VERSION ""

NS_ :

BS_:

BU_: Vector__XXX

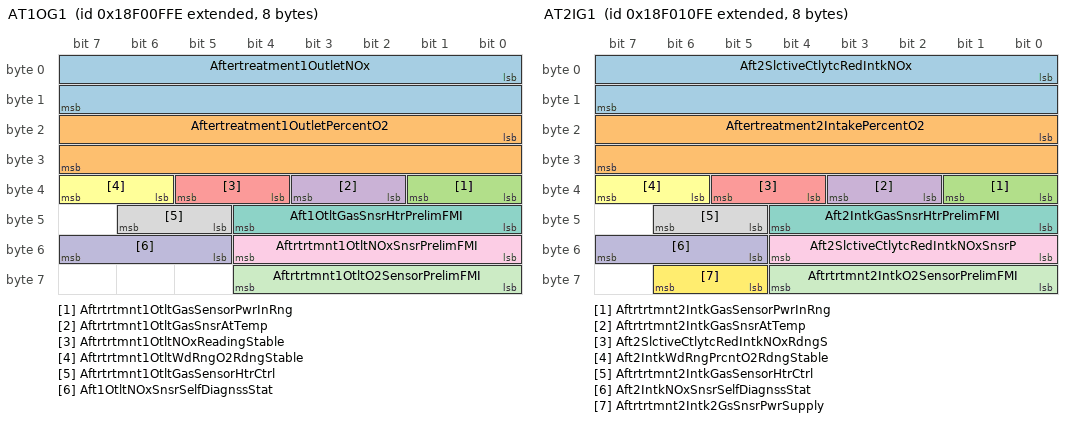
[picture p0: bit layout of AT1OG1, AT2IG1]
BO_ 2565869566 AT1OG1: 8 Vector__XXX
SG_ Aftertreatment1OutletNOx : 0|16@1+ (0.05,-200) [-200|3012.75] "ppm" Vector__XXX
SG_ Aftertreatment1OutletPercentO2 : 16|16@1+ (0.000514,-12) [-12|21.02707] "%" Vector__XXX
SG_ Aftrtrtmnt1OtltGasSensorPwrInRng : 32|2@1+ (1,0) [0|3] "" Vector__XXX
SG_ Aftrtrtmnt1OtltGasSnsrAtTemp : 34|2@1+ (1,0) [0|3] "" Vector__XXX
SG_ Aftrtrtmnt1OtltNOxReadingStable : 36|2@1+ (1,0) [0|3] "" Vector__XXX
SG_ Aftrtrtmnt1OtltWdRngO2RdngStable : 38|2@1+ (1,0) [0|3] "" Vector__XXX
SG_ Aft1OtltGasSnsrHtrPrelimFMI : 40|5@1+ (1,0) [0|31] "" Vector__XXX
SG_ Aftrtrtmnt1OtltGasSensorHtrCtrl : 45|2@1+ (1,0) [0|3] "" Vector__XXX
SG_ Aftrtrtmnt1OtltNOxSnsrPrelimFMI : 48|5@1+ (1,0) [0|31] "" Vector__XXX
SG_ Aft1OtltNOxSnsrSelfDiagnssStat : 53|3@1+ (1,0) [0|7] "" Vector__XXX
SG_ Aftrtrtmnt1OtltO2SensorPrelimFMI : 56|5@1+ (1,0) [0|31] "" Vector__XXX

BO_ 2565869822 AT2IG1: 8 Vector__XXX
SG_ Aft2SlctiveCtlytcRedIntkNOx : 0|16@1+ (0.05,-200) [-200|3012.75] "ppm" Vector__XXX
SG_ Aftertreatment2IntakePercentO2 : 16|16@1+ (0.000514,-12) [-12|21.02707] "%" Vector__XXX
SG_ Aftrtrtmnt2IntkGasSensorPwrInRng : 32|2@1+ (1,0) [0|3] "" Vector__XXX
SG_ Aftrtrtmnt2IntkGasSnsrAtTemp : 34|2@1+ (1,0) [0|3] "" Vector__XXX
SG_ Aft2SlctiveCtlytcRedIntkNOxRdngS : 36|2@1+ (1,0) [0|3] "" Vector__XXX
SG_ Aft2IntkWdRngPrcntO2RdngStable : 38|2@1+ (1,0) [0|3] "" Vector__XXX
SG_ Aft2IntkGasSnsrHtrPrelimFMI : 40|5@1+ (1,0) [0|31] "" Vector__XXX
SG_ Aftrtrtmnt2IntkGasSensorHtrCtrl : 45|2@1+ (1,0) [0|3] "" Vector__XXX
SG_ Aft2SlctiveCtlytcRedIntkNOxSnsrP : 48|5@1+ (1,0) [0|31] "" Vector__XXX
SG_ Aft2IntkNOxSnsrSelfDiagnssStat : 53|3@1+ (1,0) [0|7] "" Vector__XXX
SG_ Aftrtrtmnt2IntkO2SensorPrelimFMI : 56|5@1+ (1,0) [0|31] "" Vector__XXX
SG_ Aftrtrtmnt2Intk2GsSnsrPwrSupply : 61|2@1+ (1,0) [0|3] "" Vector__XXX

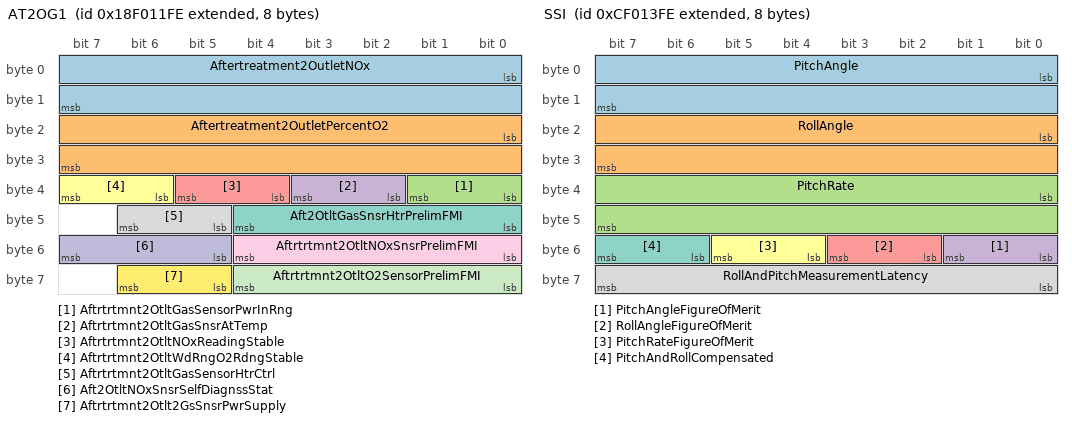
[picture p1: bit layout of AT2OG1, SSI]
BO_ 2565870078 AT2OG1: 8 Vector__XXX
SG_ Aftertreatment2OutletNOx : 0|16@1+ (0.05,-200) [-200|3012.75] "ppm" Vector__XXX
SG_ Aftertreatment2OutletPercentO2 : 16|16@1+ (0.000514,-12) [-12|21.02707] "%" Vector__XXX
SG_ Aftrtrtmnt2OtltGasSensorPwrInRng : 32|2@1+ (1,0) [0|3] "" Vector__XXX
SG_ Aftrtrtmnt2OtltGasSnsrAtTemp : 34|2@1+ (1,0) [0|3] "" Vector__XXX
SG_ Aftrtrtmnt2OtltNOxReadingStable : 36|2@1+ (1,0) [0|3] "" Vector__XXX
SG_ Aftrtrtmnt2OtltWdRngO2RdngStable : 38|2@1+ (1,0) [0|3] "" Vector__XXX
SG_ Aft2OtltGasSnsrHtrPrelimFMI : 40|5@1+ (1,0) [0|31] "" Vector__XXX
SG_ Aftrtrtmnt2OtltGasSensorHtrCtrl : 45|2@1+ (1,0) [0|3] "" Vector__XXX
SG_ Aftrtrtmnt2OtltNOxSnsrPrelimFMI : 48|5@1+ (1,0) [0|31] "" Vector__XXX
SG_ Aft2OtltNOxSnsrSelfDiagnssStat : 53|3@1+ (1,0) [0|7] "" Vector__XXX
SG_ Aftrtrtmnt2OtltO2SensorPrelimFMI : 56|5@1+ (1,0) [0|31] "" Vector__XXX
SG_ Aftrtrtmnt2Otlt2GsSnsrPwrSupply : 61|2@1+ (1,0) [0|3] "" Vector__XXX

BO_ 2565870334 FWSS1: 8 Vector__XXX
SG_ FifthWheelVerticalForce : 0|16@1+ (5,0) [0|321275] "N" Vector__XXX
SG_ FifthWheelDrawbarForce : 16|16@1+ (10,-320000) [-320000|322550] "N" Vector__XXX
SG_ FifthWheelRollMoment : 32|16@1+ (10,-320000) [-320000|322550] "N" Vector__XXX
SG_ FifthWheelRollWarningIndicator : 48|2@1+ (1,0) [0|3] "" Vector__XXX

BO_ 2364543998 SSI: 8 Vector__XXX
SG_ PitchAngle : 0|16@1+ (0.002,-64) [-64|64.51] "deg" Vector__XXX
SG_ RollAngle : 16|16@1+ (0.002,-64) [-64|64.51] "deg" Vector__XXX
SG_ PitchRate : 32|16@1+ (0.002,-64) [-64|64.51] "deg/s" Vector__XXX
SG_ PitchAngleFigureOfMerit : 48|2@1+ (1,0) [0|3] "" Vector__XXX
SG_ RollAngleFigureOfMerit : 50|2@1+ (1,0) [0|3] "" Vector__XXX
SG_ PitchRateFigureOfMerit : 52|2@1+ (1,0) [0|3] "" Vector__XXX
SG_ PitchAndRollCompensated : 54|2@1+ (1,0) [0|3] "" Vector__XXX
SG_ RollAndPitchMeasurementLatency : 56|8@1+ (0.5,0) [0|125] "ms" Vector__XXX

BO_ 2364544254 BI: 8 Vector__XXX
SG_ RelativeBladeHeight : 0|16@1+ (0.1,-3200) [-3200|3225.5] "mm" Vector__XXX
SG_ BladeRotationAngle : 16|16@1+ (0.0078125,-200) [-200|301.99] "deg" Vector__XXX
SG_ RelBldHghtAndBldRotAglMeasureLat : 32|8@1+ (0.5,0) [0|125] "ms" Vector__XXX
SG_ RelativeBladeHeightFigureOfMerit : 40|2@1+ (1,0) [0|3] "" Vector__XXX
SG_ BladeRotationAngleFigureOfMerit : 42|2@1+ (1,0) [0|3] "" Vector__XXX

BO_ 2364544510 RGTACRP: 8 Vector__XXX
SG_ RequestedGenTotalACReActvPower : 0|32@1+ (1,-2000000000) [-2000000000|2211081215] "VA" Vector__XXX
SG_ RequestedGenOverallPowerFactor : 32|16@1+ (6.103515625E-005,-1) [-1|2.921814] "" Vector__XXX
SG_ RqedGenOverallPwrFactorLagging : 48|2@1+ (1,0) [0|3] "" Vector__XXX

BO_ 2364544766 CCS: 8 Vector__XXX
SG_ EngineCylinder1CombustionStatus : 0|2@1+ (1,0) [0|3] "" Vector__XXX
SG_ EngineCylinder2CombustionStatus : 2|2@1+ (1,0) [0|3] "" Vector__XXX
SG_ EngineCylinder3CombustionStatus : 4|2@1+ (1,0) [0|3] "" Vector__XXX
SG_ EngineCylinder4CombustionStatus : 6|2@1+ (1,0) [0|3] "" Vector__XXX
SG_ EngineCylinder5CombustionStatus : 8|2@1+ (1,0) [0|3] "" Vector__XXX
SG_ EngineCylinder6CombustionStatus : 10|2@1+ (1,0) [0|3] "" Vector__XXX
SG_ EngineCylinder7CombustionStatus : 12|2@1+ (1,0) [0|3] "" Vector__XXX
SG_ EngineCylinder8CombustionStatus : 14|2@1+ (1,0) [0|3] "" Vector__XXX
SG_ EngineCylinder9CombustionStatus : 16|2@1+ (1,0) [0|3] "" Vector__XXX
SG_ EngineCylinder10CombustionStatus : 18|2@1+ (1,0) [0|3] "" Vector__XXX
SG_ EngineCylinder11CombustionStatus : 20|2@1+ (1,0) [0|3] "" Vector__XXX
SG_ EngineCylinder12CombustionStatus : 22|2@1+ (1,0) [0|3] "" Vector__XXX
SG_ EngineCylinder13CombustionStatus : 24|2@1+ (1,0) [0|3] "" Vector__XXX
SG_ EngineCylinder14CombustionStatus : 26|2@1+ (1,0) [0|3] "" Vector__XXX
SG_ EngineCylinder15CombustionStatus : 28|2@1+ (1,0) [0|3] "" Vector__XXX
SG_ EngineCylinder16CombustionStatus : 30|2@1+ (1,0) [0|3] "" Vector__XXX
SG_ EngineCylinder17CombustionStatus : 32|2@1+ (1,0) [0|3] "" Vector__XXX
SG_ EngineCylinder18CombustionStatus : 34|2@1+ (1,0) [0|3] "" Vector__XXX
SG_ EngineCylinder19CombustionStatus : 36|2@1+ (1,0) [0|3] "" Vector__XXX
SG_ EngineCylinder20CombustionStatus : 38|2@1+ (1,0) [0|3] "" Vector__XXX
SG_ EngineCylinder21CombustionStatus : 40|2@1+ (1,0) [0|3] "" Vector__XXX
SG_ EngineCylinder22CombustionStatus : 42|2@1+ (1,0) [0|3] "" Vector__XXX
SG_ EngineCylinder23CombustionStatus : 44|2@1+ (1,0) [0|3] "" Vector__XXX
SG_ EngineCylinder24CombustionStatus : 46|2@1+ (1,0) [0|3] "" Vector__XXX

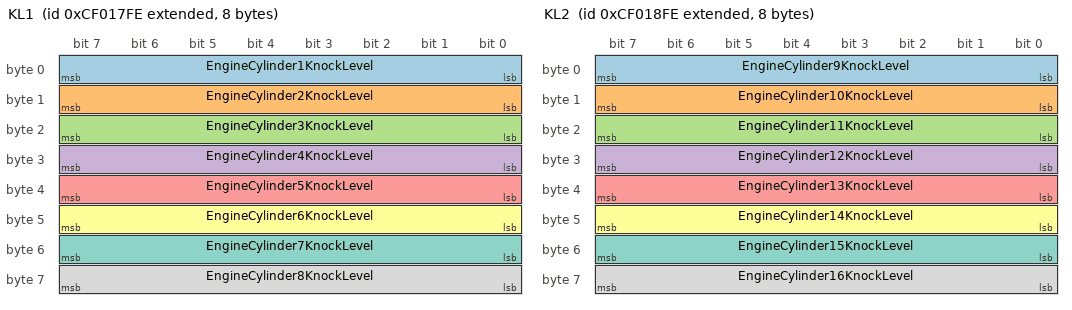
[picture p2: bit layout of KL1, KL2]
BO_ 2364545022 KL1: 8 Vector__XXX
SG_ EngineCylinder1KnockLevel : 0|8@1+ (1,0) [0|250] "%" Vector__XXX
SG_ EngineCylinder2KnockLevel : 8|8@1+ (1,0) [0|250] "%" Vector__XXX
SG_ EngineCylinder3KnockLevel : 16|8@1+ (1,0) [0|250] "%" Vector__XXX
SG_ EngineCylinder4KnockLevel : 24|8@1+ (1,0) [0|250] "%" Vector__XXX
SG_ EngineCylinder5KnockLevel : 32|8@1+ (1,0) [0|250] "%" Vector__XXX
SG_ EngineCylinder6KnockLevel : 40|8@1+ (1,0) [0|250] "%" Vector__XXX
SG_ EngineCylinder7KnockLevel : 48|8@1+ (1,0) [0|250] "%" Vector__XXX
SG_ EngineCylinder8KnockLevel : 56|8@1+ (1,0) [0|250] "%" Vector__XXX

BO_ 2364545278 KL2: 8 Vector__XXX
SG_ EngineCylinder9KnockLevel : 0|8@1+ (1,0) [0|250] "%" Vector__XXX
SG_ EngineCylinder10KnockLevel : 8|8@1+ (1,0) [0|250] "%" Vector__XXX
SG_ EngineCylinder11KnockLevel : 16|8@1+ (1,0) [0|250] "%" Vector__XXX
SG_ EngineCylinder12KnockLevel : 24|8@1+ (1,0) [0|250] "%" Vector__XXX
SG_ EngineCylinder13KnockLevel : 32|8@1+ (1,0) [0|250] "%" Vector__XXX
SG_ EngineCylinder14KnockLevel : 40|8@1+ (1,0) [0|250] "%" Vector__XXX
SG_ EngineCylinder15KnockLevel : 48|8@1+ (1,0) [0|250] "%" Vector__XXX
SG_ EngineCylinder16KnockLevel : 56|8@1+ (1,0) [0|250] "%" Vector__XXX

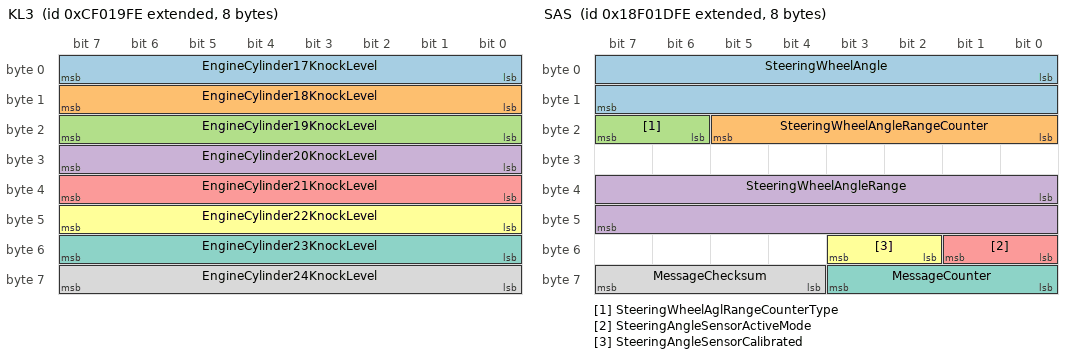
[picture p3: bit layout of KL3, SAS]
BO_ 2364545534 KL3: 8 Vector__XXX
SG_ EngineCylinder17KnockLevel : 0|8@1+ (1,0) [0|250] "%" Vector__XXX
SG_ EngineCylinder18KnockLevel : 8|8@1+ (1,0) [0|250] "%" Vector__XXX
SG_ EngineCylinder19KnockLevel : 16|8@1+ (1,0) [0|250] "%" Vector__XXX
SG_ EngineCylinder20KnockLevel : 24|8@1+ (1,0) [0|250] "%" Vector__XXX
SG_ EngineCylinder21KnockLevel : 32|8@1+ (1,0) [0|250] "%" Vector__XXX
SG_ EngineCylinder22KnockLevel : 40|8@1+ (1,0) [0|250] "%" Vector__XXX
SG_ EngineCylinder23KnockLevel : 48|8@1+ (1,0) [0|250] "%" Vector__XXX
SG_ EngineCylinder24KnockLevel : 56|8@1+ (1,0) [0|250] "%" Vector__XXX

BO_ 2431654654 TFAC: 8 Vector__XXX
SG_ EngineThrottleActr1ControlCmd : 0|16@1+ (0.0025,0) [0|160.6375] "%" Vector__XXX
SG_ EngineThrottleActr2ControlCmd : 16|16@1+ (0.0025,0) [0|160.6375] "%" Vector__XXX
SG_ EngineFuelActr1ControlCommand : 32|16@1+ (0.0025,0) [0|160.6375] "%" Vector__XXX
SG_ EngineFuelActr2ControlCommand : 48|16@1+ (0.0025,0) [0|160.6375] "%" Vector__XXX

BO_ 2364546302 RGAAC: 8 Vector__XXX
SG_ RqedGenAvrgLineLineACRMSVoltage : 0|32@1+ (0.0078125,0) [0|32899071] "V" Vector__XXX

BO_ 2565873150 SAS: 8 Vector__XXX
SG_ SteeringWheelAngle : 0|16@1+ (0.0009765625,-31.374) [-31.374|31.374] "rad" Vector__XXX
SG_ SteeringWheelAngleRangeCounter : 16|6@1+ (1,-32) [-32|29] "" Vector__XXX
SG_ SteeringWheelAglRangeCounterType : 22|2@1+ (1,0) [0|3] "" Vector__XXX
SG_ SteeringWheelAngleRange : 32|16@1+ (0.0009765625,-31.374) [-31.374|31.374] "rad" Vector__XXX
SG_ SteeringAngleSensorActiveMode : 48|2@1+ (1,0) [0|3] "" Vector__XXX
SG_ SteeringAngleSensorCalibrated : 50|2@1+ (1,0) [0|3] "" Vector__XXX
SG_ MessageCounter : 56|4@1+ (1,0) [0|15] "" Vector__XXX
SG_ MessageChecksum : 60|4@1+ (1,0) [0|15] "" Vector__XXX

BO_ 2364546814 GC2: 8 Vector__XXX
SG_ GeneratorGoverningBias : 0|16@1+ (0.004,-125) [-125|132.02] "%" Vector__XXX
SG_ EngineSelfInducedDerateInhibit : 16|2@1+ (1,0) [0|3] "" Vector__XXX
SG_ EngineLoadSetpointRequest : 24|16@1+ (0.5,0) [0|32127.5] "kW" Vector__XXX

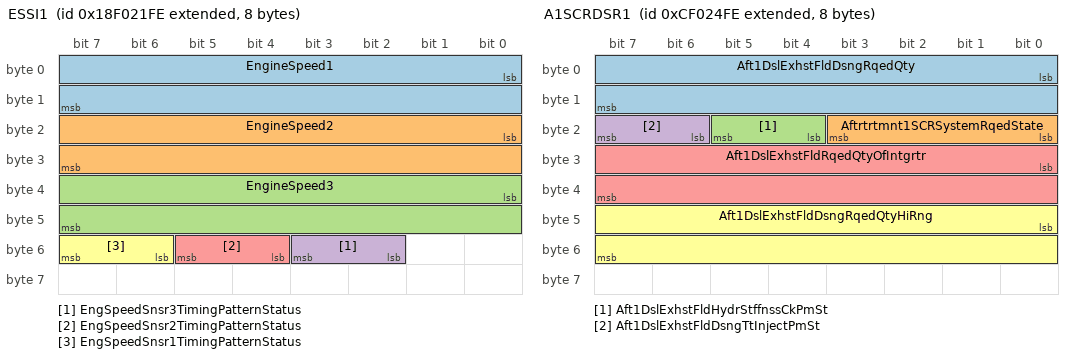
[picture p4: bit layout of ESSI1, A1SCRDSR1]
BO_ 2565874174 ESSI1: 8 Vector__XXX
SG_ EngineSpeed1 : 0|16@1+ (0.5,0) [0|32127.5] "rpm" Vector__XXX
SG_ EngineSpeed2 : 16|16@1+ (0.5,0) [0|32127.5] "rpm" Vector__XXX
SG_ EngineSpeed3 : 32|16@1+ (0.5,0) [0|32127.5] "rpm" Vector__XXX
SG_ EngSpeedSnsr3TimingPatternStatus : 50|2@1+ (1,0) [0|3] "" Vector__XXX
SG_ EngSpeedSnsr2TimingPatternStatus : 52|2@1+ (1,0) [0|3] "" Vector__XXX
SG_ EngSpeedSnsr1TimingPatternStatus : 54|2@1+ (1,0) [0|3] "" Vector__XXX

BO_ 2364548094 A1SCRDSI1: 8 Vector__XXX
SG_ Aft1DslExhstFldActlDsngQty : 0|16@1+ (0.3,0) [0|19276.5] "g/h" Vector__XXX
SG_ Aftertreatment1SCRSystemState : 16|4@1+ (1,0) [0|15] "" Vector__XXX
SG_ Aftertreatment1SCRSystem2State : 20|4@1+ (1,0) [0|15] "" Vector__XXX
SG_ Aft1DslExhstFldActlQtyOfIntgrtr : 24|16@1+ (0.1,0) [0|6425.5] "g" Vector__XXX
SG_ Aft1DslExhstFldDoserAbsPress : 40|8@1+ (8,0) [0|2000] "kPa" Vector__XXX
SG_ Aft1DslExhstFldActlDsngQtyHiRng : 48|16@1+ (0.05,0) [0|3212.75] "g/m" Vector__XXX

BO_ 2364548350 A1SCRDSR1: 8 Vector__XXX
SG_ Aft1DslExhstFldDsngRqedQty : 0|16@1+ (0.3,0) [0|19276.5] "g/h" Vector__XXX
SG_ Aftrtrtmnt1SCRSystemRqedState : 16|4@1+ (1,0) [0|15] "" Vector__XXX
SG_ Aft1DslExhstFldHydrStffnssCkPmSt : 20|2@1+ (1,0) [0|3] "" Vector__XXX
SG_ Aft1DslExhstFldDsngTtInjectPmSt : 22|2@1+ (1,0) [0|3] "" Vector__XXX
SG_ Aft1DslExhstFldRqedQtyOfIntgrtr : 24|16@1+ (0.1,0) [0|6425.5] "g" Vector__XXX
SG_ Aft1DslExhstFldDsngRqedQtyHiRng : 40|16@1+ (0.05,0) [0|3212.75] "g/m" Vector__XXX

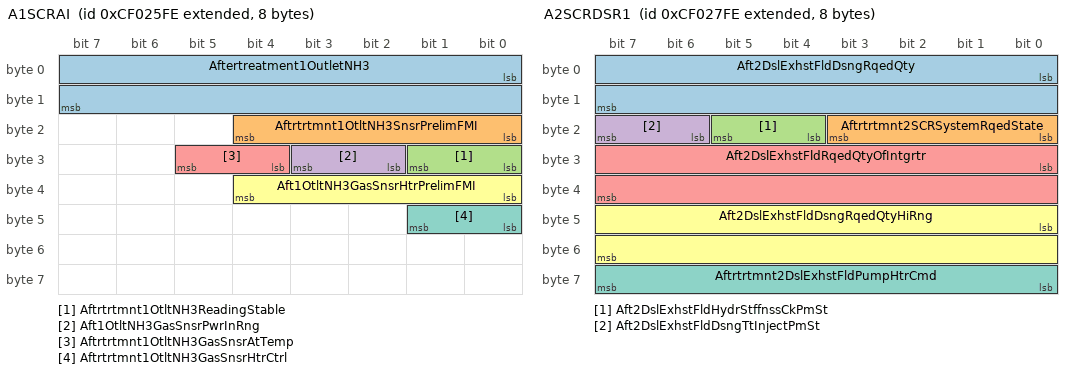
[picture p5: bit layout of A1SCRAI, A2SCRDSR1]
BO_ 2364548606 A1SCRAI: 8 Vector__XXX
SG_ Aftertreatment1OutletNH3 : 0|16@1+ (0.05,-200) [-200|3012.75] "ppm" Vector__XXX
SG_ Aftrtrtmnt1OtltNH3SnsrPrelimFMI : 16|5@1+ (1,0) [0|31] "" Vector__XXX
SG_ Aftrtrtmnt1OtltNH3ReadingStable : 24|2@1+ (1,0) [0|3] "" Vector__XXX
SG_ Aft1OtltNH3GasSnsrPwrInRng : 26|2@1+ (1,0) [0|3] "" Vector__XXX
SG_ Aftrtrtmnt1OtltNH3GasSnsrAtTemp : 28|2@1+ (1,0) [0|3] "" Vector__XXX
SG_ Aft1OtltNH3GasSnsrHtrPrelimFMI : 32|5@1+ (1,0) [0|31] "" Vector__XXX
SG_ Aftrtrtmnt1OtltNH3GasSnsrHtrCtrl : 40|2@1+ (1,0) [0|3] "" Vector__XXX

BO_ 2364548862 A2SCRDSI1: 8 Vector__XXX
SG_ Aft2DslExhstFldActlDsngQty : 0|16@1+ (0.3,0) [0|19276.5] "g/h" Vector__XXX
SG_ Aftertreatment2SCRSystemState : 16|4@1+ (1,0) [0|15] "" Vector__XXX
SG_ Aftertreatment2SCRSystem2State : 20|4@1+ (1,0) [0|15] "" Vector__XXX
SG_ Aft2DslExhstFldActlQtyOfIntgrtr : 24|16@1+ (0.1,0) [0|6425.5] "g" Vector__XXX
SG_ Aft2DslExhstFldDsngAbsPress : 40|8@1+ (8,0) [0|2000] "kPa" Vector__XXX
SG_ Aft2DslExhstFldActlDsngQtyHiRng : 48|16@1+ (0.05,0) [0|3212.75] "g/m" Vector__XXX

BO_ 2364549118 A2SCRDSR1: 8 Vector__XXX
SG_ Aft2DslExhstFldDsngRqedQty : 0|16@1+ (0.3,0) [0|19276.5] "g/h" Vector__XXX
SG_ Aftrtrtmnt2SCRSystemRqedState : 16|4@1+ (1,0) [0|15] "" Vector__XXX
SG_ Aft2DslExhstFldHydrStffnssCkPmSt : 20|2@1+ (1,0) [0|3] "" Vector__XXX
SG_ Aft2DslExhstFldDsngTtInjectPmSt : 22|2@1+ (1,0) [0|3] "" Vector__XXX
SG_ Aft2DslExhstFldRqedQtyOfIntgrtr : 24|16@1+ (0.1,0) [0|6425.5] "g" Vector__XXX
SG_ Aft2DslExhstFldDsngRqedQtyHiRng : 40|16@1+ (0.05,0) [0|3212.75] "g/m" Vector__XXX
SG_ Aftrtrtmnt2DslExhstFldPumpHtrCmd : 56|8@1+ (0.4,0) [0|100] "%" Vector__XXX

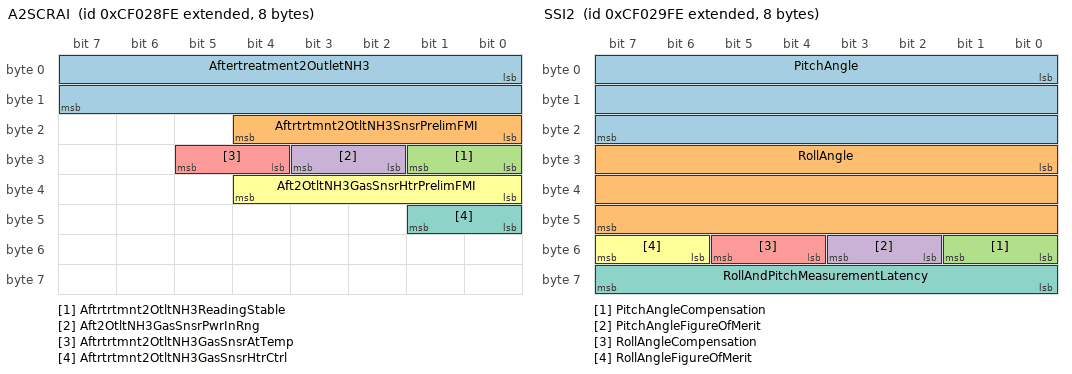
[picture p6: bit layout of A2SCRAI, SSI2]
BO_ 2364549374 A2SCRAI: 8 Vector__XXX
SG_ Aftertreatment2OutletNH3 : 0|16@1+ (0.05,-200) [-200|3012.75] "ppm" Vector__XXX
SG_ Aftrtrtmnt2OtltNH3SnsrPrelimFMI : 16|5@1+ (1,0) [0|31] "" Vector__XXX
SG_ Aftrtrtmnt2OtltNH3ReadingStable : 24|2@1+ (1,0) [0|3] "" Vector__XXX
SG_ Aft2OtltNH3GasSnsrPwrInRng : 26|2@1+ (1,0) [0|3] "" Vector__XXX
SG_ Aftrtrtmnt2OtltNH3GasSnsrAtTemp : 28|2@1+ (1,0) [0|3] "" Vector__XXX
SG_ Aft2OtltNH3GasSnsrHtrPrelimFMI : 32|5@1+ (1,0) [0|31] "" Vector__XXX
SG_ Aftrtrtmnt2OtltNH3GasSnsrHtrCtrl : 40|2@1+ (1,0) [0|3] "" Vector__XXX

BO_ 2364549630 SSI2: 8 Vector__XXX
SG_ PitchAngle : 0|24@1+ (3.0517578125E-005,-250) [-250|252] "deg" Vector__XXX
SG_ RollAngle : 24|24@1+ (3.0517578125E-005,-250) [-250|252] "deg" Vector__XXX
SG_ PitchAngleCompensation : 48|2@1+ (1,0) [0|3] "" Vector__XXX
SG_ PitchAngleFigureOfMerit : 50|2@1+ (1,0) [0|3] "" Vector__XXX
SG_ RollAngleCompensation : 52|2@1+ (1,0) [0|3] "" Vector__XXX
SG_ RollAngleFigureOfMerit : 54|2@1+ (1,0) [0|3] "" Vector__XXX
SG_ RollAndPitchMeasurementLatency : 56|8@1+ (0.5,0) [0|125] "ms" Vector__XXX

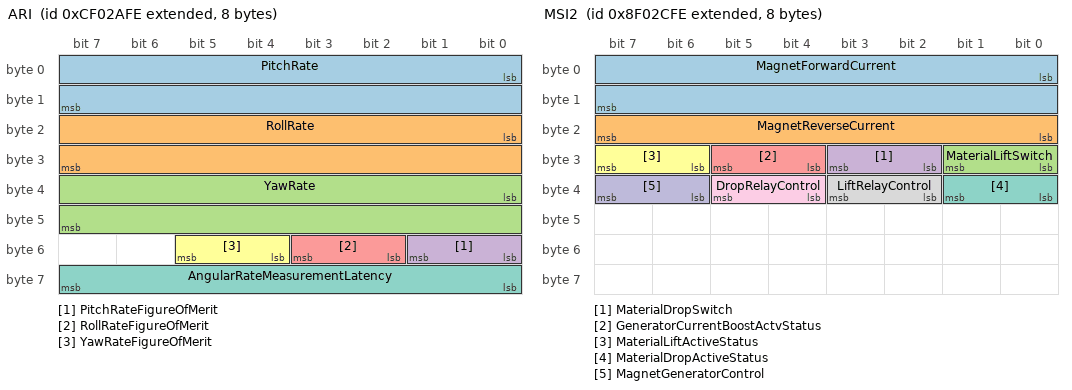
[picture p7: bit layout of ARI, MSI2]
BO_ 2364549886 ARI: 8 Vector__XXX
SG_ PitchRate : 0|16@1+ (0.0078125,-250) [-250|250.992] "deg/s" Vector__XXX
SG_ RollRate : 16|16@1+ (0.0078125,-250) [-250|250.992] "deg/s" Vector__XXX
SG_ YawRate : 32|16@1+ (0.0078125,-250) [-250|250.992] "deg/s" Vector__XXX
SG_ PitchRateFigureOfMerit : 48|2@1+ (1,0) [0|3] "" Vector__XXX
SG_ RollRateFigureOfMerit : 50|2@1+ (1,0) [0|3] "" Vector__XXX
SG_ YawRateFigureOfMerit : 52|2@1+ (1,0) [0|3] "" Vector__XXX
SG_ AngularRateMeasurementLatency : 56|8@1+ (0.5,0) [0|125] "ms" Vector__XXX

BO_ 2163223550 CN: 8 Vector__XXX
SG_ CrashType : 0|5@1+ (1,0) [0|31] "" Vector__XXX
SG_ CrashCounter : 56|4@1+ (1,0) [0|15] "" Vector__XXX
SG_ CrashChecksum : 60|4@1+ (1,0) [0|15] "" Vector__XXX

BO_ 2297441534 MSI2: 8 Vector__XXX
SG_ MagnetForwardCurrent : 0|16@1+ (1,0) [0|64255] "A" Vector__XXX
SG_ MagnetReverseCurrent : 16|8@1+ (1,0) [0|250] "A" Vector__XXX
SG_ MaterialLiftSwitch : 24|2@1+ (1,0) [0|3] "" Vector__XXX
SG_ MaterialDropSwitch : 26|2@1+ (1,0) [0|3] "" Vector__XXX
SG_ GeneratorCurrentBoostActvStatus : 28|2@1+ (1,0) [0|3] "" Vector__XXX
SG_ MaterialLiftActiveStatus : 30|2@1+ (1,0) [0|3] "" Vector__XXX
SG_ MaterialDropActiveStatus : 32|2@1+ (1,0) [0|3] "" Vector__XXX
SG_ LiftRelayControl : 34|2@1+ (1,0) [0|3] "" Vector__XXX
SG_ DropRelayControl : 36|2@1+ (1,0) [0|3] "" Vector__XXX
SG_ MagnetGeneratorControl : 38|2@1+ (1,0) [0|3] "" Vector__XXX

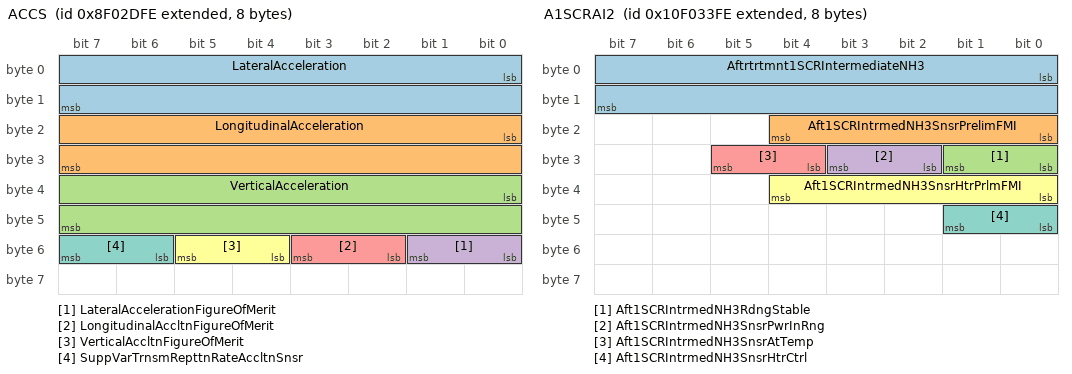
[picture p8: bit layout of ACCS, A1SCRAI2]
BO_ 2297441790 ACCS: 8 Vector__XXX
SG_ LateralAcceleration : 0|16@1+ (0.01,-320) [-320|322.55] "m/s^2" Vector__XXX
SG_ LongitudinalAcceleration : 16|16@1+ (0.01,-320) [-320|322.55] "m/s^2" Vector__XXX
SG_ VerticalAcceleration : 32|16@1+ (0.01,-320) [-320|322.55] "m/s^2" Vector__XXX
SG_ LateralAccelerationFigureOfMerit : 48|2@1+ (1,0) [0|3] "" Vector__XXX
SG_ LongitudinalAccltnFigureOfMerit : 50|2@1+ (1,0) [0|3] "" Vector__XXX
SG_ VerticalAccltnFigureOfMerit : 52|2@1+ (1,0) [0|3] "" Vector__XXX
SG_ SuppVarTrnsmRepttnRateAccltnSnsr : 54|2@1+ (1,0) [0|3] "" Vector__XXX

BO_ 2565877502 ETCC: 8 Vector__XXX
SG_ EngTurbochargerWastegateActr1Cmd : 0|16@1+ (0.0025,0) [0|160.6375] "%" Vector__XXX
SG_ EngTurbochargerWastegateActr2Cmd : 16|16@1+ (0.0025,0) [0|160.6375] "%" Vector__XXX
SG_ EngExhstPressureRegulatorCtrlCmd : 32|16@1+ (0.0025,0) [0|160.6375] "%" Vector__XXX
SG_ EngTurboCmprssorBlowoffActr1Cmd : 48|16@1+ (0.0025,0) [0|160.6375] "%" Vector__XXX

BO_ 2364551166 AEBS1: 8 Vector__XXX
SG_ AdvEmergencyBrakingSystemState : 0|4@1+ (1,0) [0|15] "" Vector__XXX
SG_ CollisionWarningLevel : 4|4@1+ (1,0) [0|15] "" Vector__XXX
SG_ RelvntObjDetctAdvEmrgncyBrkngSys : 8|3@1+ (1,0) [0|7] "" Vector__XXX
SG_ BendOffProbabilityOfRelevantObj : 11|3@1+ (1,0) [0|7] "" Vector__XXX
SG_ TimeToCollsnWithRelevantObject : 16|8@1+ (0.05,0) [0|12.5] "s" Vector__XXX

BO_ 2364551422 WS: 8 Vector__XXX
SG_ WirelessRollingMessageCounter : 0|16@1+ (1,0) [0|64255] "" Vector__XXX
SG_ TransmitterCommandState : 20|4@1+ (1,0) [0|15] "" Vector__XXX
SG_ TransmitterID1 : 24|24@1+ (1,0) [0|16449635] "" Vector__XXX
SG_ WirelessSignalStrength1 : 48|8@1+ (0.5,-125) [-125|0] "dBm" Vector__XXX

BO_ 2230333950 WAND: 8 Vector__XXX
SG_ WandAngle : 0|16@1+ (0.002,-64) [-64|64.51] "deg" Vector__XXX
SG_ WandSensorFigureOfMerit : 16|2@1+ (1,0) [0|3] "" Vector__XXX

BO_ 2230334206 LDISP: 8 Vector__XXX
SG_ MeasuredLinearDisplacement : 0|16@1+ (0.1,0) [0|6425.5] "mm" Vector__XXX
SG_ LnrDisplacmntSnsrSnsrFigOfMerit : 16|2@1+ (1,0) [0|3] "" Vector__XXX

BO_ 2431661054 A1SCRAI2: 8 Vector__XXX
SG_ Aftrtrtmnt1SCRIntermediateNH3 : 0|16@1+ (0.1,-200) [-200|6225.5] "ppm" Vector__XXX
SG_ Aft1SCRIntrmedNH3SnsrPrelimFMI : 16|5@1+ (1,0) [0|31] "" Vector__XXX
SG_ Aft1SCRIntrmedNH3RdngStable : 24|2@1+ (1,0) [0|3] "" Vector__XXX
SG_ Aft1SCRIntrmedNH3SnsrPwrInRng : 26|2@1+ (1,0) [0|3] "" Vector__XXX
SG_ Aft1SCRIntrmedNH3SnsrAtTemp : 28|2@1+ (1,0) [0|3] "" Vector__XXX
SG_ Aft1SCRIntrmedNH3SnsrHtrPrlmFMI : 32|5@1+ (1,0) [0|31] "" Vector__XXX
SG_ Aft1SCRIntrmedNH3SnsrHtrCtrl : 40|2@1+ (1,0) [0|3] "" Vector__XXX

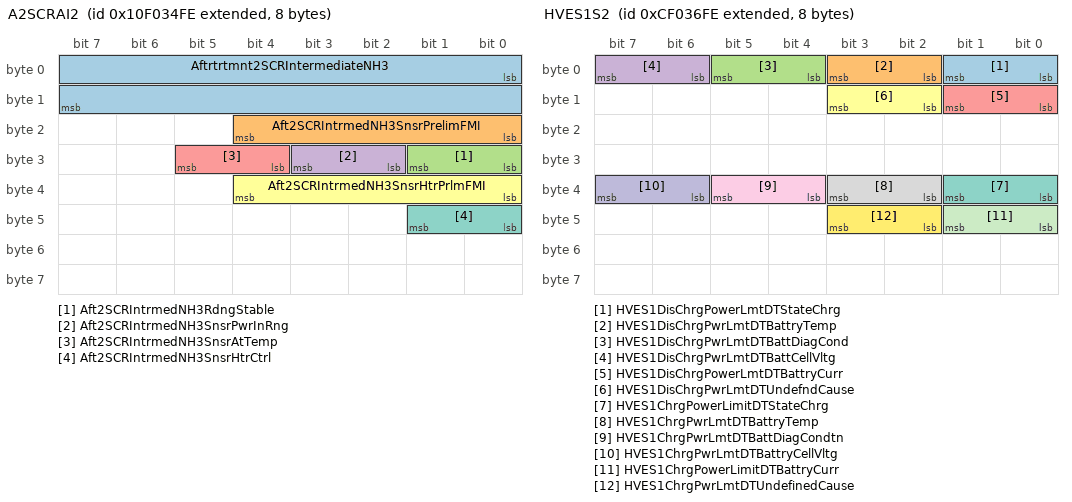
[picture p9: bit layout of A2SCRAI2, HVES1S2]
BO_ 2431661310 A2SCRAI2: 8 Vector__XXX
SG_ Aftrtrtmnt2SCRIntermediateNH3 : 0|16@1+ (0.1,-200) [-200|6225.5] "ppm" Vector__XXX
SG_ Aft2SCRIntrmedNH3SnsrPrelimFMI : 16|5@1+ (1,0) [0|31] "" Vector__XXX
SG_ Aft2SCRIntrmedNH3RdngStable : 24|2@1+ (1,0) [0|3] "" Vector__XXX
SG_ Aft2SCRIntrmedNH3SnsrPwrInRng : 26|2@1+ (1,0) [0|3] "" Vector__XXX
SG_ Aft2SCRIntrmedNH3SnsrAtTemp : 28|2@1+ (1,0) [0|3] "" Vector__XXX
SG_ Aft2SCRIntrmedNH3SnsrHtrPrlmFMI : 32|5@1+ (1,0) [0|31] "" Vector__XXX
SG_ Aft2SCRIntrmedNH3SnsrHtrCtrl : 40|2@1+ (1,0) [0|3] "" Vector__XXX

BO_ 2364552958 HVES1S2: 8 Vector__XXX
SG_ HVES1DisChrgPowerLmtDTStateChrg : 0|2@1+ (1,0) [0|3] "" Vector__XXX
SG_ HVES1DisChrgPwrLmtDTBattryTemp : 2|2@1+ (1,0) [0|3] "" Vector__XXX
SG_ HVES1DisChrgPwrLmtDTBattDiagCond : 4|2@1+ (1,0) [0|3] "" Vector__XXX
SG_ HVES1DisChrgPwrLmtDTBattCellVltg : 6|2@1+ (1,0) [0|3] "" Vector__XXX
SG_ HVES1DisChrgPowerLmtDTBattryCurr : 8|2@1+ (1,0) [0|3] "" Vector__XXX
SG_ HVES1DisChrgPwrLmtDTUndefndCause : 10|2@1+ (1,0) [0|3] "" Vector__XXX
SG_ HVES1ChrgPowerLimitDTStateChrg : 32|2@1+ (1,0) [0|3] "" Vector__XXX
SG_ HVES1ChrgPwrLmtDTBattryTemp : 34|2@1+ (1,0) [0|3] "" Vector__XXX
SG_ HVES1ChrgPwrLmtDTBattDiagCondtn : 36|2@1+ (1,0) [0|3] "" Vector__XXX
SG_ HVES1ChrgPwrLmtDTBattryCellVltg : 38|2@1+ (1,0) [0|3] "" Vector__XXX
SG_ HVES1ChrgPowerLimitDTBattryCurr : 40|2@1+ (1,0) [0|3] "" Vector__XXX
SG_ HVES1ChrgPwrLmtDTUndefinedCause : 42|2@1+ (1,0) [0|3] "" Vector__XXX

BO_ 2364553214 ETBA1: 8 Vector__XXX
SG_ EngTurboCmprBlowoffActr1PrlmFMI : 0|5@1+ (1,0) [0|31] "" Vector__XXX
SG_ EngTurboCmprBlowoffActr1TempStat : 5|3@1+ (1,0) [0|7] "" Vector__XXX
SG_ EngTurboCmprssorBlowoffActr1Temp : 8|8@1+ (1,-40) [-40|210] "deg C" Vector__XXX
SG_ EngTurboCmprBlowoffActr1DsrdPos : 16|8@1+ (0.4,0) [0|100] "%" Vector__XXX
SG_ EngTurboCmprssorBlowoffActr1Pos : 24|8@1+ (0.4,0) [0|100] "%" Vector__XXX
SG_ EngTurboCmprBlowoffActr1OpStat : 32|4@1+ (1,0) [0|15] "" Vector__XXX

BO_ 2364553470 ETFR: 8 Vector__XXX
SG_ EngGsSubstitutionFuelPrcntageCmd : 0|8@1+ (0.5,0) [0|125] "%" Vector__XXX
SG_ EngineCylinderGasMassFlowRateCmd : 8|16@1+ (6.103515625E-005,0) [0|3.921813965] "kg/s" Vector__XXX
SG_ EngineCylDieselMassFlowRateCmd : 24|16@1+ (6.103515625E-005,0) [0|3.921813965] "kg/s" Vector__XXX
SG_ EngineCylinderTorque : 40|16@1+ (1,0) [0|64255] "Nm" Vector__XXX
SG_ EngineDualFuelModeCommand : 56|2@1+ (1,0) [0|3] "" Vector__XXX

BO_ 2364553726 EASI: 8 Vector__XXX
SG_ EngineDesiredAirFuelRatio : 0|16@1+ (0.001,0) [0|64.255] "" Vector__XXX
SG_ EngineTotalIntakeMassAirFlowRate : 16|16@1+ (0.0009765625,0) [0|62.74902344] "kg/s" Vector__XXX
SG_ EngFuelSys2TtlIntkMassAirFlwRate : 32|16@1+ (0.0009765625,0) [0|62.74902344] "kg/s" Vector__XXX

BO_ 2364553982 ECCI1: 8 Vector__XXX
SG_ EngineCylinder1HeatRelease : 0|16@1+ (0.0001220703125,-1) [-1|6.84362793] "kJ/l" Vector__XXX
SG_ EngineCylinder1PeakPressure : 16|16@1+ (0.0009765625,0) [0|62.74902344] "MPa" Vector__XXX
SG_ EngineCyl1SynchronousKnockLevel : 32|8@1+ (1,0) [0|250] "%" Vector__XXX
SG_ EngCyl1PressureSensorPrelimFMI : 40|5@1+ (1,0) [0|31] "" Vector__XXX
SG_ EngineCyl1LowFrequencyKnockLevel : 48|8@1+ (1,0) [0|250] "%" Vector__XXX
SG_ EngCyl1MaxPressureIncreaseRate : 56|8@1+ (16,0) [0|4000] "kPa/deg crank an" Vector__XXX

BO_ 2364554238 ECCI2: 8 Vector__XXX
SG_ EngineCylinder2HeatRelease : 0|16@1+ (0.0001220703125,-1) [-1|6.84362793] "kJ/l" Vector__XXX
SG_ EngineCylinder2PeakPressure : 16|16@1+ (0.0009765625,0) [0|62.74902344] "MPa" Vector__XXX
SG_ EngineCyl2SynchronousKnockLevel : 32|8@1+ (1,0) [0|250] "%" Vector__XXX
SG_ EngCyl2PressureSensorPrelimFMI : 40|5@1+ (1,0) [0|31] "" Vector__XXX
SG_ EngineCyl2LowFrequencyKnockLevel : 48|8@1+ (1,0) [0|250] "%" Vector__XXX
SG_ EngCyl2MaxPressureIncreaseRate : 56|8@1+ (16,0) [0|4000] "kPa/deg crank an" Vector__XXX

BO_ 2364554494 ECCI3: 8 Vector__XXX
SG_ EngineCylinder3HeatRelease : 0|16@1+ (0.0001220703125,-1) [-1|6.84362793] "kJ/l" Vector__XXX
SG_ EngineCylinder3PeakPressure : 16|16@1+ (0.0009765625,0) [0|62.74902344] "MPa" Vector__XXX
SG_ EngineCyl3SynchronousKnockLevel : 32|8@1+ (1,0) [0|250] "%" Vector__XXX
SG_ EngCyl3PressureSensorPrelimFMI : 40|5@1+ (1,0) [0|31] "" Vector__XXX
SG_ EngineCyl3LowFrequencyKnockLevel : 48|8@1+ (1,0) [0|250] "%" Vector__XXX
SG_ EngCyl3MaxPressureIncreaseRate : 56|8@1+ (16,0) [0|4000] "kPa/deg crank an" Vector__XXX

BO_ 2364554750 ECCI4: 8 Vector__XXX
SG_ EngineCylinder4HeatRelease : 0|16@1+ (0.0001220703125,-1) [-1|6.84362793] "kJ/l" Vector__XXX
SG_ EngineCylinder4PeakPressure : 16|16@1+ (0.0009765625,0) [0|62.74902344] "MPa" Vector__XXX
SG_ EngineCyl4SynchronousKnockLevel : 32|8@1+ (1,0) [0|250] "%" Vector__XXX
SG_ EngCyl4PressureSensorPrelimFMI : 40|5@1+ (1,0) [0|31] "" Vector__XXX
SG_ EngineCyl4LowFrequencyKnockLevel : 48|8@1+ (1,0) [0|250] "%" Vector__XXX
SG_ EngCyl4MaxPressureIncreaseRate : 56|8@1+ (16,0) [0|4000] "kPa/deg crank an" Vector__XXX

BO_ 2364555006 ECCI5: 8 Vector__XXX
SG_ EngineCylinder5HeatRelease : 0|16@1+ (0.0001220703125,-1) [-1|6.84362793] "kJ/l" Vector__XXX
SG_ EngineCylinder5PeakPressure : 16|16@1+ (0.0009765625,0) [0|62.74902344] "MPa" Vector__XXX
SG_ EngineCyl5SynchronousKnockLevel : 32|8@1+ (1,0) [0|250] "%" Vector__XXX
SG_ EngCyl5PressureSensorPrelimFMI : 40|5@1+ (1,0) [0|31] "" Vector__XXX
SG_ EngineCyl5LowFrequencyKnockLevel : 48|8@1+ (1,0) [0|250] "%" Vector__XXX
SG_ EngCyl5MaxPressureIncreaseRate : 56|8@1+ (16,0) [0|4000] "kPa/deg crank an" Vector__XXX

BO_ 2364555262 ECCI6: 8 Vector__XXX
SG_ EngineCylinder6HeatRelease : 0|16@1+ (0.0001220703125,-1) [-1|6.84362793] "kJ/l" Vector__XXX
SG_ EngineCylinder6PeakPressure : 16|16@1+ (0.0009765625,0) [0|62.74902344] "MPa" Vector__XXX
SG_ EngineCyl6SynchronousKnockLevel : 32|8@1+ (1,0) [0|250] "%" Vector__XXX
SG_ EngCyl6PressureSensorPrelimFMI : 40|5@1+ (1,0) [0|31] "" Vector__XXX
SG_ EngineCyl6LowFrequencyKnockLevel : 48|8@1+ (1,0) [0|250] "%" Vector__XXX
SG_ EngCyl6MaxPressureIncreaseRate : 56|8@1+ (16,0) [0|4000] "kPa/deg crank an" Vector__XXX

BO_ 2364555518 ECCI7: 8 Vector__XXX
SG_ EngineCylinder7HeatRelease : 0|16@1+ (0.0001220703125,-1) [-1|6.84362793] "kJ/l" Vector__XXX
SG_ EngineCylinder7PeakPressure : 16|16@1+ (0.0009765625,0) [0|62.74902344] "MPa" Vector__XXX
SG_ EngineCyl7SynchronousKnockLevel : 32|8@1+ (1,0) [0|250] "%" Vector__XXX
SG_ EngCyl7PressureSensorPrelimFMI : 40|5@1+ (1,0) [0|31] "" Vector__XXX
SG_ EngineCyl7LowFrequencyKnockLevel : 48|8@1+ (1,0) [0|250] "%" Vector__XXX
SG_ EngCyl7MaxPressureIncreaseRate : 56|8@1+ (16,0) [0|4000] "kPa/deg crank an" Vector__XXX

BO_ 2364555774 ECCI8: 8 Vector__XXX
SG_ EngineCylinder8HeatRelease : 0|16@1+ (0.0001220703125,-1) [-1|6.84362793] "kJ/l" Vector__XXX
SG_ EngineCylinder8PeakPressure : 16|16@1+ (0.0009765625,0) [0|62.74902344] "MPa" Vector__XXX
SG_ EngineCyl8SynchronousKnockLevel : 32|8@1+ (1,0) [0|250] "%" Vector__XXX
SG_ EngCyl8PressureSensorPrelimFMI : 40|5@1+ (1,0) [0|31] "" Vector__XXX
SG_ EngineCyl8LowFrequencyKnockLevel : 48|8@1+ (1,0) [0|250] "%" Vector__XXX
SG_ EngCyl8MaxPressureIncreaseRate : 56|8@1+ (16,0) [0|4000] "kPa/deg crank an" Vector__XXX

BO_ 2364556030 ECCI9: 8 Vector__XXX
SG_ EngineCylinder9HeatRelease : 0|16@1+ (0.0001220703125,-1) [-1|6.84362793] "kJ/l" Vector__XXX
SG_ EngineCylinder9PeakPressure : 16|16@1+ (0.0009765625,0) [0|62.74902344] "MPa" Vector__XXX
SG_ EngineCyl9SynchronousKnockLevel : 32|8@1+ (1,0) [0|250] "%" Vector__XXX
SG_ EngCyl9PressureSensorPrelimFMI : 40|5@1+ (1,0) [0|31] "" Vector__XXX
SG_ EngineCyl9LowFrequencyKnockLevel : 48|8@1+ (1,0) [0|250] "%" Vector__XXX
SG_ EngCyl9MaxPressureIncreaseRate : 56|8@1+ (16,0) [0|4000] "kPa/deg crank an" Vector__XXX

BO_ 2364556286 ECCI10: 8 Vector__XXX
SG_ EngineCylinder10HeatRelease : 0|16@1+ (0.0001220703125,-1) [-1|6.84362793] "kJ/l" Vector__XXX
SG_ EngineCylinder10PeakPressure : 16|16@1+ (0.0009765625,0) [0|62.74902344] "MPa" Vector__XXX
SG_ EngineCyl10SynchronousKnockLevel : 32|8@1+ (1,0) [0|250] "%" Vector__XXX
SG_ EngCyl10PressureSensorPrelimFMI : 40|5@1+ (1,0) [0|31] "" Vector__XXX
SG_ EngCyl10LowFrequencyKnockLevel : 48|8@1+ (1,0) [0|250] "%" Vector__XXX
SG_ EngCyl10MaxPressureIncreaseRate : 56|8@1+ (16,0) [0|4000] "kPa/deg crank an" Vector__XXX

BO_ 2364556542 ECCI11: 8 Vector__XXX
SG_ EngineCylinder11HeatRelease : 0|16@1+ (0.0001220703125,-1) [-1|6.84362793] "kJ/l" Vector__XXX
SG_ EngineCylinder11PeakPressure : 16|16@1+ (0.0009765625,0) [0|62.74902344] "MPa" Vector__XXX
SG_ EngineCyl11SynchronousKnockLevel : 32|8@1+ (1,0) [0|250] "%" Vector__XXX
SG_ EngCyl11PressureSensorPrelimFMI : 40|5@1+ (1,0) [0|31] "" Vector__XXX
SG_ EngCyl11LowFrequencyKnockLevel : 48|8@1+ (1,0) [0|250] "%" Vector__XXX
SG_ EngCyl11MaxPressureIncreaseRate : 56|8@1+ (16,0) [0|4000] "kPa/deg crank an" Vector__XXX

BO_ 2364556798 ECCI12: 8 Vector__XXX
SG_ EngineCylinder12HeatRelease : 0|16@1+ (0.0001220703125,-1) [-1|6.84362793] "kJ/l" Vector__XXX
SG_ EngineCylinder12PeakPressure : 16|16@1+ (0.0009765625,0) [0|62.74902344] "MPa" Vector__XXX
SG_ EngineCyl12SynchronousKnockLevel : 32|8@1+ (1,0) [0|250] "%" Vector__XXX
SG_ EngCyl12PressureSensorPrelimFMI : 40|5@1+ (1,0) [0|31] "" Vector__XXX
SG_ EngCyl12LowFrequencyKnockLevel : 48|8@1+ (1,0) [0|250] "%" Vector__XXX
SG_ EngCyl12MaxPressureIncreaseRate : 56|8@1+ (16,0) [0|4000] "kPa/deg crank an" Vector__XXX

BO_ 2364557054 ECCI13: 8 Vector__XXX
SG_ EngineCylinder13HeatRelease : 0|16@1+ (0.0001220703125,-1) [-1|6.84362793] "kJ/l" Vector__XXX
SG_ EngineCylinder13PeakPressure : 16|16@1+ (0.0009765625,0) [0|62.74902344] "MPa" Vector__XXX
SG_ EngineCyl13SynchronousKnockLevel : 32|8@1+ (1,0) [0|250] "%" Vector__XXX
SG_ EngCyl13PressureSensorPrelimFMI : 40|5@1+ (1,0) [0|31] "" Vector__XXX
SG_ EngCyl13LowFrequencyKnockLevel : 48|8@1+ (1,0) [0|250] "%" Vector__XXX
SG_ EngCyl13MaxPressureIncreaseRate : 56|8@1+ (16,0) [0|4000] "kPa/deg crank an" Vector__XXX

BO_ 2364557310 ECCI14: 8 Vector__XXX
SG_ EngineCylinder14HeatRelease : 0|16@1+ (0.0001220703125,-1) [-1|6.84362793] "kJ/l" Vector__XXX
SG_ EngineCylinder14PeakPressure : 16|16@1+ (0.0009765625,0) [0|62.74902344] "MPa" Vector__XXX
SG_ EngineCyl14SynchronousKnockLevel : 32|8@1+ (1,0) [0|250] "%" Vector__XXX
SG_ EngCyl14PressureSensorPrelimFMI : 40|5@1+ (1,0) [0|31] "" Vector__XXX
SG_ EngCyl14LowFrequencyKnockLevel : 48|8@1+ (1,0) [0|250] "%" Vector__XXX
SG_ EngCyl14MaxPressureIncreaseRate : 56|8@1+ (16,0) [0|4000] "kPa/deg crank an" Vector__XXX

BO_ 2364557566 ECCI15: 8 Vector__XXX
SG_ EngineCylinder15HeatRelease : 0|16@1+ (0.0001220703125,-1) [-1|6.84362793] "kJ/l" Vector__XXX
SG_ EngineCylinder15PeakPressure : 16|16@1+ (0.0009765625,0) [0|62.74902344] "MPa" Vector__XXX
SG_ EngineCyl15SynchronousKnockLevel : 32|8@1+ (1,0) [0|250] "%" Vector__XXX
SG_ EngCyl15PressureSensorPrelimFMI : 40|5@1+ (1,0) [0|31] "" Vector__XXX
SG_ EngCyl15LowFrequencyKnockLevel : 48|8@1+ (1,0) [0|250] "%" Vector__XXX
SG_ EngCyl15MaxPressureIncreaseRate : 56|8@1+ (16,0) [0|4000] "kPa/deg crank an" Vector__XXX

BO_ 2364557822 ECCI16: 8 Vector__XXX
SG_ EngineCylinder16HeatRelease : 0|16@1+ (0.0001220703125,-1) [-1|6.84362793] "kJ/l" Vector__XXX
SG_ EngineCylinder16PeakPressure : 16|16@1+ (0.0009765625,0) [0|62.74902344] "MPa" Vector__XXX
SG_ EngineCyl16SynchronousKnockLevel : 32|8@1+ (1,0) [0|250] "%" Vector__XXX
SG_ EngCyl16PressureSensorPrelimFMI : 40|5@1+ (1,0) [0|31] "" Vector__XXX
SG_ EngCyl16LowFrequencyKnockLevel : 48|8@1+ (1,0) [0|250] "%" Vector__XXX
SG_ EngCyl16MaxPressureIncreaseRate : 56|8@1+ (16,0) [0|4000] "kPa/deg crank an" Vector__XXX

BO_ 2364558078 ECCI17: 8 Vector__XXX
SG_ EngineCylinder17HeatRelease : 0|16@1+ (0.0001220703125,-1) [-1|6.84362793] "kJ/l" Vector__XXX
SG_ EngineCylinder17PeakPressure : 16|16@1+ (0.0009765625,0) [0|62.74902344] "MPa" Vector__XXX
SG_ EngineCyl17SynchronousKnockLevel : 32|8@1+ (1,0) [0|250] "%" Vector__XXX
SG_ EngCyl17PressureSensorPrelimFMI : 40|5@1+ (1,0) [0|31] "" Vector__XXX
SG_ EngCyl17LowFrequencyKnockLevel : 48|8@1+ (1,0) [0|250] "%" Vector__XXX
SG_ EngCyl17MaxPressureIncreaseRate : 56|8@1+ (16,0) [0|4000] "kPa/deg crank an" Vector__XXX

BO_ 2364558334 ECCI18: 8 Vector__XXX
SG_ EngineCylinder18HeatRelease : 0|16@1+ (0.0001220703125,-1) [-1|6.84362793] "kJ/l" Vector__XXX
SG_ EngineCylinder18PeakPressure : 16|16@1+ (0.0009765625,0) [0|62.74902344] "MPa" Vector__XXX
SG_ EngineCyl18SynchronousKnockLevel : 32|8@1+ (1,0) [0|250] "%" Vector__XXX
SG_ EngCyl18PressureSensorPrelimFMI : 40|5@1+ (1,0) [0|31] "" Vector__XXX
SG_ EngCyl18LowFrequencyKnockLevel : 48|8@1+ (1,0) [0|250] "%" Vector__XXX
SG_ EngCyl18MaxPressureIncreaseRate : 56|8@1+ (16,0) [0|4000] "kPa/deg crank an" Vector__XXX

BO_ 2364558590 ECCI19: 8 Vector__XXX
SG_ EngineCylinder19HeatRelease : 0|16@1+ (0.0001220703125,-1) [-1|6.84362793] "kJ/l" Vector__XXX
SG_ EngineCylinder19PeakPressure : 16|16@1+ (0.0009765625,0) [0|62.74902344] "MPa" Vector__XXX
SG_ EngineCyl19SynchronousKnockLevel : 32|8@1+ (1,0) [0|250] "%" Vector__XXX
SG_ EngCyl19PressureSensorPrelimFMI : 40|5@1+ (1,0) [0|31] "" Vector__XXX
SG_ EngCyl19LowFrequencyKnockLevel : 48|8@1+ (1,0) [0|250] "%" Vector__XXX
SG_ EngCyl19MaxPressureIncreaseRate : 56|8@1+ (16,0) [0|4000] "kPa/deg crank an" Vector__XXX

BO_ 2364558846 ECCI20: 8 Vector__XXX
SG_ EngineCylinder20HeatRelease : 0|16@1+ (0.0001220703125,-1) [-1|6.84362793] "kJ/l" Vector__XXX
SG_ EngineCylinder20PeakPressure : 16|16@1+ (0.0009765625,0) [0|62.74902344] "MPa" Vector__XXX
SG_ EngineCyl20SynchronousKnockLevel : 32|8@1+ (1,0) [0|250] "%" Vector__XXX
SG_ EngCyl20PressureSensorPrelimFMI : 40|5@1+ (1,0) [0|31] "" Vector__XXX
SG_ EngCyl20LowFrequencyKnockLevel : 48|8@1+ (1,0) [0|250] "%" Vector__XXX
SG_ EngCyl20MaxPressureIncreaseRate : 56|8@1+ (16,0) [0|4000] "kPa/deg crank an" Vector__XXX

BO_ 2498776830 ECCAI1: 8 Vector__XXX
SG_ EngCyl1IndicatedMeanEffectivePrs : 0|16@1+ (0.0001220703125,-1) [-1|6.84362793] "MPa" Vector__XXX
SG_ EngCyl1AvrgStartCombustionTiming : 16|16@1+ (0.0078125,-250) [-250|250.992] "deg" Vector__XXX
SG_ EngCyl1AvrgCntrCombustionTiming : 32|16@1+ (0.0078125,-250) [-250|250.992] "deg" Vector__XXX
SG_ EngineCyl1AvrgCombustionDuration : 48|16@1+ (0.0078125,0) [0|501.99] "deg" Vector__XXX

BO_ 2498777086 ECCAI2: 8 Vector__XXX
SG_ EngCyl2IndicatedMeanEffectivePrs : 0|16@1+ (0.0001220703125,-1) [-1|6.84362793] "MPa" Vector__XXX
SG_ EngCyl2AvrgStartCombustionTiming : 16|16@1+ (0.0078125,-250) [-250|250.992] "deg" Vector__XXX
SG_ EngCyl2AvrgCntrCombustionTiming : 32|16@1+ (0.0078125,-250) [-250|250.992] "deg" Vector__XXX
SG_ EngineCyl2AvrgCombustionDuration : 48|16@1+ (0.0078125,0) [0|501.99] "deg" Vector__XXX

BO_ 2498777342 ECCAI3: 8 Vector__XXX
SG_ EngCyl3IndicatedMeanEffectivePrs : 0|16@1+ (0.0001220703125,-1) [-1|6.84362793] "MPa" Vector__XXX
SG_ EngCyl3AvrgStartCombustionTiming : 16|16@1+ (0.0078125,-250) [-250|250.992] "deg" Vector__XXX
SG_ EngCyl3AvrgCntrCombustionTiming : 32|16@1+ (0.0078125,-250) [-250|250.992] "deg" Vector__XXX
SG_ EngineCyl3AvrgCombustionDuration : 48|16@1+ (0.0078125,0) [0|501.99] "deg" Vector__XXX

BO_ 2498777598 ECCAI4: 8 Vector__XXX
SG_ EngCyl4IndicatedMeanEffectivePrs : 0|16@1+ (0.0001220703125,-1) [-1|6.84362793] "MPa" Vector__XXX
SG_ EngCyl4AvrgStartCombustionTiming : 16|16@1+ (0.0078125,-250) [-250|250.992] "deg" Vector__XXX
SG_ EngCyl4AvrgCntrCombustionTiming : 32|16@1+ (0.0078125,-250) [-250|250.992] "deg" Vector__XXX
SG_ EngineCyl4AvrgCombustionDuration : 48|16@1+ (0.0078125,0) [0|501.99] "deg" Vector__XXX

BO_ 2498777854 ECCAI5: 8 Vector__XXX
SG_ EngCyl5IndicatedMeanEffectivePrs : 0|16@1+ (0.0001220703125,-1) [-1|6.84362793] "MPa" Vector__XXX
SG_ EngCyl5AvrgStartCombustionTiming : 16|16@1+ (0.0078125,-250) [-250|250.992] "deg" Vector__XXX
SG_ EngCyl5AvrgCntrCombustionTiming : 32|16@1+ (0.0078125,-250) [-250|250.992] "deg" Vector__XXX
SG_ EngineCyl5AvrgCombustionDuration : 48|16@1+ (0.0078125,0) [0|501.99] "deg" Vector__XXX

BO_ 2498778110 ECCAI6: 8 Vector__XXX
SG_ EngCyl6IndicatedMeanEffectivePrs : 0|16@1+ (0.0001220703125,-1) [-1|6.84362793] "MPa" Vector__XXX
SG_ EngCyl6AvrgStartCombustionTiming : 16|16@1+ (0.0078125,-250) [-250|250.992] "deg" Vector__XXX
SG_ EngCyl6AvrgCntrCombustionTiming : 32|16@1+ (0.0078125,-250) [-250|250.992] "deg" Vector__XXX
SG_ EngineCyl6AvrgCombustionDuration : 48|16@1+ (0.0078125,0) [0|501.99] "deg" Vector__XXX

BO_ 2498778366 ECCAI7: 8 Vector__XXX
SG_ EngCyl7IndicatedMeanEffectivePrs : 0|16@1+ (0.0001220703125,-1) [-1|6.84362793] "MPa" Vector__XXX
SG_ EngCyl7AvrgStartCombustionTiming : 16|16@1+ (0.0078125,-250) [-250|250.992] "deg" Vector__XXX
SG_ EngCyl7AvrgCntrCombustionTiming : 32|16@1+ (0.0078125,-250) [-250|250.992] "deg" Vector__XXX
SG_ EngineCyl7AvrgCombustionDuration : 48|16@1+ (0.0078125,0) [0|501.99] "deg" Vector__XXX

BO_ 2498778622 ECCAI8: 8 Vector__XXX
SG_ EngCyl8IndicatedMeanEffectivePrs : 0|16@1+ (0.0001220703125,-1) [-1|6.84362793] "MPa" Vector__XXX
SG_ EngCyl8AvrgStartCombustionTiming : 16|16@1+ (0.0078125,-250) [-250|250.992] "deg" Vector__XXX
SG_ EngCyl8AvrgCntrCombustionTiming : 32|16@1+ (0.0078125,-250) [-250|250.992] "deg" Vector__XXX
SG_ EngineCyl8AvrgCombustionDuration : 48|16@1+ (0.0078125,0) [0|501.99] "deg" Vector__XXX

BO_ 2498778878 ECCAI9: 8 Vector__XXX
SG_ EngCyl9IndicatedMeanEffectivePrs : 0|16@1+ (0.0001220703125,-1) [-1|6.84362793] "MPa" Vector__XXX
SG_ EngCyl9AvrgStartCombustionTiming : 16|16@1+ (0.0078125,-250) [-250|250.992] "deg" Vector__XXX
SG_ EngCyl9AvrgCntrCombustionTiming : 32|16@1+ (0.0078125,-250) [-250|250.992] "deg" Vector__XXX
SG_ EngineCyl9AvrgCombustionDuration : 48|16@1+ (0.0078125,0) [0|501.99] "deg" Vector__XXX

BO_ 2498779134 ECCAI10: 8 Vector__XXX
SG_ EngCyl10IndicatedMeanEffectPrs : 0|16@1+ (0.0001220703125,-1) [-1|6.84362793] "MPa" Vector__XXX
SG_ EngCyl10AvrgStrtOfCombustionTmng : 16|16@1+ (0.0078125,-250) [-250|250.992] "deg" Vector__XXX
SG_ EngCyl10AvrgCntrOfCombustionTmng : 32|16@1+ (0.0078125,-250) [-250|250.992] "deg" Vector__XXX
SG_ EngCyl10AvrgCombustionDuration : 48|16@1+ (0.0078125,0) [0|501.99] "deg" Vector__XXX

BO_ 2498779390 ECCAI11: 8 Vector__XXX
SG_ EngCyl11IndicatedMeanEffectPrs : 0|16@1+ (0.0001220703125,-1) [-1|6.84362793] "MPa" Vector__XXX
SG_ EngCyl11AvrgStrtOfCombustionTmng : 16|16@1+ (0.0078125,-250) [-250|250.992] "deg" Vector__XXX
SG_ EngCyl11AvrgCntrOfCombustionTmng : 32|16@1+ (0.0078125,-250) [-250|250.992] "deg" Vector__XXX
SG_ EngCyl11AvrgCombustionDuration : 48|16@1+ (0.0078125,0) [0|501.99] "deg" Vector__XXX

BO_ 2498779646 ECCAI12: 8 Vector__XXX
SG_ EngCyl12IndicatedMeanEffectPrs : 0|16@1+ (0.0001220703125,-1) [-1|6.84362793] "MPa" Vector__XXX
SG_ EngCyl12AvrgStrtOfCombustionTmng : 16|16@1+ (0.0078125,-250) [-250|250.992] "deg" Vector__XXX
SG_ EngCyl12AvrgCntrOfCombustionTmng : 32|16@1+ (0.0078125,-250) [-250|250.992] "deg" Vector__XXX
SG_ EngCyl12AvrgCombustionDuration : 48|16@1+ (0.0078125,0) [0|501.99] "deg" Vector__XXX

BO_ 2498779902 ECCAI13: 8 Vector__XXX
SG_ EngCyl13IndicatedMeanEffectPrs : 0|16@1+ (0.0001220703125,-1) [-1|6.84362793] "MPa" Vector__XXX
SG_ EngCyl13AvrgStrtOfCombustionTmng : 16|16@1+ (0.0078125,-250) [-250|250.992] "deg" Vector__XXX
SG_ EngCyl13AvrgCntrOfCombustionTmng : 32|16@1+ (0.0078125,-250) [-250|250.992] "deg" Vector__XXX
SG_ EngCyl13AvrgCombustionDuration : 48|16@1+ (0.0078125,0) [0|501.99] "deg" Vector__XXX

BO_ 2498780158 ECCAI14: 8 Vector__XXX
SG_ EngCyl14IndicatedMeanEffectPrs : 0|16@1+ (0.0001220703125,-1) [-1|6.84362793] "MPa" Vector__XXX
SG_ EngCyl14AvrgStrtOfCombustionTmng : 16|16@1+ (0.0078125,-250) [-250|250.992] "deg" Vector__XXX
SG_ EngCyl14AvrgCntrOfCombustionTmng : 32|16@1+ (0.0078125,-250) [-250|250.992] "deg" Vector__XXX
SG_ EngCyl14AvrgCombustionDuration : 48|16@1+ (0.0078125,0) [0|501.99] "deg" Vector__XXX

BO_ 2498780414 ECCAI15: 8 Vector__XXX
SG_ EngCyl15IndicatedMeanEffectPrs : 0|16@1+ (0.0001220703125,-1) [-1|6.84362793] "MPa" Vector__XXX
SG_ EngCyl15AvrgStrtOfCombustionTmng : 16|16@1+ (0.0078125,-250) [-250|250.992] "deg" Vector__XXX
SG_ EngCyl15AvrgCntrOfCombustionTmng : 32|16@1+ (0.0078125,-250) [-250|250.992] "deg" Vector__XXX
SG_ EngCyl15AvrgCombustionDuration : 48|16@1+ (0.0078125,0) [0|501.99] "deg" Vector__XXX

BO_ 2498780670 ECCAI16: 8 Vector__XXX
SG_ EngCyl16IndicatedMeanEffectPrs : 0|16@1+ (0.0001220703125,-1) [-1|6.84362793] "MPa" Vector__XXX
SG_ EngCyl16AvrgStrtOfCombustionTmng : 16|16@1+ (0.0078125,-250) [-250|250.992] "deg" Vector__XXX
SG_ EngCyl16AvrgCntrOfCombustionTmng : 32|16@1+ (0.0078125,-250) [-250|250.992] "deg" Vector__XXX
SG_ EngCyl16AvrgCombustionDuration : 48|16@1+ (0.0078125,0) [0|501.99] "deg" Vector__XXX

BO_ 2498780926 ECCAI17: 8 Vector__XXX
SG_ EngCyl17IndicatedMeanEffectPrs : 0|16@1+ (0.0001220703125,-1) [-1|6.84362793] "MPa" Vector__XXX
SG_ EngCyl17AvrgStrtOfCombustionTmng : 16|16@1+ (0.0078125,-250) [-250|250.992] "deg" Vector__XXX
SG_ EngCyl17AvrgCntrOfCombustionTmng : 32|16@1+ (0.0078125,-250) [-250|250.992] "deg" Vector__XXX
SG_ EngCyl17AvrgCombustionDuration : 48|16@1+ (0.0078125,0) [0|501.99] "deg" Vector__XXX

BO_ 2498781182 ECCAI18: 8 Vector__XXX
SG_ EngCyl18IndicatedMeanEffectPrs : 0|16@1+ (0.0001220703125,-1) [-1|6.84362793] "MPa" Vector__XXX
SG_ EngCyl18AvrgStrtOfCombustionTmng : 16|16@1+ (0.0078125,-250) [-250|250.992] "deg" Vector__XXX
SG_ EngCyl18AvrgCntrOfCombustionTmng : 32|16@1+ (0.0078125,-250) [-250|250.992] "deg" Vector__XXX
SG_ EngCyl18AvrgCombustionDuration : 48|16@1+ (0.0078125,0) [0|501.99] "deg" Vector__XXX

BO_ 2498781438 ECCAI19: 8 Vector__XXX
SG_ EngCyl19IndicatedMeanEffectPrs : 0|16@1+ (0.0001220703125,-1) [-1|6.84362793] "MPa" Vector__XXX
SG_ EngCyl19AvrgStrtOfCombustionTmng : 16|16@1+ (0.0078125,-250) [-250|250.992] "deg" Vector__XXX
SG_ EngCyl19AvrgCntrOfCombustionTmng : 32|16@1+ (0.0078125,-250) [-250|250.992] "deg" Vector__XXX
SG_ EngCyl19AvrgCombustionDuration : 48|16@1+ (0.0078125,0) [0|501.99] "deg" Vector__XXX

BO_ 2498781694 ECCAI20: 8 Vector__XXX
SG_ EngCyl20IndicatedMeanEffectPrs : 0|16@1+ (0.0001220703125,-1) [-1|6.84362793] "MPa" Vector__XXX
SG_ EngCyl20AvrgStrtOfCombustionTmng : 16|16@1+ (0.0078125,-250) [-250|250.992] "deg" Vector__XXX
SG_ EngCyl20AvrgCntrOfCombustionTmng : 32|16@1+ (0.0078125,-250) [-250|250.992] "deg" Vector__XXX
SG_ EngCyl20AvrgCombustionDuration : 48|16@1+ (0.0078125,0) [0|501.99] "deg" Vector__XXX

BO_ 2297455358 ETC12: 8 Vector__XXX
SG_ TransmissionHydrostaticLp1Press : 0|16@1+ (1,0) [0|64255] "kPa" Vector__XXX
SG_ TransmissionHydrostaticLp2Press : 16|16@1+ (1,0) [0|64255] "kPa" Vector__XXX
SG_ TrnsmDirectionalOutptShftSpd : 32|16@1+ (1,-32127) [-32127|32128] "rpm" Vector__XXX
SG_ TransmissionIntrmedShaftSpeed : 48|16@1+ (0.125,0) [0|8031.875] "rpm" Vector__XXX

BO_ 2364564478 GFI5: 8 Vector__XXX
SG_ EngGseousFuelVlvNomDurationCmd : 0|16@1+ (2,0) [0|128510] "us" Vector__XXX
SG_ EngGseousFuelVlvNomStrtOfActCmd : 16|16@1+ (0.0078125,-400) [-400|101.99] "deg" Vector__XXX

BO_ 2364564734 EGFVDC1: 8 Vector__XXX
SG_ EngGaseousFuelValve1DurationCmd : 0|16@1+ (2,0) [0|128510] "us" Vector__XXX
SG_ EngGaseousFuelValve2DurationCmd : 16|16@1+ (2,0) [0|128510] "us" Vector__XXX
SG_ EngGaseousFuelValve3DurationCmd : 32|16@1+ (2,0) [0|128510] "us" Vector__XXX
SG_ EngGaseousFuelValve4DurationCmd : 48|16@1+ (2,0) [0|128510] "us" Vector__XXX

BO_ 2364564990 EGFVDC2: 8 Vector__XXX
SG_ EngGaseousFuelValve5DurationCmd : 0|16@1+ (2,0) [0|128510] "us" Vector__XXX
SG_ EngGaseousFuelValve6DurationCmd : 16|16@1+ (2,0) [0|128510] "us" Vector__XXX
SG_ EngGaseousFuelValve7DurationCmd : 32|16@1+ (2,0) [0|128510] "us" Vector__XXX
SG_ EngGaseousFuelValve8DurationCmd : 48|16@1+ (2,0) [0|128510] "us" Vector__XXX

BO_ 2364565246 EGFVDC3: 8 Vector__XXX
SG_ EngGaseousFuelValve9DurationCmd : 0|16@1+ (2,0) [0|128510] "us" Vector__XXX
SG_ EngGaseousFuelValve10DurationCmd : 16|16@1+ (2,0) [0|128510] "us" Vector__XXX
SG_ EngGaseousFuelValve11DurationCmd : 32|16@1+ (2,0) [0|128510] "us" Vector__XXX
SG_ EngGaseousFuelValve12DurationCmd : 48|16@1+ (2,0) [0|128510] "us" Vector__XXX

BO_ 2364565502 EGFVDC4: 8 Vector__XXX
SG_ EngGaseousFuelValve13DurationCmd : 0|16@1+ (2,0) [0|128510] "us" Vector__XXX
SG_ EngGaseousFuelValve14DurationCmd : 16|16@1+ (2,0) [0|128510] "us" Vector__XXX
SG_ EngGaseousFuelValve15DurationCmd : 32|16@1+ (2,0) [0|128510] "us" Vector__XXX
SG_ EngGaseousFuelValve16DurationCmd : 48|16@1+ (2,0) [0|128510] "us" Vector__XXX

BO_ 2364565758 EGFVDC5: 8 Vector__XXX
SG_ EngGaseousFuelValve17DurationCmd : 0|16@1+ (2,0) [0|128510] "us" Vector__XXX
SG_ EngGaseousFuelValve18DurationCmd : 16|16@1+ (2,0) [0|128510] "us" Vector__XXX
SG_ EngGaseousFuelValve19DurationCmd : 32|16@1+ (2,0) [0|128510] "us" Vector__XXX
SG_ EngGaseousFuelValve20DurationCmd : 48|16@1+ (2,0) [0|128510] "us" Vector__XXX

BO_ 2364566014 EGFVSOAC1: 8 Vector__XXX
SG_ EngGaseousFuelVlv1StartOfActCmd : 0|16@1+ (0.0078125,-400) [-400|101.99] "deg" Vector__XXX
SG_ EngGaseousFuelVlv2StartOfActCmd : 16|16@1+ (0.0078125,-400) [-400|101.99] "deg" Vector__XXX
SG_ EngGaseousFuelVlv3StartOfActCmd : 32|16@1+ (0.0078125,-400) [-400|101.99] "deg" Vector__XXX
SG_ EngGaseousFuelVlv4StartOfActCmd : 48|16@1+ (0.0078125,-400) [-400|101.99] "deg" Vector__XXX

BO_ 2364566270 EGFVSOAC2: 8 Vector__XXX
SG_ EngGaseousFuelVlv5StartOfActCmd : 0|16@1+ (0.0078125,-400) [-400|101.99] "deg" Vector__XXX
SG_ EngGaseousFuelVlv6StartOfActCmd : 16|16@1+ (0.0078125,-400) [-400|101.99] "deg" Vector__XXX
SG_ EngGaseousFuelVlv7StartOfActCmd : 32|16@1+ (0.0078125,-400) [-400|101.99] "deg" Vector__XXX
SG_ EngGaseousFuelVlv8StartOfActCmd : 48|16@1+ (0.0078125,-400) [-400|101.99] "deg" Vector__XXX

BO_ 2364566526 EGFVSOAC3: 8 Vector__XXX
SG_ EngGaseousFuelVlv9StartOfActCmd : 0|16@1+ (0.0078125,-400) [-400|101.99] "deg" Vector__XXX
SG_ EngGaseousFuelVlv10StartOfActCmd : 16|16@1+ (0.0078125,-400) [-400|101.99] "deg" Vector__XXX
SG_ EngGaseousFuelVlv11StartOfActCmd : 32|16@1+ (0.0078125,-400) [-400|101.99] "deg" Vector__XXX
SG_ EngGaseousFuelVlv12StartOfActCmd : 48|16@1+ (0.0078125,-400) [-400|101.99] "deg" Vector__XXX

BO_ 2364566782 EGFVSOAC4: 8 Vector__XXX
SG_ EngGaseousFuelVlv13StartOfActCmd : 0|16@1+ (0.0078125,-400) [-400|101.99] "deg" Vector__XXX
SG_ EngGaseousFuelVlv14StartOfActCmd : 16|16@1+ (0.0078125,-400) [-400|101.99] "deg" Vector__XXX
SG_ EngGaseousFuelVlv15StartOfActCmd : 32|16@1+ (0.0078125,-400) [-400|101.99] "deg" Vector__XXX
SG_ EngGaseousFuelVlv16StartOfActCmd : 48|16@1+ (0.0078125,-400) [-400|101.99] "deg" Vector__XXX

BO_ 2364567038 EGFVSOAC5: 8 Vector__XXX
SG_ EngGaseousFuelVlv17StartOfActCmd : 0|16@1+ (0.0078125,-400) [-400|101.99] "deg" Vector__XXX
SG_ EngGaseousFuelVlv18StartOfActCmd : 16|16@1+ (0.0078125,-400) [-400|101.99] "deg" Vector__XXX
SG_ EngGaseousFuelVlv19StartOfActCmd : 32|16@1+ (0.0078125,-400) [-400|101.99] "deg" Vector__XXX
SG_ EngGaseousFuelVlv20StartOfActCmd : 48|16@1+ (0.0078125,-400) [-400|101.99] "deg" Vector__XXX

BO_ 2364567294 FPAC: 8 Vector__XXX
SG_ EngFuelInjectPmp1FuelCtrlVlvCmd : 0|16@1+ (0.0025,0) [0|160.6375] "%" Vector__XXX
SG_ EngFuelInjectPmp2FuelCtrlVlvCmd : 16|16@1+ (0.0025,0) [0|160.6375] "%" Vector__XXX

BO_ 2364575998 HVES1D1: 8 Vector__XXX
SG_ HVES1AvailableDischargePower : 0|16@1+ (0.05,0) [0|3212.75] "kW" Vector__XXX
SG_ HVES1AvailableChargePower : 16|16@1+ (0.05,0) [0|3212.75] "kW" Vector__XXX
SG_ HVES1VoltageLevel : 32|16@1+ (0.05,0) [0|3212.75] "V" Vector__XXX
SG_ HVES1Current : 48|16@1+ (0.05,-1600) [-1600|1612.75] "A" Vector__XXX

BO_ 2364576254 HVES1D2: 8 Vector__XXX
SG_ HVES1FastUpdateStateOfCharge : 0|16@1+ (0.0015625,0) [0|100.3984375] "%" Vector__XXX
SG_ HVES1HighestCellVoltage : 16|16@1+ (0.001,0) [0|64.255] "V" Vector__XXX
SG_ HVES1LowestCellVoltage : 32|16@1+ (0.001,0) [0|64.255] "V" Vector__XXX
SG_ HVES1CellVoltageDiffStatus : 48|4@1+ (1,0) [0|15] "" Vector__XXX

BO_ 2364576510 HVES1D3: 8 Vector__XXX
SG_ HVES1HighestCellTemperature : 0|16@1+ (0.03125,-273) [-273|1734.96875] "deg C" Vector__XXX
SG_ HVES1LowestCellTemperature : 16|16@1+ (0.03125,-273) [-273|1734.96875] "deg C" Vector__XXX
SG_ HVES1AverageCellTemperature : 32|16@1+ (0.03125,-273) [-273|1734.96875] "deg C" Vector__XXX
SG_ HVES1CellTemperatureDiffStatus : 48|2@1+ (1,0) [0|3] "" Vector__XXX

BO_ 2364576766 HVES1D4: 8 Vector__XXX
SG_ HVES1DischargeCapacity : 0|16@1+ (0.01,0) [0|642.55] "Ah" Vector__XXX
SG_ HVES1ChargeCapacity : 16|16@1+ (0.01,0) [0|642.55] "Ah" Vector__XXX
SG_ HVES1CellBalancingCount : 32|16@1+ (1,0) [0|64255] "" Vector__XXX

BO_ 2364577022 HVES1D5: 8 Vector__XXX
SG_ HVES1DischargeCurrentLimit : 0|16@1+ (0.05,-1600) [-1600|1612.75] "A" Vector__XXX
SG_ HVES1ChargeCurrentLimit : 16|16@1+ (0.05,-1600) [-1600|1612.75] "A" Vector__XXX
SG_ HVES1MinimumCellStateOfCharge : 32|16@1+ (0.0015625,0) [0|100.3984375] "%" Vector__XXX
SG_ HVES1MaximumCellStateOfCharge : 48|16@1+ (0.0015625,0) [0|100.3984375] "%" Vector__XXX

BO_ 2364577278 HVES1D6: 8 Vector__XXX
SG_ HVES1BusVoltage : 0|16@1+ (0.05,0) [0|3212.75] "V" Vector__XXX
SG_ HVES1IgnitionVoltage : 16|16@1+ (0.01,0) [0|642.55] "V" Vector__XXX
SG_ HVES1InletCoolantTemperature : 32|8@1+ (1,-40) [-40|210] "deg C" Vector__XXX
SG_ HVES1OutletCoolantTemperature : 40|8@1+ (1,-40) [-40|210] "deg C" Vector__XXX
SG_ HVES1ElectronicsTemperature : 48|8@1+ (1,-40) [-40|210] "deg C" Vector__XXX

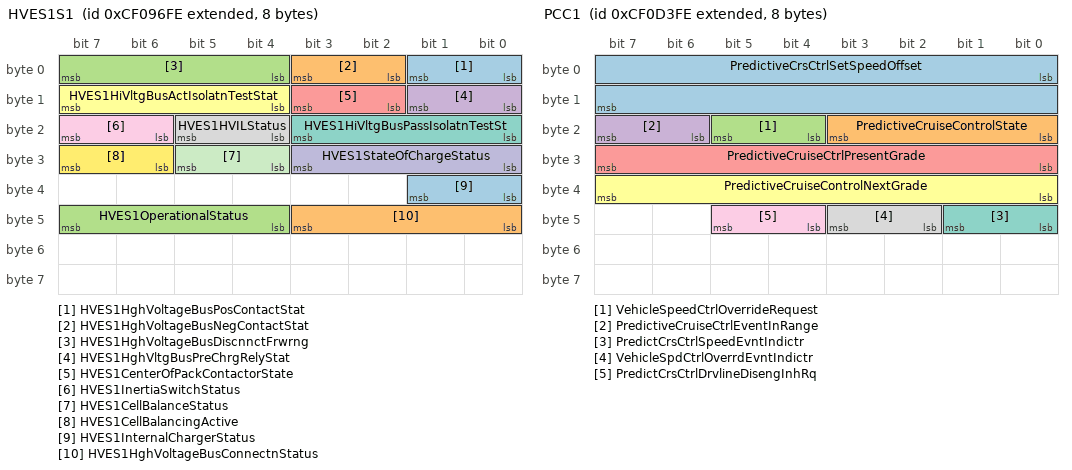
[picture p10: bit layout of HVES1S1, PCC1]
BO_ 2364577534 HVES1S1: 8 Vector__XXX
SG_ HVES1HghVoltageBusPosContactStat : 0|2@1+ (1,0) [0|3] "" Vector__XXX
SG_ HVES1HghVoltageBusNegContactStat : 2|2@1+ (1,0) [0|3] "" Vector__XXX
SG_ HVES1HghVoltageBusDiscnnctFrwrng : 4|4@1+ (1,0) [0|15] "" Vector__XXX
SG_ HVES1HghVltgBusPreChrgRelyStat : 8|2@1+ (1,0) [0|3] "" Vector__XXX
SG_ HVES1CenterOfPackContactorState : 10|2@1+ (1,0) [0|3] "" Vector__XXX
SG_ HVES1HiVltgBusActIsolatnTestStat : 12|4@1+ (1,0) [0|15] "" Vector__XXX
SG_ HVES1HiVltgBusPassIsolatnTestSt : 16|4@1+ (1,0) [0|15] "" Vector__XXX
SG_ HVES1HVILStatus : 20|2@1+ (1,0) [0|3] "" Vector__XXX
SG_ HVES1InertiaSwitchStatus : 22|2@1+ (1,0) [0|3] "" Vector__XXX
SG_ HVES1StateOfChargeStatus : 24|4@1+ (1,0) [0|15] "" Vector__XXX
SG_ HVES1CellBalanceStatus : 28|2@1+ (1,0) [0|3] "" Vector__XXX
SG_ HVES1CellBalancingActive : 30|2@1+ (1,0) [0|3] "" Vector__XXX
SG_ HVES1InternalChargerStatus : 32|2@1+ (1,0) [0|3] "" Vector__XXX
SG_ HVES1HghVoltageBusConnectnStatus : 40|4@1+ (1,0) [0|15] "" Vector__XXX
SG_ HVES1OperationalStatus : 44|4@1+ (1,0) [0|15] "" Vector__XXX

BO_ 2364580094 HVES1D7: 8 Vector__XXX
SG_ HVES1DischargeEnergyCapacity : 0|24@1+ (0.001,0) [0|16449.535] "kWh" Vector__XXX
SG_ HVES1ChargeEnergyCapacity : 24|24@1+ (0.001,0) [0|16449.535] "kWh" Vector__XXX
SG_ HVES1MaximumChargeVoltageLimit : 48|16@1+ (0.05,0) [0|3212.75] "V" Vector__XXX

BO_ 2364592382 ECCR: 8 Vector__XXX
SG_ NoEngCylsToExcludeFrmCombustion : 0|8@1+ (1,0) [0|250] "" Vector__XXX
SG_ EngCyl1ExcludeFrmCombustionRq : 8|2@1+ (1,0) [0|3] "" Vector__XXX
SG_ EngCyl2ExcludeFrmCombustionRq : 10|2@1+ (1,0) [0|3] "" Vector__XXX
SG_ EngCyl3ExcludeFrmCombustionRq : 12|2@1+ (1,0) [0|3] "" Vector__XXX
SG_ EngCyl4ExcludeFrmCombustionRq : 14|2@1+ (1,0) [0|3] "" Vector__XXX
SG_ EngCyl5ExcludeFrmCombustionRq : 16|2@1+ (1,0) [0|3] "" Vector__XXX
SG_ EngCyl6ExcludeFrmCombustionRq : 18|2@1+ (1,0) [0|3] "" Vector__XXX
SG_ EngCyl7ExcludeFrmCombustionRq : 20|2@1+ (1,0) [0|3] "" Vector__XXX
SG_ EngCyl8ExcludeFrmCombustionRq : 22|2@1+ (1,0) [0|3] "" Vector__XXX
SG_ EngCyl9ExcludeFrmCombustionRq : 24|2@1+ (1,0) [0|3] "" Vector__XXX
SG_ EngCyl10ExcludeFrmCombustionRq : 26|2@1+ (1,0) [0|3] "" Vector__XXX
SG_ EngCyl11ExcludeFrmCombustionRq : 28|2@1+ (1,0) [0|3] "" Vector__XXX
SG_ EngCyl12ExcludeFrmCombustionRq : 30|2@1+ (1,0) [0|3] "" Vector__XXX
SG_ EngCyl13ExcludeFrmCombustionRq : 32|2@1+ (1,0) [0|3] "" Vector__XXX
SG_ EngCyl14ExcludeFrmCombustionRq : 34|2@1+ (1,0) [0|3] "" Vector__XXX
SG_ EngCyl15ExcludeFrmCombustionRq : 36|2@1+ (1,0) [0|3] "" Vector__XXX
SG_ EngCyl16ExcludeFrmCombustionRq : 38|2@1+ (1,0) [0|3] "" Vector__XXX
SG_ EngCyl17ExcludeFrmCombustionRq : 40|2@1+ (1,0) [0|3] "" Vector__XXX
SG_ EngCyl18ExcludeFrmCombustionRq : 42|2@1+ (1,0) [0|3] "" Vector__XXX
SG_ EngCyl19ExcludeFrmCombustionRq : 44|2@1+ (1,0) [0|3] "" Vector__XXX
SG_ EngCyl20ExcludeFrmCombustionRq : 46|2@1+ (1,0) [0|3] "" Vector__XXX
SG_ EngCyl21ExcludeFrmCombustionRq : 48|2@1+ (1,0) [0|3] "" Vector__XXX
SG_ EngCyl22ExcludeFrmCombustionRq : 50|2@1+ (1,0) [0|3] "" Vector__XXX
SG_ EngCyl23ExcludeFrmCombustionRq : 52|2@1+ (1,0) [0|3] "" Vector__XXX
SG_ EngCyl24ExcludeFrmCombustionRq : 54|2@1+ (1,0) [0|3] "" Vector__XXX

BO_ 2364592638 ECBA1: 8 Vector__XXX
SG_ EngCylHeadBypssActr1PrelimFMI : 0|5@1+ (1,0) [0|31] "" Vector__XXX
SG_ EngCylHeadBypssActr1TempStat : 5|3@1+ (1,0) [0|7] "" Vector__XXX
SG_ EngCylHeadBypssActr1Temperature : 8|8@1+ (1,-40) [-40|210] "deg C" Vector__XXX
SG_ EngCylHeadBypssActr1DsrdPosition : 16|8@1+ (0.4,0) [0|100] "%" Vector__XXX
SG_ EngineCylHeadBypssActr1Position : 24|8@1+ (0.4,0) [0|100] "%" Vector__XXX
SG_ EngCylHeadBypssActr1OpStatus : 32|4@1+ (1,0) [0|15] "" Vector__XXX

BO_ 2364592894 EEC18: 8 Vector__XXX
SG_ EngineCylinderHeadBypssActr1Cmd : 0|16@1+ (0.0025,0) [0|160.6375] "%" Vector__XXX
SG_ EngineIntakeAirSourceValve : 16|2@1+ (1,0) [0|3] "" Vector__XXX
SG_ EngExhstGsRestrictionValvePos : 32|16@1+ (0.0025,0) [0|160.6375] "%" Vector__XXX

BO_ 2364593150 PCC1: 8 Vector__XXX
SG_ PredictiveCrsCtrlSetSpeedOffset : 0|16@1+ (0.00390625,-125) [-125|125.996] "km/h" Vector__XXX
SG_ PredictiveCruiseControlState : 16|4@1+ (1,0) [0|15] "" Vector__XXX
SG_ VehicleSpeedCtrlOverrideRequest : 20|2@1+ (1,0) [0|3] "" Vector__XXX
SG_ PredictiveCruiseCtrlEventInRange : 22|2@1+ (1,0) [0|3] "" Vector__XXX
SG_ PredictiveCruiseCtrlPresentGrade : 24|8@1+ (0.125,-16) [-16|15.25] "%" Vector__XXX
SG_ PredictiveCruiseControlNextGrade : 32|8@1+ (0.125,-16) [-16|15.25] "%" Vector__XXX
SG_ PredictCrsCtrlSpeedEvntIndictr : 40|2@1+ (1,0) [0|3] "" Vector__XXX
SG_ VehicleSpdCtrlOverrdEvntIndictr : 42|2@1+ (1,0) [0|3] "" Vector__XXX
SG_ PredictCrsCtrlDrvlineDisengInhRq : 44|2@1+ (1,0) [0|3] "" Vector__XXX

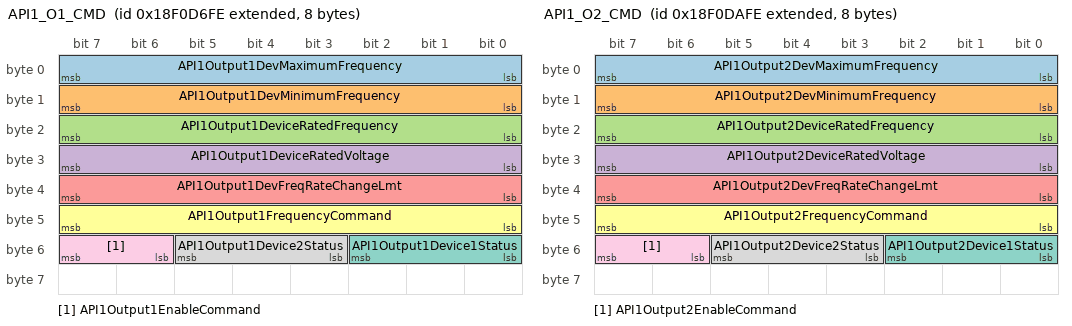
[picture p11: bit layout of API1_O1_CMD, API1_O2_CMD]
BO_ 2565920510 API1_O1_CMD: 8 Vector__XXX
SG_ API1Output1DevMaximumFrequency : 0|8@1+ (1,0) [0|250] "Hz" Vector__XXX
SG_ API1Output1DevMinimumFrequency : 8|8@1+ (1,0) [0|250] "Hz" Vector__XXX
SG_ API1Output1DeviceRatedFrequency : 16|8@1+ (1,0) [0|250] "Hz" Vector__XXX
SG_ API1Output1DeviceRatedVoltage : 24|8@1+ (2,0) [0|500] "Vrms" Vector__XXX
SG_ API1Output1DevFreqRateChangeLmt : 32|8@1+ (2,0) [0|500] "Hz/s" Vector__XXX
SG_ API1Output1FrequencyCommand : 40|8@1+ (1,0) [0|250] "Hz" Vector__XXX
SG_ API1Output1Device1Status : 48|3@1+ (1,0) [0|7] "" Vector__XXX
SG_ API1Output1Device2Status : 51|3@1+ (1,0) [0|7] "" Vector__XXX
SG_ API1Output1EnableCommand : 54|2@1+ (1,0) [0|3] "" Vector__XXX

BO_ 2565920766 API1_O1_FDBK: 8 Vector__XXX
SG_ API1Output1FrequencyFeedback : 0|8@1+ (1,0) [0|250] "Hz" Vector__XXX
SG_ API1Output1VoltageFeedback : 8|8@1+ (2,0) [0|500] "Vrms" Vector__XXX
SG_ API1Output1PowerFeedback : 16|8@1+ (0.1,0) [0|25] "kW" Vector__XXX
SG_ API1Output1StatusFeedback : 48|3@1+ (1,0) [0|7] "" Vector__XXX
SG_ API1Output1LoadshedRequest : 51|2@1+ (1,0) [0|3] "" Vector__XXX
SG_ API1Output1HVILStatus : 53|2@1+ (1,0) [0|3] "" Vector__XXX

BO_ 2565921534 API1_O2_CMD: 8 Vector__XXX
SG_ API1Output2DevMaximumFrequency : 0|8@1+ (1,0) [0|250] "Hz" Vector__XXX
SG_ API1Output2DevMinimumFrequency : 8|8@1+ (1,0) [0|250] "Hz" Vector__XXX
SG_ API1Output2DeviceRatedFrequency : 16|8@1+ (1,0) [0|250] "Hz" Vector__XXX
SG_ API1Output2DeviceRatedVoltage : 24|8@1+ (2,0) [0|500] "Vrms" Vector__XXX
SG_ API1Output2DevFreqRateChangeLmt : 32|8@1+ (2,0) [0|500] "Hz/s" Vector__XXX
SG_ API1Output2FrequencyCommand : 40|8@1+ (1,0) [0|250] "Hz" Vector__XXX
SG_ API1Output2Device1Status : 48|3@1+ (1,0) [0|7] "" Vector__XXX
SG_ API1Output2Device2Status : 51|3@1+ (1,0) [0|7] "" Vector__XXX
SG_ API1Output2EnableCommand : 54|2@1+ (1,0) [0|3] "" Vector__XXX

BO_ 2565921790 API1_O2_FDBK: 8 Vector__XXX
SG_ API1Output2FrequencyFeedback : 0|8@1+ (1,0) [0|250] "Hz" Vector__XXX
SG_ API1Output2VoltageFeedback : 8|8@1+ (2,0) [0|500] "Vrms" Vector__XXX
SG_ API1Output2PowerFeedback : 16|8@1+ (0.1,0) [0|25] "kW" Vector__XXX
SG_ API1Output2StatusFeedback : 48|3@1+ (1,0) [0|7] "" Vector__XXX
SG_ API1Output2LoadshedRequest : 51|2@1+ (1,0) [0|3] "" Vector__XXX
SG_ API1Output2HVILStatus : 53|2@1+ (1,0) [0|3] "" Vector__XXX

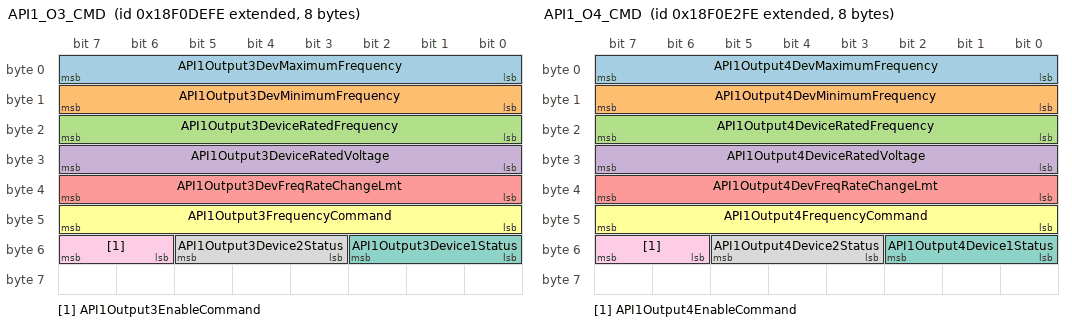
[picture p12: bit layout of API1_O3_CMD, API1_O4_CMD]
BO_ 2565922558 API1_O3_CMD: 8 Vector__XXX
SG_ API1Output3DevMaximumFrequency : 0|8@1+ (1,0) [0|250] "Hz" Vector__XXX
SG_ API1Output3DevMinimumFrequency : 8|8@1+ (1,0) [0|250] "Hz" Vector__XXX
SG_ API1Output3DeviceRatedFrequency : 16|8@1+ (1,0) [0|250] "Hz" Vector__XXX
SG_ API1Output3DeviceRatedVoltage : 24|8@1+ (2,0) [0|500] "Vrms" Vector__XXX
SG_ API1Output3DevFreqRateChangeLmt : 32|8@1+ (2,0) [0|500] "Hz/s" Vector__XXX
SG_ API1Output3FrequencyCommand : 40|8@1+ (1,0) [0|250] "Hz" Vector__XXX
SG_ API1Output3Device1Status : 48|3@1+ (1,0) [0|7] "" Vector__XXX
SG_ API1Output3Device2Status : 51|3@1+ (1,0) [0|7] "" Vector__XXX
SG_ API1Output3EnableCommand : 54|2@1+ (1,0) [0|3] "" Vector__XXX

BO_ 2565922814 API1_O3_FDBK: 8 Vector__XXX
SG_ API1Output3FrequencyFeedback : 0|8@1+ (1,0) [0|250] "Hz" Vector__XXX
SG_ API1Output3VoltageFeedback : 8|8@1+ (2,0) [0|500] "Vrms" Vector__XXX
SG_ API1Output3PowerFeedback : 16|8@1+ (0.1,0) [0|25] "kW" Vector__XXX
SG_ API1Output3StatusFeedback : 48|3@1+ (1,0) [0|7] "" Vector__XXX
SG_ API1Output3LoadshedRequest : 51|2@1+ (1,0) [0|3] "" Vector__XXX
SG_ API1Output3HVILStatus : 53|2@1+ (1,0) [0|3] "" Vector__XXX

BO_ 2565923582 API1_O4_CMD: 8 Vector__XXX
SG_ API1Output4DevMaximumFrequency : 0|8@1+ (1,0) [0|250] "Hz" Vector__XXX
SG_ API1Output4DevMinimumFrequency : 8|8@1+ (1,0) [0|250] "Hz" Vector__XXX
SG_ API1Output4DeviceRatedFrequency : 16|8@1+ (1,0) [0|250] "Hz" Vector__XXX
SG_ API1Output4DeviceRatedVoltage : 24|8@1+ (2,0) [0|500] "Vrms" Vector__XXX
SG_ API1Output4DevFreqRateChangeLmt : 32|8@1+ (2,0) [0|500] "Hz/s" Vector__XXX
SG_ API1Output4FrequencyCommand : 40|8@1+ (1,0) [0|250] "Hz" Vector__XXX
SG_ API1Output4Device1Status : 48|3@1+ (1,0) [0|7] "" Vector__XXX
SG_ API1Output4Device2Status : 51|3@1+ (1,0) [0|7] "" Vector__XXX
SG_ API1Output4EnableCommand : 54|2@1+ (1,0) [0|3] "" Vector__XXX

BO_ 2565923838 API1_O4_FDBK: 8 Vector__XXX
SG_ API1Output4FrequencyFeedback : 0|8@1+ (1,0) [0|250] "Hz" Vector__XXX
SG_ API1Output4VoltageFeedback : 8|8@1+ (2,0) [0|500] "Vrms" Vector__XXX
SG_ API1Output4PowerFeedback : 16|8@1+ (0.1,0) [0|25] "kW" Vector__XXX
SG_ API1Output4StatusFeedback : 48|3@1+ (1,0) [0|7] "" Vector__XXX
SG_ API1Output4LoadshedRequest : 51|2@1+ (1,0) [0|3] "" Vector__XXX
SG_ API1Output4HVILStatus : 53|2@1+ (1,0) [0|3] "" Vector__XXX

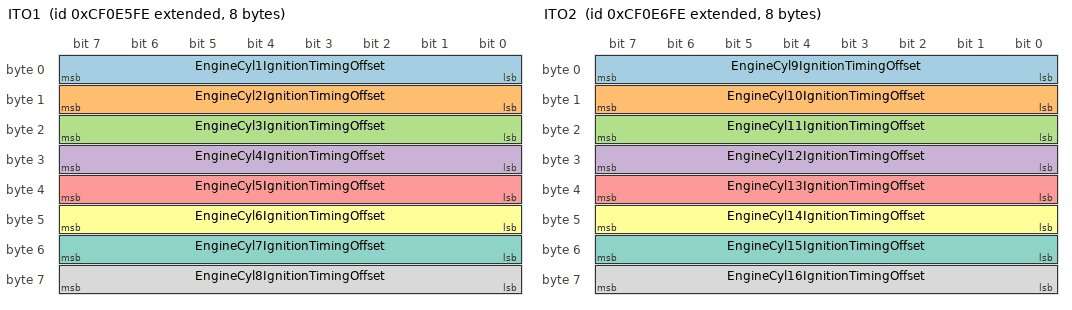
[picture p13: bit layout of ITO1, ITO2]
BO_ 2364597758 ITO1: 8 Vector__XXX
SG_ EngineCyl1IgnitionTimingOffset : 0|8@1+ (0.1,-12.5) [-12.5|12.5] "deg" Vector__XXX
SG_ EngineCyl2IgnitionTimingOffset : 8|8@1+ (0.1,-12.5) [-12.5|12.5] "deg" Vector__XXX
SG_ EngineCyl3IgnitionTimingOffset : 16|8@1+ (0.1,-12.5) [-12.5|12.5] "deg" Vector__XXX
SG_ EngineCyl4IgnitionTimingOffset : 24|8@1+ (0.1,-12.5) [-12.5|12.5] "deg" Vector__XXX
SG_ EngineCyl5IgnitionTimingOffset : 32|8@1+ (0.1,-12.5) [-12.5|12.5] "deg" Vector__XXX
SG_ EngineCyl6IgnitionTimingOffset : 40|8@1+ (0.1,-12.5) [-12.5|12.5] "deg" Vector__XXX
SG_ EngineCyl7IgnitionTimingOffset : 48|8@1+ (0.1,-12.5) [-12.5|12.5] "deg" Vector__XXX
SG_ EngineCyl8IgnitionTimingOffset : 56|8@1+ (0.1,-12.5) [-12.5|12.5] "deg" Vector__XXX

BO_ 2364598014 ITO2: 8 Vector__XXX
SG_ EngineCyl9IgnitionTimingOffset : 0|8@1+ (0.1,-12.5) [-12.5|12.5] "deg" Vector__XXX
SG_ EngineCyl10IgnitionTimingOffset : 8|8@1+ (0.1,-12.5) [-12.5|12.5] "deg" Vector__XXX
SG_ EngineCyl11IgnitionTimingOffset : 16|8@1+ (0.1,-12.5) [-12.5|12.5] "deg" Vector__XXX
SG_ EngineCyl12IgnitionTimingOffset : 24|8@1+ (0.1,-12.5) [-12.5|12.5] "deg" Vector__XXX
SG_ EngineCyl13IgnitionTimingOffset : 32|8@1+ (0.1,-12.5) [-12.5|12.5] "deg" Vector__XXX
SG_ EngineCyl14IgnitionTimingOffset : 40|8@1+ (0.1,-12.5) [-12.5|12.5] "deg" Vector__XXX
SG_ EngineCyl15IgnitionTimingOffset : 48|8@1+ (0.1,-12.5) [-12.5|12.5] "deg" Vector__XXX
SG_ EngineCyl16IgnitionTimingOffset : 56|8@1+ (0.1,-12.5) [-12.5|12.5] "deg" Vector__XXX

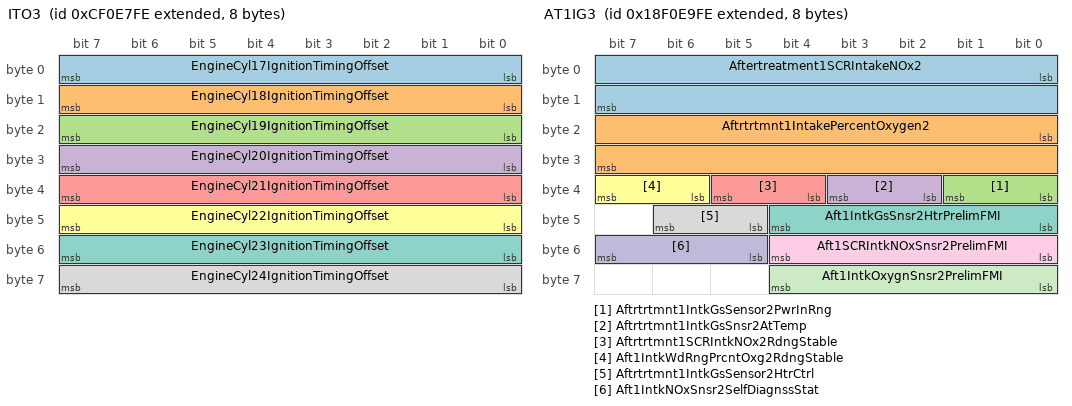
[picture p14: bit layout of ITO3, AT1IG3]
BO_ 2364598270 ITO3: 8 Vector__XXX
SG_ EngineCyl17IgnitionTimingOffset : 0|8@1+ (0.1,-12.5) [-12.5|12.5] "deg" Vector__XXX
SG_ EngineCyl18IgnitionTimingOffset : 8|8@1+ (0.1,-12.5) [-12.5|12.5] "deg" Vector__XXX
SG_ EngineCyl19IgnitionTimingOffset : 16|8@1+ (0.1,-12.5) [-12.5|12.5] "deg" Vector__XXX
SG_ EngineCyl20IgnitionTimingOffset : 24|8@1+ (0.1,-12.5) [-12.5|12.5] "deg" Vector__XXX
SG_ EngineCyl21IgnitionTimingOffset : 32|8@1+ (0.1,-12.5) [-12.5|12.5] "deg" Vector__XXX
SG_ EngineCyl22IgnitionTimingOffset : 40|8@1+ (0.1,-12.5) [-12.5|12.5] "deg" Vector__XXX
SG_ EngineCyl23IgnitionTimingOffset : 48|8@1+ (0.1,-12.5) [-12.5|12.5] "deg" Vector__XXX
SG_ EngineCyl24IgnitionTimingOffset : 56|8@1+ (0.1,-12.5) [-12.5|12.5] "deg" Vector__XXX

BO_ 2364598526 TFAC2: 8 Vector__XXX
SG_ EngineFuelActr3ControlCommand : 32|16@1+ (0.0025,0) [0|160.6375] "%" Vector__XXX
SG_ EngineFuelActr4ControlCommand : 48|16@1+ (0.0025,0) [0|160.6375] "%" Vector__XXX

BO_ 2565925374 AT1IG3: 8 Vector__XXX
SG_ Aftertreatment1SCRIntakeNOx2 : 0|16@1+ (0.05,-200) [-200|3012.75] "ppm" Vector__XXX
SG_ Aftrtrtmnt1IntakePercentOxygen2 : 16|16@1+ (0.000514,-12) [-12|21.02707] "%" Vector__XXX
SG_ Aftrtrtmnt1IntkGsSensor2PwrInRng : 32|2@1+ (1,0) [0|3] "" Vector__XXX
SG_ Aftrtrtmnt1IntkGsSnsr2AtTemp : 34|2@1+ (1,0) [0|3] "" Vector__XXX
SG_ Aftrtrtmnt1SCRIntkNOx2RdngStable : 36|2@1+ (1,0) [0|3] "" Vector__XXX
SG_ Aft1IntkWdRngPrcntOxg2RdngStable : 38|2@1+ (1,0) [0|3] "" Vector__XXX
SG_ Aft1IntkGsSnsr2HtrPrelimFMI : 40|5@1+ (1,0) [0|31] "" Vector__XXX
SG_ Aftrtrtmnt1IntkGsSensor2HtrCtrl : 45|2@1+ (1,0) [0|3] "" Vector__XXX
SG_ Aft1SCRIntkNOxSnsr2PrelimFMI : 48|5@1+ (1,0) [0|31] "" Vector__XXX
SG_ Aft1IntkNOxSnsr2SelfDiagnssStat : 53|3@1+ (1,0) [0|7] "" Vector__XXX
SG_ Aft1IntkOxygnSnsr2PrelimFMI : 56|5@1+ (1,0) [0|31] "" Vector__XXX

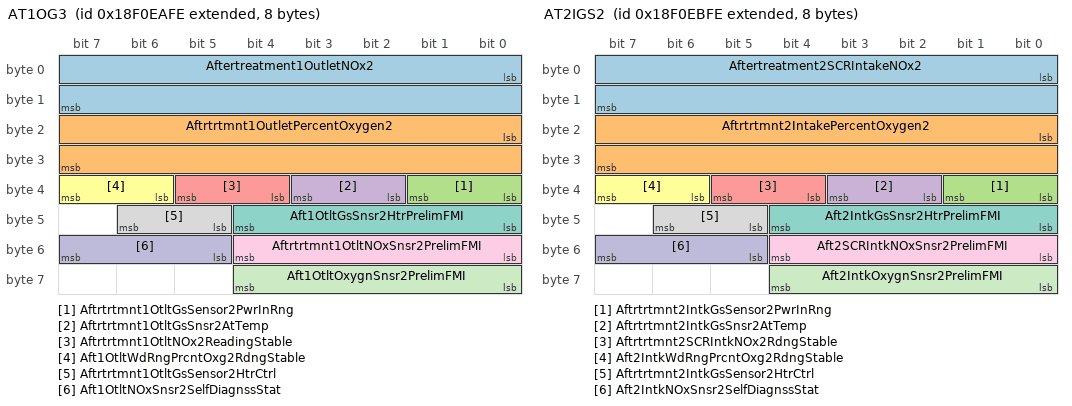
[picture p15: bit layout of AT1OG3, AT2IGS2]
BO_ 2565925630 AT1OG3: 8 Vector__XXX
SG_ Aftertreatment1OutletNOx2 : 0|16@1+ (0.05,-200) [-200|3012.75] "ppm" Vector__XXX
SG_ Aftrtrtmnt1OutletPercentOxygen2 : 16|16@1+ (0.000514,-12) [-12|21.02707] "%" Vector__XXX
SG_ Aftrtrtmnt1OtltGsSensor2PwrInRng : 32|2@1+ (1,0) [0|3] "" Vector__XXX
SG_ Aftrtrtmnt1OtltGsSnsr2AtTemp : 34|2@1+ (1,0) [0|3] "" Vector__XXX
SG_ Aftrtrtmnt1OtltNOx2ReadingStable : 36|2@1+ (1,0) [0|3] "" Vector__XXX
SG_ Aft1OtltWdRngPrcntOxg2RdngStable : 38|2@1+ (1,0) [0|3] "" Vector__XXX
SG_ Aft1OtltGsSnsr2HtrPrelimFMI : 40|5@1+ (1,0) [0|31] "" Vector__XXX
SG_ Aftrtrtmnt1OtltGsSensor2HtrCtrl : 45|2@1+ (1,0) [0|3] "" Vector__XXX
SG_ Aftrtrtmnt1OtltNOxSnsr2PrelimFMI : 48|5@1+ (1,0) [0|31] "" Vector__XXX
SG_ Aft1OtltNOxSnsr2SelfDiagnssStat : 53|3@1+ (1,0) [0|7] "" Vector__XXX
SG_ Aft1OtltOxygnSnsr2PrelimFMI : 56|5@1+ (1,0) [0|31] "" Vector__XXX

BO_ 2565925886 AT2IGS2: 8 Vector__XXX
SG_ Aftertreatment2SCRIntakeNOx2 : 0|16@1+ (0.05,-200) [-200|3012.75] "ppm" Vector__XXX
SG_ Aftrtrtmnt2IntakePercentOxygen2 : 16|16@1+ (0.000514,-12) [-12|21.02707] "%" Vector__XXX
SG_ Aftrtrtmnt2IntkGsSensor2PwrInRng : 32|2@1+ (1,0) [0|3] "" Vector__XXX
SG_ Aftrtrtmnt2IntkGsSnsr2AtTemp : 34|2@1+ (1,0) [0|3] "" Vector__XXX
SG_ Aftrtrtmnt2SCRIntkNOx2RdngStable : 36|2@1+ (1,0) [0|3] "" Vector__XXX
SG_ Aft2IntkWdRngPrcntOxg2RdngStable : 38|2@1+ (1,0) [0|3] "" Vector__XXX
SG_ Aft2IntkGsSnsr2HtrPrelimFMI : 40|5@1+ (1,0) [0|31] "" Vector__XXX
SG_ Aftrtrtmnt2IntkGsSensor2HtrCtrl : 45|2@1+ (1,0) [0|3] "" Vector__XXX
SG_ Aft2SCRIntkNOxSnsr2PrelimFMI : 48|5@1+ (1,0) [0|31] "" Vector__XXX
SG_ Aft2IntkNOxSnsr2SelfDiagnssStat : 53|3@1+ (1,0) [0|7] "" Vector__XXX
SG_ Aft2IntkOxygnSnsr2PrelimFMI : 56|5@1+ (1,0) [0|31] "" Vector__XXX

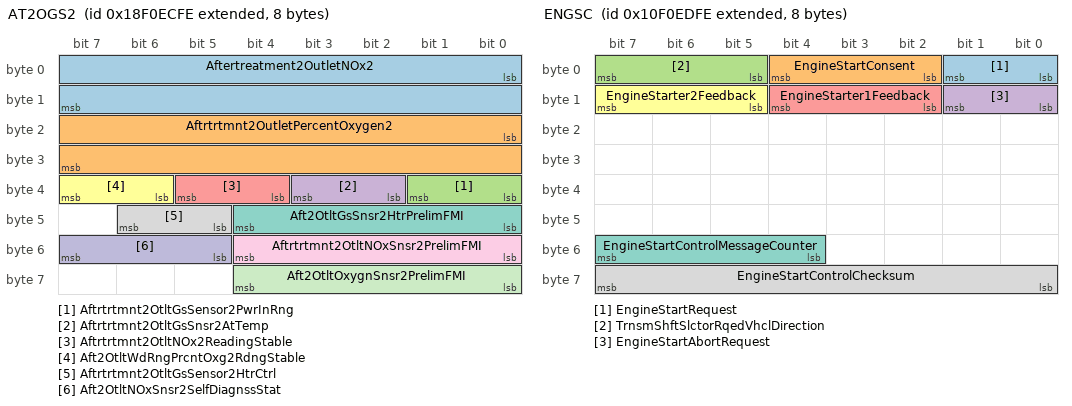
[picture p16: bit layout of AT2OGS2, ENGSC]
BO_ 2565926142 AT2OGS2: 8 Vector__XXX
SG_ Aftertreatment2OutletNOx2 : 0|16@1+ (0.05,-200) [-200|3012.75] "ppm" Vector__XXX
SG_ Aftrtrtmnt2OutletPercentOxygen2 : 16|16@1+ (0.000514,-12) [-12|21.02707] "%" Vector__XXX
SG_ Aftrtrtmnt2OtltGsSensor2PwrInRng : 32|2@1+ (1,0) [0|3] "" Vector__XXX
SG_ Aftrtrtmnt2OtltGsSnsr2AtTemp : 34|2@1+ (1,0) [0|3] "" Vector__XXX
SG_ Aftrtrtmnt2OtltNOx2ReadingStable : 36|2@1+ (1,0) [0|3] "" Vector__XXX
SG_ Aft2OtltWdRngPrcntOxg2RdngStable : 38|2@1+ (1,0) [0|3] "" Vector__XXX
SG_ Aft2OtltGsSnsr2HtrPrelimFMI : 40|5@1+ (1,0) [0|31] "" Vector__XXX
SG_ Aftrtrtmnt2OtltGsSensor2HtrCtrl : 45|2@1+ (1,0) [0|3] "" Vector__XXX
SG_ Aftrtrtmnt2OtltNOxSnsr2PrelimFMI : 48|5@1+ (1,0) [0|31] "" Vector__XXX
SG_ Aft2OtltNOxSnsr2SelfDiagnssStat : 53|3@1+ (1,0) [0|7] "" Vector__XXX
SG_ Aft2OtltOxygnSnsr2PrelimFMI : 56|5@1+ (1,0) [0|31] "" Vector__XXX

BO_ 2431708670 ENGSC: 8 Vector__XXX
SG_ EngineStartRequest : 0|2@1+ (1,0) [0|3] "" Vector__XXX
SG_ EngineStartConsent : 2|3@1+ (1,0) [0|7] "" Vector__XXX
SG_ TrnsmShftSlctorRqedVhclDirection : 5|3@1+ (1,0) [0|7] "" Vector__XXX
SG_ EngineStartAbortRequest : 8|2@1+ (1,0) [0|3] "" Vector__XXX
SG_ EngineStarter1Feedback : 10|3@1+ (1,0) [0|7] "" Vector__XXX
SG_ EngineStarter2Feedback : 13|3@1+ (1,0) [0|7] "" Vector__XXX
SG_ EngineStartControlMessageCounter : 52|4@1+ (1,0) [0|15] "" Vector__XXX
SG_ EngineStartControlChecksum : 56|8@1+ (1,0) [0|255] "" Vector__XXX

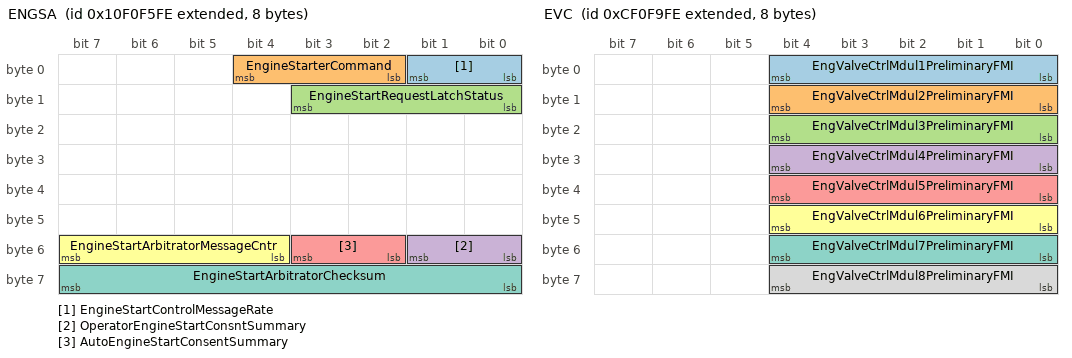
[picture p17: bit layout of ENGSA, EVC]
BO_ 2431710718 ENGSA: 8 Vector__XXX
SG_ EngineStartControlMessageRate : 0|2@1+ (1,0) [0|3] "" Vector__XXX
SG_ EngineStarterCommand : 2|3@1+ (1,0) [0|7] "" Vector__XXX
SG_ EngineStartRequestLatchStatus : 8|4@1+ (1,0) [0|15] "" Vector__XXX
SG_ OperatorEngineStartConsntSummary : 48|2@1+ (1,0) [0|3] "" Vector__XXX
SG_ AutoEngineStartConsentSummary : 50|2@1+ (1,0) [0|3] "" Vector__XXX
SG_ EngineStartArbitratorMessageCntr : 52|4@1+ (1,0) [0|15] "" Vector__XXX
SG_ EngineStartArbitratorChecksum : 56|8@1+ (1,0) [0|255] "" Vector__XXX

BO_ 2364602878 EVC: 8 Vector__XXX
SG_ EngValveCtrlMdul1PreliminaryFMI : 0|5@1+ (1,0) [0|31] "" Vector__XXX
SG_ EngValveCtrlMdul2PreliminaryFMI : 8|5@1+ (1,0) [0|31] "" Vector__XXX
SG_ EngValveCtrlMdul3PreliminaryFMI : 16|5@1+ (1,0) [0|31] "" Vector__XXX
SG_ EngValveCtrlMdul4PreliminaryFMI : 24|5@1+ (1,0) [0|31] "" Vector__XXX
SG_ EngValveCtrlMdul5PreliminaryFMI : 32|5@1+ (1,0) [0|31] "" Vector__XXX
SG_ EngValveCtrlMdul6PreliminaryFMI : 40|5@1+ (1,0) [0|31] "" Vector__XXX
SG_ EngValveCtrlMdul7PreliminaryFMI : 48|5@1+ (1,0) [0|31] "" Vector__XXX
SG_ EngValveCtrlMdul8PreliminaryFMI : 56|5@1+ (1,0) [0|31] "" Vector__XXX

BO_ 2364603134 ETC13: 8 Vector__XXX
SG_ MaxFrwdTransmissionOutptShftSpd : 0|16@1+ (0.125,0) [0|8031.875] "rpm" Vector__XXX
SG_ MaxReverseTrnsmOutptShftSpd : 16|16@1+ (0.125,0) [0|8031.875] "rpm" Vector__XXX
SG_ SrcAddrActvPendingTrnsmRqedGear : 32|8@1+ (1,0) [0|255] "" Vector__XXX

BO_ 2364603390 A1SCRDSR3: 8 Vector__XXX
SG_ Aft1DslExhstFldRqedQtyIntgrtr : 0|16@1+ (0.001,0) [0|64.255] "g" Vector__XXX
SG_ Aft1DslExhstFldDoserVlv1Cmd : 16|16@1+ (0.0025,0) [0|160.6375] "%" Vector__XXX

BO_ 2364603646 A2SCRDSR3: 8 Vector__XXX
SG_ Aft2DslExhstFldRqedQtyIntgrtr : 0|16@1+ (0.001,0) [0|64.255] "g" Vector__XXX

BO_ 2364603902 A1SCRDSI4: 8 Vector__XXX
SG_ Aft1DslExhstFldActlQtyIntgrtr : 0|16@1+ (0.001,0) [0|64.255] "g" Vector__XXX

BO_ 2364604158 A2SCRDSI4: 8 Vector__XXX
SG_ Aft2DslExhstFldActlQtyIntgrtr : 0|16@1+ (0.001,0) [0|64.255] "g" Vector__XXX

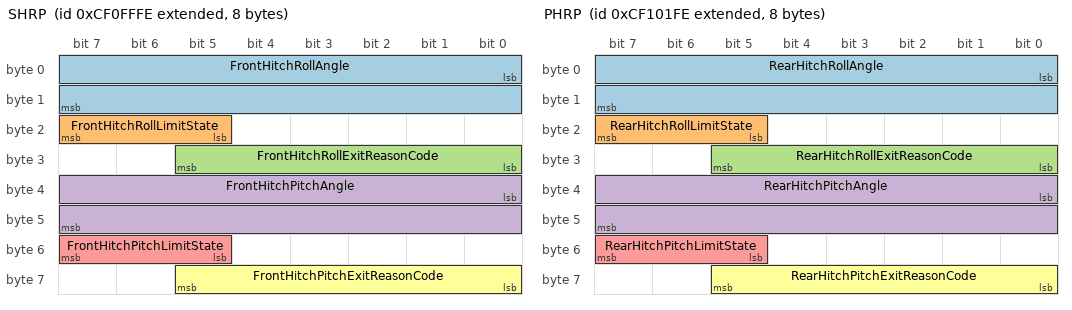
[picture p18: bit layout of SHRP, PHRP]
BO_ 2364604414 SHRP: 8 Vector__XXX
SG_ FrontHitchRollAngle : 0|16@1+ (0.002,-64) [-64|64.51] "deg" Vector__XXX
SG_ FrontHitchRollLimitState : 21|3@1+ (1,0) [0|7] "" Vector__XXX
SG_ FrontHitchRollExitReasonCode : 24|6@1+ (1,0) [0|63] "" Vector__XXX
SG_ FrontHitchPitchAngle : 32|16@1+ (0.002,-64) [-64|64.51] "deg" Vector__XXX
SG_ FrontHitchPitchLimitState : 53|3@1+ (1,0) [0|7] "" Vector__XXX
SG_ FrontHitchPitchExitReasonCode : 56|6@1+ (1,0) [0|63] "" Vector__XXX

BO_ 2364604670 SHRPC: 8 Vector__XXX
SG_ FrontHitchRollCommand : 0|16@1+ (0.002,-64) [-64|64.51] "deg" Vector__XXX
SG_ FrontHitchRollSensitivityCommand : 16|8@1+ (0.4,0) [0|100] "%" Vector__XXX
SG_ FrontHitchPitchCommand : 24|16@1+ (0.002,-64) [-64|64.51] "deg" Vector__XXX
SG_ FrontHitchPitchSensitivityCmd : 40|8@1+ (0.4,0) [0|100] "%" Vector__XXX

BO_ 2364604926 PHRP: 8 Vector__XXX
SG_ RearHitchRollAngle : 0|16@1+ (0.002,-64) [-64|64.51] "deg" Vector__XXX
SG_ RearHitchRollLimitState : 21|3@1+ (1,0) [0|7] "" Vector__XXX
SG_ RearHitchRollExitReasonCode : 24|6@1+ (1,0) [0|63] "" Vector__XXX
SG_ RearHitchPitchAngle : 32|16@1+ (0.002,-64) [-64|64.51] "deg" Vector__XXX
SG_ RearHitchPitchLimitState : 53|3@1+ (1,0) [0|7] "" Vector__XXX
SG_ RearHitchPitchExitReasonCode : 56|6@1+ (1,0) [0|63] "" Vector__XXX

BO_ 2364605182 PHRPC: 8 Vector__XXX
SG_ RearHitchRollCommand : 0|16@1+ (0.002,-64) [-64|64.51] "deg" Vector__XXX
SG_ RearHitchRollSensitivityCommand : 16|8@1+ (0.4,0) [0|100] "%" Vector__XXX
SG_ RearHitchPitchCommand : 24|16@1+ (0.002,-64) [-64|64.51] "deg" Vector__XXX
SG_ RearHitchPitchSensitivityCommand : 40|8@1+ (0.4,0) [0|100] "%" Vector__XXX

BO_ 2364605438 GTRACE: 8 Vector__XXX
SG_ GeneratorTripKWHoursExport : 0|32@1+ (1,0) [0|4211081215] "kWh" Vector__XXX
SG_ GeneratorTripKVArHoursExport : 32|32@1+ (1,0) [0|4211081215] "kVArh" Vector__XXX

BO_ 2565932286 ESSI2: 8 Vector__XXX
SG_ EngineSpeed4 : 0|16@1+ (0.5,0) [0|32127.5] "rpm" Vector__XXX

BO_ 2364605950 HPD: 8 Vector__XXX
SG_ HydraulicLinePressure : 0|16@1+ (1,0) [0|64255] "kPa" Vector__XXX
SG_ MechanicalMovementAngle : 16|16@1+ (0.0078125,0) [0|501.99] "deg" Vector__XXX

BO_ 2565932798 WSP1: 8 Vector__XXX
SG_ WellStimulationPumpSuctionPress : 0|16@1+ (0.1,-3212.7) [-3212.7|3212.8] "kPa" Vector__XXX
SG_ WellStimulationPumpDisChrgPress : 16|16@1+ (5,0) [0|321275] "kPa" Vector__XXX

BO_ 2565933054 WSP2: 8 Vector__XXX
SG_ WellStimulationPmpGearBoxOilPrs : 0|16@1+ (0.1,0) [0|6425.5] "kPa" Vector__XXX
SG_ WellStimulationPmpGearBoxOilTemp : 16|8@1+ (1,-40) [-40|210] "deg C" Vector__XXX
SG_ WellStimulationPumpSpeed : 24|16@1+ (0.125,0) [0|8031.875] "rpm" Vector__XXX

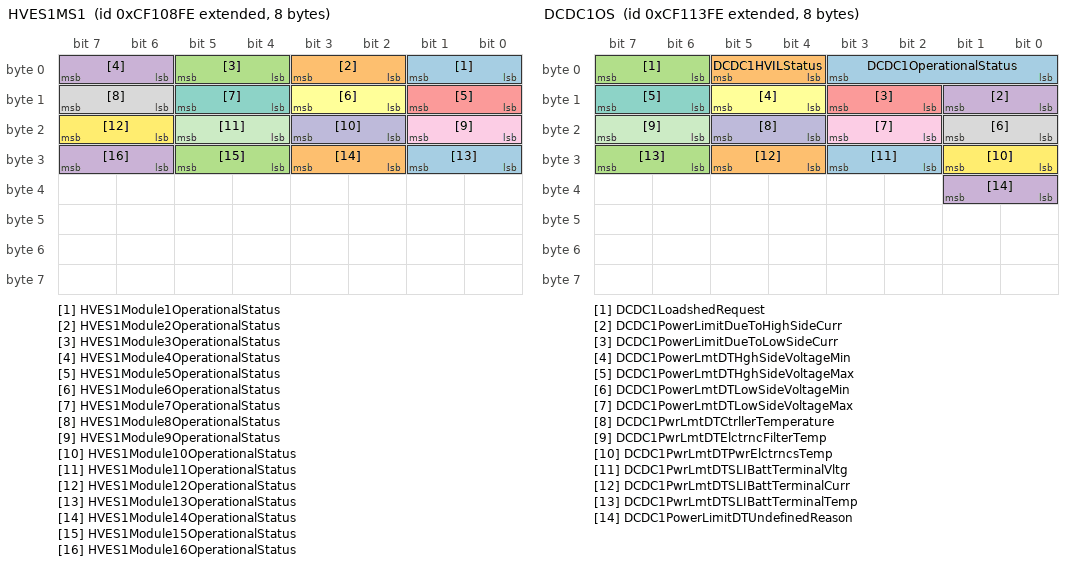
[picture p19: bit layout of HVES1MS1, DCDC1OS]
BO_ 2364606718 HVES1MS1: 8 Vector__XXX
SG_ HVES1Module1OperationalStatus : 0|2@1+ (1,0) [0|3] "" Vector__XXX
SG_ HVES1Module2OperationalStatus : 2|2@1+ (1,0) [0|3] "" Vector__XXX
SG_ HVES1Module3OperationalStatus : 4|2@1+ (1,0) [0|3] "" Vector__XXX
SG_ HVES1Module4OperationalStatus : 6|2@1+ (1,0) [0|3] "" Vector__XXX
SG_ HVES1Module5OperationalStatus : 8|2@1+ (1,0) [0|3] "" Vector__XXX
SG_ HVES1Module6OperationalStatus : 10|2@1+ (1,0) [0|3] "" Vector__XXX
SG_ HVES1Module7OperationalStatus : 12|2@1+ (1,0) [0|3] "" Vector__XXX
SG_ HVES1Module8OperationalStatus : 14|2@1+ (1,0) [0|3] "" Vector__XXX
SG_ HVES1Module9OperationalStatus : 16|2@1+ (1,0) [0|3] "" Vector__XXX
SG_ HVES1Module10OperationalStatus : 18|2@1+ (1,0) [0|3] "" Vector__XXX
SG_ HVES1Module11OperationalStatus : 20|2@1+ (1,0) [0|3] "" Vector__XXX
SG_ HVES1Module12OperationalStatus : 22|2@1+ (1,0) [0|3] "" Vector__XXX
SG_ HVES1Module13OperationalStatus : 24|2@1+ (1,0) [0|3] "" Vector__XXX
SG_ HVES1Module14OperationalStatus : 26|2@1+ (1,0) [0|3] "" Vector__XXX
SG_ HVES1Module15OperationalStatus : 28|2@1+ (1,0) [0|3] "" Vector__XXX
SG_ HVES1Module16OperationalStatus : 30|2@1+ (1,0) [0|3] "" Vector__XXX

BO_ 2364606974 HVES1TS1: 8 Vector__XXX
SG_ HVES1ThermalMangmntSysSLIInptPwr : 0|16@1+ (0.5,0) [0|32127.5] "W" Vector__XXX
SG_ HVES1ThrmlMngmtSysHiVltgInptPwr : 16|16@1+ (0.5,0) [0|32127.5] "W" Vector__XXX
SG_ HVES1ThrmlMangmntSysCmprssorSpd : 32|8@1+ (32,0) [0|8000] "rpm" Vector__XXX
SG_ HVES1ThermalMangmntSysRelHumidty : 40|8@1+ (0.4,0) [0|100] "%" Vector__XXX
SG_ HVES1ThermalMangmntSystemHtrStat : 48|2@1+ (1,0) [0|3] "" Vector__XXX
SG_ HVES1ThermalManagementSystemMode : 52|4@1+ (1,0) [0|15] "" Vector__XXX

BO_ 2364607230 HVES1D8: 8 Vector__XXX
SG_ HVES1HghestCellVoltageMdulNumber : 0|8@1+ (1,0) [0|250] "" Vector__XXX
SG_ HVES1HghestCellVoltageCellNumber : 8|8@1+ (1,0) [0|250] "" Vector__XXX
SG_ HVES1LowestCellVoltageMdulNumber : 16|8@1+ (1,0) [0|250] "" Vector__XXX
SG_ HVES1LowestCellVoltageCellNumber : 24|8@1+ (1,0) [0|250] "" Vector__XXX
SG_ HVES1AverageCellVoltage : 32|16@1+ (0.001,0) [0|64.255] "V" Vector__XXX

BO_ 2364607486 HVES1D9: 8 Vector__XXX
SG_ HVES1HghestCellTemperatureMdulNo : 0|8@1+ (1,0) [0|250] "" Vector__XXX
SG_ HVES1HghestCellTemperatureCellNo : 8|8@1+ (1,0) [0|250] "" Vector__XXX
SG_ HVES1LowestCellTemperatureMdulNo : 16|8@1+ (1,0) [0|250] "" Vector__XXX
SG_ HVES1LowestCellTemperatureCellNo : 24|8@1+ (1,0) [0|250] "" Vector__XXX

BO_ 2364607742 HVES1D10: 8 Vector__XXX
SG_ HVES1HghestCellStateChrgMdulNo : 0|8@1+ (1,0) [0|250] "" Vector__XXX
SG_ HVES1HghestCellStateChrgCellNo : 8|8@1+ (1,0) [0|250] "" Vector__XXX
SG_ HVES1LowestCellStateChrgMdulNo : 16|8@1+ (1,0) [0|250] "" Vector__XXX
SG_ HVES1LowestCellStateChrgCellNo : 24|8@1+ (1,0) [0|250] "" Vector__XXX
SG_ HVES1HiVltgBusActIsolatnTestRess : 32|16@1+ (0.1,0) [0|6425.5] "ohm/V" Vector__XXX
SG_ HVES1HiVltgBusPassIsolatnTtRess : 48|16@1+ (0.1,0) [0|6425.5] "ohm/V" Vector__XXX

BO_ 2565934590 GFI6: 8 Vector__XXX
SG_ EngineFuelValve2DiffPressure : 0|16@1+ (0.1,0) [0|6425.5] "kPa" Vector__XXX

BO_ 2498825982 DTBI1: 8 Vector__XXX
SG_ DumpBodyRollAngle : 0|16@1+ (0.0078125,-200) [-200|301.99] "deg" Vector__XXX
SG_ DumpBodyRaiseAngle : 16|16@1+ (0.0078125,-200) [-200|301.99] "deg" Vector__XXX
SG_ DumpBodyRaisePsRelToRecmmndedMax : 32|16@1+ (0.005,-150) [-150|171.275] "%" Vector__XXX
SG_ DumpBodyEjectorBladePosition : 48|8@1+ (0.4,0) [0|100] "%" Vector__XXX

BO_ 2364608510 EOI2: 8 Vector__XXX
SG_ EngineSelfInducedDerateLoad : 0|16@1+ (0.5,0) [0|32127.5] "kW" Vector__XXX
SG_ EnginePowerDerateRequest : 16|16@1+ (0.5,0) [0|32127.5] "kW" Vector__XXX

BO_ 2297499902 B2: 8 Vector__XXX
SG_ DemandedBrakeApplicationPressure : 0|16@1+ (0.1,0) [0|6425.5] "kPa" Vector__XXX
SG_ BrakePedalSwitch2 : 16|2@1+ (1,0) [0|3] "" Vector__XXX

BO_ 2431717886 GFP3: 8 Vector__XXX
SG_ EngineFuelValve1DiffPressure : 0|16@1+ (0.0078125,-100) [-100|401.99] "kPa" Vector__XXX

BO_ 2364609278 DCDC1C: 8 Vector__XXX
SG_ DCDC1OperationalCommand : 0|4@1+ (1,0) [0|15] "" Vector__XXX
SG_ DCDC1LowSideVoltageBuckSetpoint : 8|16@1+ (0.01,0) [0|642.55] "V" Vector__XXX
SG_ DCDC1HghSideVoltageBoostSetpoint : 24|16@1+ (0.05,0) [0|3212.75] "V" Vector__XXX

BO_ 2364609534 DCDC1OS: 8 Vector__XXX
SG_ DCDC1OperationalStatus : 0|4@1+ (1,0) [0|15] "" Vector__XXX
SG_ DCDC1HVILStatus : 4|2@1+ (1,0) [0|3] "" Vector__XXX
SG_ DCDC1LoadshedRequest : 6|2@1+ (1,0) [0|3] "" Vector__XXX
SG_ DCDC1PowerLimitDueToHighSideCurr : 8|2@1+ (1,0) [0|3] "" Vector__XXX
SG_ DCDC1PowerLimitDueToLowSideCurr : 10|2@1+ (1,0) [0|3] "" Vector__XXX
SG_ DCDC1PowerLmtDTHghSideVoltageMin : 12|2@1+ (1,0) [0|3] "" Vector__XXX
SG_ DCDC1PowerLmtDTHghSideVoltageMax : 14|2@1+ (1,0) [0|3] "" Vector__XXX
SG_ DCDC1PowerLmtDTLowSideVoltageMin : 16|2@1+ (1,0) [0|3] "" Vector__XXX
SG_ DCDC1PowerLmtDTLowSideVoltageMax : 18|2@1+ (1,0) [0|3] "" Vector__XXX
SG_ DCDC1PwrLmtDTCtrllerTemperature : 20|2@1+ (1,0) [0|3] "" Vector__XXX
SG_ DCDC1PwrLmtDTElctrncFilterTemp : 22|2@1+ (1,0) [0|3] "" Vector__XXX
SG_ DCDC1PwrLmtDTPwrElctrncsTemp : 24|2@1+ (1,0) [0|3] "" Vector__XXX
SG_ DCDC1PwrLmtDTSLIBattTerminalVltg : 26|2@1+ (1,0) [0|3] "" Vector__XXX
SG_ DCDC1PwrLmtDTSLIBattTerminalCurr : 28|2@1+ (1,0) [0|3] "" Vector__XXX
SG_ DCDC1PwrLmtDTSLIBattTerminalTemp : 30|2@1+ (1,0) [0|3] "" Vector__XXX
SG_ DCDC1PowerLimitDTUndefinedReason : 32|2@1+ (1,0) [0|3] "" Vector__XXX

BO_ 2364609790 DCDC1VC: 8 Vector__XXX
SG_ DCDC1LowSideVoltage : 0|16@1+ (0.01,0) [0|642.55] "V" Vector__XXX
SG_ DCDC1LowSideCurrent : 16|16@1+ (0.1,-3212.7) [-3212.7|3212.8] "A" Vector__XXX
SG_ DCDC1HighSideVoltage : 32|16@1+ (0.05,0) [0|3212.75] "V" Vector__XXX
SG_ DCDC1HighSideCurrent : 48|16@1+ (0.1,-3212.7) [-3212.7|3212.8] "A" Vector__XXX

BO_ 2364610046 DCDC1SBS: 8 Vector__XXX
SG_ DCDC1SLIBatteryTerminalVoltage : 0|16@1+ (0.01,0) [0|642.55] "V" Vector__XXX
SG_ DCDC1SLIBatteryTerminalCurrent : 16|16@1+ (0.1,-3212.7) [-3212.7|3212.8] "A" Vector__XXX
SG_ DCDC1SLIBattryTerminalTemp : 32|8@1+ (1,-40) [-40|210] "deg C" Vector__XXX

BO_ 2431719166 WSP3: 8 Vector__XXX
SG_ WellStimulationPumpRodLoad : 0|16@1+ (5,0) [0|321275] "kN" Vector__XXX
SG_ WellStimulationPmpCavitationStat : 16|3@1+ (1,0) [0|7] "" Vector__XXX
SG_ WellStimultnPmpFldEndValveLeak : 20|2@1+ (1,0) [0|3] "" Vector__XXX
SG_ WellStimulationPumpFlowRate : 24|16@1+ (0.5,0) [0|32127.5] "l/min" Vector__XXX

BO_ 2364610558 DCDC1S2: 8 Vector__XXX
SG_ DCDC1LowSidePower : 0|16@1+ (0.05,-1600) [-1600|1612.75] "kW" Vector__XXX
SG_ DCDC1HighSidePower : 16|16@1+ (0.05,-1600) [-1600|1612.75] "kW" Vector__XXX

BO_ 2566638590 EEPCSI: 8 Vector__XXX
SG_ ExhstPrtcltCtrlSystemDiagTime : 0|32@1+ (1,0) [0|4211081215] "s" Vector__XXX
SG_ ExhstPrtcltCtrlSystemDiagCnt : 32|32@1+ (1,0) [0|4211081215] "" Vector__XXX

BO_ 2566638846 WSPH: 16 Vector__XXX
SG_ WellStimultnPmpMaintenIntvalHrs : 0|32@1+ (1,0) [0|4211081215] "s" Vector__XXX
SG_ WellStimulationPumpValveOpHrs : 32|32@1+ (1,0) [0|4211081215] "s" Vector__XXX
SG_ WellStimulationPumpPackingOpHrs : 64|32@1+ (1,0) [0|4211081215] "s" Vector__XXX
SG_ WellStimulationPmpValveSeatOpHrs : 96|32@1+ (1,0) [0|4211081215] "s" Vector__XXX

BO_ 2566639102 WSPT2: 19 Vector__XXX
SG_ WellStimPmpGrBxOilPrsLoTrshldStt : 0|16@1+ (0.1,0) [0|6425.5] "kPa" Vector__XXX
SG_ WellStimPmpGrBxOilPrsHiTrshldStt : 16|16@1+ (0.1,0) [0|6425.5] "kPa" Vector__XXX
SG_ WellStimPmpGrBxOilTmpLoTrshldStt : 32|8@1+ (1,-40) [-40|210] "deg C" Vector__XXX
SG_ WellStimPmpGrBxOilTmpHiTrshldStt : 40|8@1+ (1,-40) [-40|210] "deg C" Vector__XXX
SG_ WellStimPmpSuctionPrsLoTrshldStt : 48|16@1+ (0.1,-3212.7) [-3212.7|3212.8] "kPa" Vector__XXX
SG_ WellStimPmpSuctionPrsHiTrshldStt : 64|16@1+ (0.1,-3212.7) [-3212.7|3212.8] "kPa" Vector__XXX
SG_ WellStimPmpDisChrgPrsHiTrshldStt : 80|16@1+ (5,0) [0|321275] "kPa" Vector__XXX
SG_ WellStimuPmpCrankSpdLoTrshldStt : 96|16@1+ (0.125,0) [0|8031.875] "rpm" Vector__XXX
SG_ WellStimuPmpCrankSpdHiTrshldStt : 112|16@1+ (0.125,0) [0|8031.875] "rpm" Vector__XXX
SG_ WellStimuPmpRodLoadHiTrshldStt : 128|16@1+ (5,0) [0|321275] "kN" Vector__XXX
SG_ WellStimPmpPlungerFiringOrderStt : 144|4@1+ (1,0) [0|15] "" Vector__XXX

BO_ 2633748222 CRSS: 8 Vector__XXX
SG_ ReceiveSPNsPort : 0|4@1+ (1,0) [0|15] "" Vector__XXX
SG_ ReceiveSPNsPortPendingChangesSt : 4|1@1+ (1,0) [0|1] "" Vector__XXX
SG_ ReceiveSPNsPortCommandStatus : 5|3@1+ (1,0) [0|7] "" Vector__XXX
SG_ ConfigurableReceiveSPN : 16|19@1+ (1,0) [0|524287] "" Vector__XXX
SG_ ConfigurableReceiveSPNDetailedSt : 32|5@1+ (1,0) [0|31] "" Vector__XXX
SG_ ConfigurableReceiveSPNSourceAddr : 40|8@1+ (1,0) [0|255] "" Vector__XXX
SG_ ConfigurableReceiveSPNModifiedSt : 48|2@1+ (1,0) [0|3] "" Vector__XXX

BO_ 2566639614 DCDC1LD: 16 Vector__XXX
SG_ DCDC1TotalHighSideEnergy : 0|32@1+ (100,0) [0|421108121500] "Watt-hour" Vector__XXX
SG_ DCDC1TotalLowSideEnergy : 32|32@1+ (100,0) [0|421108121500] "Watt-hour" Vector__XXX
SG_ DCDC1TotalHighSideCharge : 64|32@1+ (100,0) [0|421108121500] "Ah" Vector__XXX
SG_ DCDC1TotalLowSideCharge : 96|32@1+ (100,0) [0|421108121500] "Ah" Vector__XXX

BO_ 2566639870 DCDC1CFG1: 17 Vector__XXX
SG_ DCDC1HghSideVoltageMinLmtSetting : 0|16@1+ (0.05,0) [0|3212.75] "V" Vector__XXX
SG_ DCDC1HghSideVoltageMaxLmtSetting : 16|16@1+ (0.05,0) [0|3212.75] "V" Vector__XXX
SG_ DCDC1HghSideCurrMaxLmtSetting : 32|16@1+ (0.05,0) [0|3212.75] "A" Vector__XXX
SG_ DCDC1LowSideVoltageMinLmtSetting : 48|16@1+ (0.01,0) [0|642.55] "V" Vector__XXX
SG_ DCDC1LowSideVoltageMaxLmtSetting : 64|16@1+ (0.01,0) [0|642.55] "V" Vector__XXX
SG_ DCDC1LowSideCurrMaxLmtSetting : 80|16@1+ (0.05,0) [0|3212.75] "A" Vector__XXX
SG_ DCDC1SLIBattTermnlVltgMaxLmtStt : 96|16@1+ (0.01,0) [0|642.55] "V" Vector__XXX
SG_ DCDC1SLIBattTermChrgCurMaxLmtStt : 112|16@1+ (0.05,0) [0|3212.75] "A" Vector__XXX
SG_ DCDC1SLIBattryTempMaxLmtSttng : 128|8@1+ (1,-40) [-40|210] "deg C" Vector__XXX

BO_ 2365313534 DCDC1SBL: 8 Vector__XXX
SG_ DCDC1SLIBattryTermnlVltgMaxLmtRq : 0|16@1+ (0.01,0) [0|642.55] "V" Vector__XXX
SG_ DCDC1SLIBattTermChrgCurMaxLmtRq : 16|16@1+ (0.05,0) [0|3212.75] "A" Vector__XXX
SG_ DCDC1SLIBattryTempMaxLmtRq : 32|8@1+ (1,-40) [-40|210] "deg C" Vector__XXX

BO_ 2566640382 POM: 8 Vector__XXX
SG_ WellStimulationPumpOilViscosity : 0|16@1+ (0.015625,0) [0|1003.984375] "Cp" Vector__XXX
SG_ WellStimulationPumpOilDensity : 16|16@1+ (3.052E-005,0) [0|1.961] "g/cc" Vector__XXX
SG_ WellStimuPmpOilRelDielectricity : 32|16@1+ (0.0001220703125,0) [0|7.844] "" Vector__XXX
SG_ WellStimulationPmpOilTemperature : 48|16@1+ (0.03125,-273) [-273|1734.96875] "deg C" Vector__XXX

BO_ 2633749502 WSPT: 16 Vector__XXX
SG_ WellStimultnPmpFldEndWorkingHrs : 0|32@1+ (1,0) [0|4211081215] "s" Vector__XXX
SG_ WellStimultnPmpPwrEndWorkingHrs : 32|32@1+ (1,0) [0|4211081215] "s" Vector__XXX
SG_ WellStimulationPumpWorkingHours : 64|32@1+ (1,0) [0|4211081215] "s" Vector__XXX
SG_ WellStimulationPumpCycleCount : 96|32@1+ (1,0) [0|4211081215] "" Vector__XXX

BO_ 2633749758 WSPC: 8 Vector__XXX
SG_ WellStimultnPmpPlungerDiameter : 0|16@1+ (1,0) [0|64255] "mm" Vector__XXX
SG_ WellStimulationPumpStrokeLength : 16|16@1+ (1,0) [0|64255] "mm" Vector__XXX
SG_ WellStimulationPumpGearRatio : 32|16@1+ (0.001,0) [0|64.255] "" Vector__XXX
SG_ WellStimulationPumpRatedSpeed : 48|16@1+ (0.125,0) [0|8031.875] "rpm" Vector__XXX

BO_ 2566641150 ACOCF2: 8 Vector__XXX
SG_ AltrntrBearingHeaderIntkPressure : 0|8@1+ (2,0) [0|500] "kPa" Vector__XXX
SG_ AltrntrOilCoolDisChrgPumpPress : 8|8@1+ (2,0) [0|500] "kPa" Vector__XXX
SG_ EngineOilCoolDisChrgPumpPressure : 16|8@1+ (2,0) [0|500] "kPa" Vector__XXX
SG_ EngineOilCoolerIntakeTemperature : 24|8@1+ (1,-40) [-40|210] "deg C" Vector__XXX

BO_ 2566641406 EEC21: 8 Vector__XXX
SG_ EngExhaustManifoldAbsPressure1 : 0|16@1+ (0.1,0) [0|6425.5] "kPa" Vector__XXX
SG_ EngExhaustManifoldAbsPressure2 : 16|16@1+ (0.1,0) [0|6425.5] "kPa" Vector__XXX

CM_ BO_ 2565869566 "Aftertreatment 1 Outlet Gas 1";
CM_ BO_ 2565869822 "Aftertreatment 2 Intake Gas 1";
CM_ BO_ 2565870078 "Aftertreatment 2 Outlet Gas 1";
CM_ BO_ 2565870334 "Fifth Wheel Smart Systems 1";
CM_ BO_ 2364543998 "Slope Sensor Information";
CM_ BO_ 2364544254 "Blade Information";
CM_ BO_ 2364544510 "Requested Generator Total AC Reactive Power";
CM_ BO_ 2364544766 "Cylinder Combustion Status";
CM_ BO_ 2364545022 "Engine Knock Level #1";
CM_ BO_ 2364545278 "Engine Knock Level #2";
CM_ BO_ 2364545534 "Engine Knock Level #3";
CM_ BO_ 2431654654 "Engine Throttle / Fuel Actuator Control Command";
CM_ BO_ 2364546302 "Requested Generator Average Basic AC Quantities";
CM_ BO_ 2565873150 "Steering Angle Sensor Information";
CM_ BO_ 2364546814 "Generator Control 2";
CM_ BO_ 2565874174 "Engine Speed Sensor Information 1";
CM_ BO_ 2364548094 "Aftertreatment 1 SCR Dosing System Information 1";
CM_ BO_ 2364548350 "Aftertreatment 1 SCR Dosing System Requests 1";
CM_ BO_ 2364548606 "Aftertreatment 1 SCR Ammonia Information";
CM_ BO_ 2364548862 "Aftertreatment 2 SCR Dosing System Information 1";
CM_ BO_ 2364549118 "Aftertreatment 2 SCR Dosing System Requests 1";
CM_ BO_ 2364549374 "Aftertreatment 2 SCR Ammonia Information";
CM_ BO_ 2364549630 "Slope Sensor Information 2";
CM_ BO_ 2364549886 "Angular Rate Information";
CM_ BO_ 2163223550 "Crash Notification";
CM_ BO_ 2297441534 "Magnet Status Information 2";
CM_ BO_ 2297441790 "Acceleration Sensor";
CM_ BO_ 2565877502 "Engine Turbocharger Control";
CM_ BO_ 2364551166 "Advanced Emergency Braking System 1";
CM_ BO_ 2364551422 "Wireless Status";
CM_ BO_ 2230333950 "Wand Sensor";
CM_ BO_ 2230334206 "Linear Displacement Sensor";
CM_ BO_ 2431661054 "Aftertreatment 1 SCR Ammonia Information 2";
CM_ BO_ 2431661310 "Aftertreatment 2 SCR Ammonia Information 2";
CM_ BO_ 2364552958 "High Voltage Energy Storage 1 Status 2";
CM_ BO_ 2364553214 "Engine Turbocharger Blowoff Actuator 1";
CM_ BO_ 2364553470 "Engine Torque / Fuel Request";
CM_ BO_ 2364553726 "Engine Air System Information";
CM_ BO_ 2364553982 "Engine Cylinder 1 Combustion Information";
CM_ BO_ 2364554238 "Engine Cylinder 2 Combustion Information";
CM_ BO_ 2364554494 "Engine Cylinder 3 Combustion Information";
CM_ BO_ 2364554750 "Engine Cylinder 4 Combustion Information";
CM_ BO_ 2364555006 "Engine Cylinder 5 Combustion Information";
CM_ BO_ 2364555262 "Engine Cylinder 6 Combustion Information";
CM_ BO_ 2364555518 "Engine Cylinder 7 Combustion Information";
CM_ BO_ 2364555774 "Engine Cylinder 8 Combustion Information";
CM_ BO_ 2364556030 "Engine Cylinder 9 Combustion Information";
CM_ BO_ 2364556286 "Engine Cylinder 10 Combustion Information";
CM_ BO_ 2364556542 "Engine Cylinder 11 Combustion Information";
CM_ BO_ 2364556798 "Engine Cylinder 12 Combustion Information";
CM_ BO_ 2364557054 "Engine Cylinder 13 Combustion Information";
CM_ BO_ 2364557310 "Engine Cylinder 14 Combustion Information";
CM_ BO_ 2364557566 "Engine Cylinder 15 Combustion Information";
CM_ BO_ 2364557822 "Engine Cylinder 16 Combustion Information";
CM_ BO_ 2364558078 "Engine Cylinder 17 Combustion Information";
CM_ BO_ 2364558334 "Engine Cylinder 18 Combustion Information";
CM_ BO_ 2364558590 "Engine Cylinder 19 Combustion Information";
CM_ BO_ 2364558846 "Engine Cylinder 20 Combustion Information";
CM_ BO_ 2498776830 "Engine Cylinder 1 Combustion Average Information";
CM_ BO_ 2498777086 "Engine Cylinder 2 Combustion Average Information";
CM_ BO_ 2498777342 "Engine Cylinder 3 Combustion Average Information";
CM_ BO_ 2498777598 "Engine Cylinder 4 Combustion Average Information";
CM_ BO_ 2498777854 "Engine Cylinder 5 Combustion Average Information";
CM_ BO_ 2498778110 "Engine Cylinder 6 Combustion Average Information";
CM_ BO_ 2498778366 "Engine Cylinder 7 Combustion Average Information";
CM_ BO_ 2498778622 "Engine Cylinder 8 Combustion Average Information";
CM_ BO_ 2498778878 "Engine Cylinder 9 Combustion Average Information";
CM_ BO_ 2498779134 "Engine Cylinder 10 Combustion Average Information";
CM_ BO_ 2498779390 "Engine Cylinder 11 Combustion Average Information";
CM_ BO_ 2498779646 "Engine Cylinder 12 Combustion Average Information";
CM_ BO_ 2498779902 "Engine Cylinder 13 Combustion Average Information";
CM_ BO_ 2498780158 "Engine Cylinder 14 Combustion Average Information";
CM_ BO_ 2498780414 "Engine Cylinder 15 Combustion Average Information";
CM_ BO_ 2498780670 "Engine Cylinder 16 Combustion Average Information";
CM_ BO_ 2498780926 "Engine Cylinder 17 Combustion Average Information";
CM_ BO_ 2498781182 "Engine Cylinder 18 Combustion Average Information";
CM_ BO_ 2498781438 "Engine Cylinder 19 Combustion Average Information";
CM_ BO_ 2498781694 "Engine Cylinder 20 Combustion Average Information";
CM_ BO_ 2297455358 "Electronic Transmission Controller #12";
CM_ BO_ 2364564478 "Fuel Information 5 (Gaseous)";
CM_ BO_ 2364564734 "Engine Gaseous Fuel Valve Duration Command 1";
CM_ BO_ 2364564990 "Engine Gaseous Fuel Valve Duration Command 2";
CM_ BO_ 2364565246 "Engine Gaseous Fuel Valve Duration Command 3";
CM_ BO_ 2364565502 "Engine Gaseous Fuel Valve Duration Command 4";
CM_ BO_ 2364565758 "Engine Gaseous Fuel Valve Duration Command 5";
CM_ BO_ 2364566014 "Engine Gaseous Fuel Valve Start of Actuation Command 1";
CM_ BO_ 2364566270 "Engine Gaseous Fuel Valve Start of Actuation Command 2";
CM_ BO_ 2364566526 "Engine Gaseous Fuel Valve Start of Actuation Command 3";
CM_ BO_ 2364566782 "Engine Gaseous Fuel Valve Start of Actuation Command 4";
CM_ BO_ 2364567038 "Engine Gaseous Fuel Valve Start of Actuation Command 5";
CM_ BO_ 2364567294 "Fuel Pump Actuator Control Command";
CM_ BO_ 2364575998 "High Voltage Energy Storage 1 Data 1";
CM_ BO_ 2364576254 "High Voltage Energy Storage 1 Data 2";
CM_ BO_ 2364576510 "High Voltage Energy Storage 1 Data 3";
CM_ BO_ 2364576766 "High Voltage Energy Storage 1 Data 4";
CM_ BO_ 2364577022 "High Voltage Energy Storage 1 Data 5";
CM_ BO_ 2364577278 "High Voltage Energy Storage 1 Data 6";
CM_ BO_ 2364577534 "High Voltage Energy Storage 1 Status 1";
CM_ BO_ 2364580094 "High Voltage Energy Storage 1 Data 7";
CM_ BO_ 2364592382 "Engine Cylinder Combustion Request";
CM_ BO_ 2364592638 "Engine Cylinder Head Bypass Actuator 1";
CM_ BO_ 2364592894 "Engine Electronic Controller 18";
CM_ BO_ 2364593150 "Predictive Cruise Control 1";
CM_ BO_ 2565920510 "API 1 Output 1 Energy Consumer Command";
CM_ BO_ 2565920766 "API 1 Output 1 Energy Consumer Feedback";
CM_ BO_ 2565921534 "API 1 Output 2 Energy Consumer Command";
CM_ BO_ 2565921790 "API 1 Output 2 Energy Consumer Feedback";
CM_ BO_ 2565922558 "API 1 Output 3 Energy Consumer Command";
CM_ BO_ 2565922814 "API 1 Output 3 Energy Consumer Feedback";
CM_ BO_ 2565923582 "API 1 Output 4 Energy Consumer Command";
CM_ BO_ 2565923838 "API 1 Output 4 Energy Consumer Feedback";
CM_ BO_ 2364597758 "Engine Ignition Timing Offset 1";
CM_ BO_ 2364598014 "Engine Ignition Timing Offset 2";
CM_ BO_ 2364598270 "Engine Ignition Timing Offset 3";
CM_ BO_ 2364598526 "Engine Throttle / Fuel Actuator Control Command 2";
CM_ BO_ 2565925374 "Aftertreatment 1 Intake Gas 3";
CM_ BO_ 2565925630 "Aftertreatment 1 Outlet Gas 3";
CM_ BO_ 2565925886 "Aftertreatment 2 Intake Gas Sensor 2";
CM_ BO_ 2565926142 "Aftertreatment 2 Outlet Gas Sensor 2";
CM_ BO_ 2431708670 "Engine Start Control";
CM_ BO_ 2431710718 "Engine Start Arbitrator";
CM_ BO_ 2364602878 "Engine Valve Controller";
CM_ BO_ 2364603134 "Electronic Transmission Controller 13";
CM_ BO_ 2364603390 "Aftertreatment 1 SCR Dosing System Requests 3";
CM_ BO_ 2364603646 "Aftertreatment 2 SCR Dosing System Requests 3";
CM_ BO_ 2364603902 "Aftertreatment 1 SCR Dosing System Information 4";
CM_ BO_ 2364604158 "Aftertreatment 2 SCR Dosing System Information 4";
CM_ BO_ 2364604414 "Secondary or Front Hitch Roll and Pitch";
CM_ BO_ 2364604670 "Secondary or Front Hitch Roll and Pitch Command";
CM_ BO_ 2364604926 "Primary or Rear Hitch Roll and Pitch";
CM_ BO_ 2364605182 "Primary or Rear Hitch Roll and Pitch Command";
CM_ BO_ 2364605438 "Generator Trip Energy";
CM_ BO_ 2565932286 "Engine Speed Sensor Information 2";
CM_ BO_ 2364605950 "Hydraulic Pressure Displacement";
CM_ BO_ 2565932798 "Well Stimulation Pump System 1";
CM_ BO_ 2565933054 "Well Stimulation Pump System 2";
CM_ BO_ 2364606718 "High Voltage Energy Storage 1 Module Status 1";
CM_ BO_ 2364606974 "High Voltage Energy Storage 1 Thermal Management System Status 1";
CM_ BO_ 2364607230 "High Voltage Energy Storage 1 Data 8";
CM_ BO_ 2364607486 "High Voltage Energy Storage 1 Data 9";
CM_ BO_ 2364607742 "High Voltage Energy Storage 1 Data 10";
CM_ BO_ 2565934590 "Fuel Information 6 (Gaseous)";
CM_ BO_ 2498825982 "Dump Truck Body Information";
CM_ BO_ 2364608510 "Engine Operating Information 2";
CM_ BO_ 2297499902 "Brakes 2";
CM_ BO_ 2431717886 "Gaseous Fuel Pressure 3";
CM_ BO_ 2364609278 "DC/DC Converter 1 Control";
CM_ BO_ 2364609534 "DC/DC Converter 1 Operating Status";
CM_ BO_ 2364609790 "DC/DC Converter 1 Voltage and Current";
CM_ BO_ 2364610046 "DC/DC Converter 1 SLI Battery Status";
CM_ BO_ 2431719166 "Well Stimulation Pump System 3";
CM_ BO_ 2364610558 "DC/DC Converter 1 Status 2";
CM_ BO_ 2566638590 "Engine Exhaust Particulate Control System Info";
CM_ BO_ 2566638846 "Well Stimulation Pump Hours";
CM_ BO_ 2566639102 "Well Stimulation Pump System Configuration Status";
CM_ BO_ 2633748222 "Configurable Receive SPNs Status";
CM_ BO_ 2566639614 "DC/DC Converter 1 Lifetime Data";
CM_ BO_ 2566639870 "DC/DC Converter 1 Configuration 1";
CM_ BO_ 2365313534 "DC/DC Converter 1 SLI Battery Limits";
CM_ BO_ 2566640382 "Pump Oil Message";
CM_ BO_ 2633749502 "Well Stimulation Pump System Lifetime Totals";
CM_ BO_ 2633749758 "Well Stimulation Pump System Configuration";
CM_ BO_ 2566641150 "Aftercooler and Oil Cooler Fluids 2";
CM_ BO_ 2566641406 "Electronic Engine Controller 21";
BA_DEF_ BO_  "VFrameFormat" ENUM  "StandardCAN","ExtendedCAN","reserved","J1939PG";
BA_DEF_ BO_  "GenMsgCycleTime" INT 0 65535;
BA_DEF_ SG_  "GenSigStartValue" FLOAT -3.4E+038 3.4E+038;
BA_DEF_ SG_  "SPN" INT ;
BA_DEF_ SG_  "SigType" ENUM "Default","Range","RangeSigned","ASCII","Discrete","Control","ReferencePGN","DTC","StringDelimiter","StringLength","StringLengthControl","MessageCounter","MessageChecksum";
BA_DEF_DEF_  "VFrameFormat" "J1939PG";
BA_DEF_DEF_  "GenMsgCycleTime" 0;
BA_DEF_DEF_  "GenSigStartValue" 0;
BA_DEF_DEF_  "SPN" 0;
BA_DEF_DEF_  "SigType" "Default";
BA_ "GenMsgCycleTime" BO_ 2565869566 50;
BA_ "GenMsgCycleTime" BO_ 2565869822 50;
BA_ "GenMsgCycleTime" BO_ 2565870078 50;
BA_ "GenMsgCycleTime" BO_ 2565870334 50;
BA_ "GenMsgCycleTime" BO_ 2364543998 10;
BA_ "GenMsgCycleTime" BO_ 2364544254 50;
BA_ "GenMsgCycleTime" BO_ 2364544510 100;
BA_ "GenMsgCycleTime" BO_ 2364544766 5000;
BA_ "GenMsgCycleTime" BO_ 2364545022 5000;
BA_ "GenMsgCycleTime" BO_ 2364545278 5000;
BA_ "GenMsgCycleTime" BO_ 2364545534 5000;
BA_ "GenMsgCycleTime" BO_ 2431654654 50;
BA_ "GenMsgCycleTime" BO_ 2364546302 100;
BA_ "GenMsgCycleTime" BO_ 2565873150 10;
BA_ "GenMsgCycleTime" BO_ 2364546814 20;
BA_ "GenMsgCycleTime" BO_ 2364548094 50;
BA_ "GenMsgCycleTime" BO_ 2364548350 50;
BA_ "GenMsgCycleTime" BO_ 2364548606 50;
BA_ "GenMsgCycleTime" BO_ 2364548862 50;
BA_ "GenMsgCycleTime" BO_ 2364549118 50;
BA_ "GenMsgCycleTime" BO_ 2364549374 50;
BA_ "GenMsgCycleTime" BO_ 2364549630 10;
BA_ "GenMsgCycleTime" BO_ 2364549886 10;
BA_ "GenMsgCycleTime" BO_ 2163223550 20;
BA_ "GenMsgCycleTime" BO_ 2297441534 50;
BA_ "GenMsgCycleTime" BO_ 2297441790 10;
BA_ "GenMsgCycleTime" BO_ 2364551166 50;
BA_ "GenMsgCycleTime" BO_ 2364551422 50;
BA_ "GenMsgCycleTime" BO_ 2230333950 20;
BA_ "GenMsgCycleTime" BO_ 2230334206 20;
BA_ "GenMsgCycleTime" BO_ 2431661054 50;
BA_ "GenMsgCycleTime" BO_ 2431661310 50;
BA_ "GenMsgCycleTime" BO_ 2364552958 100;
BA_ "GenMsgCycleTime" BO_ 2364553214 100;
BA_ "GenMsgCycleTime" BO_ 2364553470 20;
BA_ "GenMsgCycleTime" BO_ 2364553726 20;
BA_ "GenMsgCycleTime" BO_ 2297455358 10;
BA_ "GenMsgCycleTime" BO_ 2364567294 50;
BA_ "GenMsgCycleTime" BO_ 2364575998 20;
BA_ "GenMsgCycleTime" BO_ 2364576254 20;
BA_ "GenMsgCycleTime" BO_ 2364576510 20;
BA_ "GenMsgCycleTime" BO_ 2364576766 100;
BA_ "GenMsgCycleTime" BO_ 2364577022 20;
BA_ "GenMsgCycleTime" BO_ 2364577278 100;
BA_ "GenMsgCycleTime" BO_ 2364577534 100;
BA_ "GenMsgCycleTime" BO_ 2364580094 100;
BA_ "GenMsgCycleTime" BO_ 2364592638 100;
BA_ "GenMsgCycleTime" BO_ 2364592894 100;
BA_ "GenMsgCycleTime" BO_ 2364593150 100;
BA_ "GenMsgCycleTime" BO_ 2565920510 100;
BA_ "GenMsgCycleTime" BO_ 2565920766 100;
BA_ "GenMsgCycleTime" BO_ 2565921534 100;
BA_ "GenMsgCycleTime" BO_ 2565921790 100;
BA_ "GenMsgCycleTime" BO_ 2565922558 100;
BA_ "GenMsgCycleTime" BO_ 2565922814 100;
BA_ "GenMsgCycleTime" BO_ 2565923582 100;
BA_ "GenMsgCycleTime" BO_ 2565923838 100;
BA_ "GenMsgCycleTime" BO_ 2364598526 50;
BA_ "GenMsgCycleTime" BO_ 2565925374 50;
BA_ "GenMsgCycleTime" BO_ 2565925630 50;
BA_ "GenMsgCycleTime" BO_ 2565925886 50;
BA_ "GenMsgCycleTime" BO_ 2565926142 50;
BA_ "GenMsgCycleTime" BO_ 2431708670 20;
BA_ "GenMsgCycleTime" BO_ 2431710718 20;
BA_ "GenMsgCycleTime" BO_ 2364602878 100;
BA_ "GenMsgCycleTime" BO_ 2364603134 100;
BA_ "GenMsgCycleTime" BO_ 2364603390 50;
BA_ "GenMsgCycleTime" BO_ 2364603646 50;
BA_ "GenMsgCycleTime" BO_ 2364603902 50;
BA_ "GenMsgCycleTime" BO_ 2364604158 50;
BA_ "GenMsgCycleTime" BO_ 2364604414 100;
BA_ "GenMsgCycleTime" BO_ 2364604670 100;
BA_ "GenMsgCycleTime" BO_ 2364604926 100;
BA_ "GenMsgCycleTime" BO_ 2364605182 100;
BA_ "GenMsgCycleTime" BO_ 2364605438 100;
BA_ "GenMsgCycleTime" BO_ 2364605950 20;
BA_ "GenMsgCycleTime" BO_ 2565932798 50;
BA_ "GenMsgCycleTime" BO_ 2565933054 50;
BA_ "GenMsgCycleTime" BO_ 2364606718 100;
BA_ "GenMsgCycleTime" BO_ 2364606974 100;
BA_ "GenMsgCycleTime" BO_ 2364607230 100;
BA_ "GenMsgCycleTime" BO_ 2364607486 100;
BA_ "GenMsgCycleTime" BO_ 2364607742 100;
BA_ "GenMsgCycleTime" BO_ 2565934590 100;
BA_ "GenMsgCycleTime" BO_ 2498825982 50;
BA_ "GenMsgCycleTime" BO_ 2364608510 100;
BA_ "GenMsgCycleTime" BO_ 2297499902 1000;
BA_ "GenMsgCycleTime" BO_ 2431717886 100;
BA_ "GenMsgCycleTime" BO_ 2364609278 100;
BA_ "GenMsgCycleTime" BO_ 2364609534 100;
BA_ "GenMsgCycleTime" BO_ 2364609790 100;
BA_ "GenMsgCycleTime" BO_ 2364610046 100;
BA_ "GenMsgCycleTime" BO_ 2431719166 50;
BA_ "GenMsgCycleTime" BO_ 2364610558 100;
BA_ "GenMsgCycleTime" BO_ 2566638590 10000;
BA_ "GenMsgCycleTime" BO_ 2566639870 5000;
BA_ "GenMsgCycleTime" BO_ 2365313534 1000;
BA_ "GenMsgCycleTime" BO_ 2566641150 1000;
BA_ "GenMsgCycleTime" BO_ 2566641406 100;
BA_ "SPN" SG_ 2565869566 Aftertreatment1OutletNOx 3226;
BA_ "SPN" SG_ 2565869566 Aftertreatment1OutletPercentO2 3227;
BA_ "SPN" SG_ 2565869566 Aftrtrtmnt1OtltGasSensorPwrInRng 3228;
BA_ "SPN" SG_ 2565869566 Aftrtrtmnt1OtltGasSnsrAtTemp 3229;
BA_ "SPN" SG_ 2565869566 Aftrtrtmnt1OtltNOxReadingStable 3230;
BA_ "SPN" SG_ 2565869566 Aftrtrtmnt1OtltWdRngO2RdngStable 3231;
BA_ "SPN" SG_ 2565869566 Aft1OtltGasSnsrHtrPrelimFMI 3232;
BA_ "SPN" SG_ 2565869566 Aftrtrtmnt1OtltGasSensorHtrCtrl 3233;
BA_ "SPN" SG_ 2565869566 Aftrtrtmnt1OtltNOxSnsrPrelimFMI 3234;
BA_ "SPN" SG_ 2565869566 Aft1OtltNOxSnsrSelfDiagnssStat 5713;
BA_ "SPN" SG_ 2565869566 Aftrtrtmnt1OtltO2SensorPrelimFMI 3235;
BA_ "SPN" SG_ 2565869822 Aft2SlctiveCtlytcRedIntkNOx 3255;
BA_ "SPN" SG_ 2565869822 Aftertreatment2IntakePercentO2 3256;
BA_ "SPN" SG_ 2565869822 Aftrtrtmnt2IntkGasSensorPwrInRng 3257;
BA_ "SPN" SG_ 2565869822 Aftrtrtmnt2IntkGasSnsrAtTemp 3258;
BA_ "SPN" SG_ 2565869822 Aft2SlctiveCtlytcRedIntkNOxRdngS 3259;
BA_ "SPN" SG_ 2565869822 Aft2IntkWdRngPrcntO2RdngStable 3260;
BA_ "SPN" SG_ 2565869822 Aft2IntkGasSnsrHtrPrelimFMI 3261;
BA_ "SPN" SG_ 2565869822 Aftrtrtmnt2IntkGasSensorHtrCtrl 3262;
BA_ "SPN" SG_ 2565869822 Aft2SlctiveCtlytcRedIntkNOxSnsrP 3263;
BA_ "SPN" SG_ 2565869822 Aft2IntkNOxSnsrSelfDiagnssStat 5716;
BA_ "SPN" SG_ 2565869822 Aftrtrtmnt2IntkO2SensorPrelimFMI 3264;
BA_ "SPN" SG_ 2565869822 Aftrtrtmnt2Intk2GsSnsrPwrSupply 8485;
BA_ "SPN" SG_ 2565870078 Aftertreatment2OutletNOx 3265;
BA_ "SPN" SG_ 2565870078 Aftertreatment2OutletPercentO2 3266;
BA_ "SPN" SG_ 2565870078 Aftrtrtmnt2OtltGasSensorPwrInRng 3267;
BA_ "SPN" SG_ 2565870078 Aftrtrtmnt2OtltGasSnsrAtTemp 3268;
BA_ "SPN" SG_ 2565870078 Aftrtrtmnt2OtltNOxReadingStable 3269;
BA_ "SPN" SG_ 2565870078 Aftrtrtmnt2OtltWdRngO2RdngStable 3270;
BA_ "SPN" SG_ 2565870078 Aft2OtltGasSnsrHtrPrelimFMI 3271;
BA_ "SPN" SG_ 2565870078 Aftrtrtmnt2OtltGasSensorHtrCtrl 3272;
BA_ "SPN" SG_ 2565870078 Aftrtrtmnt2OtltNOxSnsrPrelimFMI 3273;
BA_ "SPN" SG_ 2565870078 Aft2OtltNOxSnsrSelfDiagnssStat 5715;
BA_ "SPN" SG_ 2565870078 Aftrtrtmnt2OtltO2SensorPrelimFMI 3274;
BA_ "SPN" SG_ 2565870078 Aftrtrtmnt2Otlt2GsSnsrPwrSupply 8486;
BA_ "SPN" SG_ 2565870334 FifthWheelVerticalForce 3308;
BA_ "SPN" SG_ 2565870334 FifthWheelDrawbarForce 3309;
BA_ "SPN" SG_ 2565870334 FifthWheelRollMoment 3310;
BA_ "SPN" SG_ 2565870334 FifthWheelRollWarningIndicator 3317;
BA_ "SPN" SG_ 2364543998 PitchAngle 3318;
BA_ "SPN" SG_ 2364543998 RollAngle 3319;
BA_ "SPN" SG_ 2364543998 PitchRate 3322;
BA_ "SPN" SG_ 2364543998 PitchAngleFigureOfMerit 3323;
BA_ "SPN" SG_ 2364543998 RollAngleFigureOfMerit 3324;
BA_ "SPN" SG_ 2364543998 PitchRateFigureOfMerit 3325;
BA_ "SPN" SG_ 2364543998 PitchAndRollCompensated 3326;
BA_ "SPN" SG_ 2364543998 RollAndPitchMeasurementLatency 3327;
BA_ "SPN" SG_ 2364544254 RelativeBladeHeight 3365;
BA_ "SPN" SG_ 2364544254 BladeRotationAngle 3331;
BA_ "SPN" SG_ 2364544254 RelBldHghtAndBldRotAglMeasureLat 3366;
BA_ "SPN" SG_ 2364544254 RelativeBladeHeightFigureOfMerit 3367;
BA_ "SPN" SG_ 2364544254 BladeRotationAngleFigureOfMerit 3332;
BA_ "SPN" SG_ 2364544510 RequestedGenTotalACReActvPower 3383;
BA_ "SPN" SG_ 2364544510 RequestedGenOverallPowerFactor 3384;
BA_ "SPN" SG_ 2364544510 RqedGenOverallPwrFactorLagging 3385;
BA_ "SPN" SG_ 2364544766 EngineCylinder1CombustionStatus 3387;
BA_ "SPN" SG_ 2364544766 EngineCylinder2CombustionStatus 3388;
BA_ "SPN" SG_ 2364544766 EngineCylinder3CombustionStatus 3389;
BA_ "SPN" SG_ 2364544766 EngineCylinder4CombustionStatus 3390;
BA_ "SPN" SG_ 2364544766 EngineCylinder5CombustionStatus 3391;
BA_ "SPN" SG_ 2364544766 EngineCylinder6CombustionStatus 3392;
BA_ "SPN" SG_ 2364544766 EngineCylinder7CombustionStatus 3393;
BA_ "SPN" SG_ 2364544766 EngineCylinder8CombustionStatus 3394;
BA_ "SPN" SG_ 2364544766 EngineCylinder9CombustionStatus 3395;
BA_ "SPN" SG_ 2364544766 EngineCylinder10CombustionStatus 3396;
BA_ "SPN" SG_ 2364544766 EngineCylinder11CombustionStatus 3397;
BA_ "SPN" SG_ 2364544766 EngineCylinder12CombustionStatus 3398;
BA_ "SPN" SG_ 2364544766 EngineCylinder13CombustionStatus 3399;
BA_ "SPN" SG_ 2364544766 EngineCylinder14CombustionStatus 3400;
BA_ "SPN" SG_ 2364544766 EngineCylinder15CombustionStatus 3401;
BA_ "SPN" SG_ 2364544766 EngineCylinder16CombustionStatus 3402;
BA_ "SPN" SG_ 2364544766 EngineCylinder17CombustionStatus 3403;
BA_ "SPN" SG_ 2364544766 EngineCylinder18CombustionStatus 3404;
BA_ "SPN" SG_ 2364544766 EngineCylinder19CombustionStatus 3405;
BA_ "SPN" SG_ 2364544766 EngineCylinder20CombustionStatus 3406;
BA_ "SPN" SG_ 2364544766 EngineCylinder21CombustionStatus 3407;
BA_ "SPN" SG_ 2364544766 EngineCylinder22CombustionStatus 3408;
BA_ "SPN" SG_ 2364544766 EngineCylinder23CombustionStatus 3409;
BA_ "SPN" SG_ 2364544766 EngineCylinder24CombustionStatus 3410;
BA_ "SPN" SG_ 2364545022 EngineCylinder1KnockLevel 1352;
BA_ "SPN" SG_ 2364545022 EngineCylinder2KnockLevel 1353;
BA_ "SPN" SG_ 2364545022 EngineCylinder3KnockLevel 1354;
BA_ "SPN" SG_ 2364545022 EngineCylinder4KnockLevel 1355;
BA_ "SPN" SG_ 2364545022 EngineCylinder5KnockLevel 1356;
BA_ "SPN" SG_ 2364545022 EngineCylinder6KnockLevel 1357;
BA_ "SPN" SG_ 2364545022 EngineCylinder7KnockLevel 1358;
BA_ "SPN" SG_ 2364545022 EngineCylinder8KnockLevel 1359;
BA_ "SPN" SG_ 2364545278 EngineCylinder9KnockLevel 1360;
BA_ "SPN" SG_ 2364545278 EngineCylinder10KnockLevel 1361;
BA_ "SPN" SG_ 2364545278 EngineCylinder11KnockLevel 1362;
BA_ "SPN" SG_ 2364545278 EngineCylinder12KnockLevel 1363;
BA_ "SPN" SG_ 2364545278 EngineCylinder13KnockLevel 1364;
BA_ "SPN" SG_ 2364545278 EngineCylinder14KnockLevel 1365;
BA_ "SPN" SG_ 2364545278 EngineCylinder15KnockLevel 1366;
BA_ "SPN" SG_ 2364545278 EngineCylinder16KnockLevel 1367;
BA_ "SPN" SG_ 2364545534 EngineCylinder17KnockLevel 1368;
BA_ "SPN" SG_ 2364545534 EngineCylinder18KnockLevel 1369;
BA_ "SPN" SG_ 2364545534 EngineCylinder19KnockLevel 1370;
BA_ "SPN" SG_ 2364545534 EngineCylinder20KnockLevel 1371;
BA_ "SPN" SG_ 2364545534 EngineCylinder21KnockLevel 1372;
BA_ "SPN" SG_ 2364545534 EngineCylinder22KnockLevel 1373;
BA_ "SPN" SG_ 2364545534 EngineCylinder23KnockLevel 1374;
BA_ "SPN" SG_ 2364545534 EngineCylinder24KnockLevel 1375;
BA_ "SPN" SG_ 2431654654 EngineThrottleActr1ControlCmd 3464;
BA_ "SPN" SG_ 2431654654 EngineThrottleActr2ControlCmd 3465;
BA_ "SPN" SG_ 2431654654 EngineFuelActr1ControlCommand 633;
BA_ "SPN" SG_ 2431654654 EngineFuelActr2ControlCommand 1244;
BA_ "SPN" SG_ 2364546302 RqedGenAvrgLineLineACRMSVoltage 3386;
BA_ "SPN" SG_ 2565873150 SteeringWheelAngle 3683;
BA_ "SPN" SG_ 2565873150 SteeringWheelAngleRangeCounter 3684;
BA_ "SPN" SG_ 2565873150 SteeringWheelAglRangeCounterType 3685;
BA_ "SPN" SG_ 2565873150 SteeringWheelAngleRange 3686;
BA_ "SPN" SG_ 2565873150 SteeringAngleSensorActiveMode 3687;
BA_ "SPN" SG_ 2565873150 SteeringAngleSensorCalibrated 3688;
BA_ "SPN" SG_ 2565873150 MessageCounter 3689;
BA_ "SPN" SG_ 2565873150 MessageChecksum 3690;
BA_ "SPN" SG_ 2364546814 GeneratorGoverningBias 3938;
BA_ "SPN" SG_ 2364546814 EngineSelfInducedDerateInhibit 8429;
BA_ "SPN" SG_ 2364546814 EngineLoadSetpointRequest 8430;
BA_ "SPN" SG_ 2565874174 EngineSpeed1 4201;
BA_ "SPN" SG_ 2565874174 EngineSpeed2 723;
BA_ "SPN" SG_ 2565874174 EngineSpeed3 4202;
BA_ "SPN" SG_ 2565874174 EngSpeedSnsr3TimingPatternStatus 4205;
BA_ "SPN" SG_ 2565874174 EngSpeedSnsr2TimingPatternStatus 4204;
BA_ "SPN" SG_ 2565874174 EngSpeedSnsr1TimingPatternStatus 4203;
BA_ "SPN" SG_ 2364548094 Aft1DslExhstFldActlDsngQty 4331;
BA_ "SPN" SG_ 2364548094 Aftertreatment1SCRSystemState 4332;
BA_ "SPN" SG_ 2364548094 Aftertreatment1SCRSystem2State 7524;
BA_ "SPN" SG_ 2364548094 Aft1DslExhstFldActlQtyOfIntgrtr 4333;
BA_ "SPN" SG_ 2364548094 Aft1DslExhstFldDoserAbsPress 4334;
BA_ "SPN" SG_ 2364548094 Aft1DslExhstFldActlDsngQtyHiRng 6595;
BA_ "SPN" SG_ 2364548350 Aft1DslExhstFldDsngRqedQty 4348;
BA_ "SPN" SG_ 2364548350 Aftrtrtmnt1SCRSystemRqedState 4349;
BA_ "SPN" SG_ 2364548350 Aft1DslExhstFldHydrStffnssCkPmSt 7517;
BA_ "SPN" SG_ 2364548350 Aft1DslExhstFldDsngTtInjectPmSt 7518;
BA_ "SPN" SG_ 2364548350 Aft1DslExhstFldRqedQtyOfIntgrtr 4350;
BA_ "SPN" SG_ 2364548350 Aft1DslExhstFldDsngRqedQtyHiRng 6593;
BA_ "SPN" SG_ 2364548606 Aftertreatment1OutletNH3 4377;
BA_ "SPN" SG_ 2364548606 Aftrtrtmnt1OtltNH3SnsrPrelimFMI 4378;
BA_ "SPN" SG_ 2364548606 Aftrtrtmnt1OtltNH3ReadingStable 4379;
BA_ "SPN" SG_ 2364548606 Aft1OtltNH3GasSnsrPwrInRng 4380;
BA_ "SPN" SG_ 2364548606 Aftrtrtmnt1OtltNH3GasSnsrAtTemp 4381;
BA_ "SPN" SG_ 2364548606 Aft1OtltNH3GasSnsrHtrPrelimFMI 4382;
BA_ "SPN" SG_ 2364548606 Aftrtrtmnt1OtltNH3GasSnsrHtrCtrl 4383;
BA_ "SPN" SG_ 2364548862 Aft2DslExhstFldActlDsngQty 4384;
BA_ "SPN" SG_ 2364548862 Aftertreatment2SCRSystemState 4385;
BA_ "SPN" SG_ 2364548862 Aftertreatment2SCRSystem2State 7525;
BA_ "SPN" SG_ 2364548862 Aft2DslExhstFldActlQtyOfIntgrtr 4386;
BA_ "SPN" SG_ 2364548862 Aft2DslExhstFldDsngAbsPress 4387;
BA_ "SPN" SG_ 2364548862 Aft2DslExhstFldActlDsngQtyHiRng 6596;
BA_ "SPN" SG_ 2364549118 Aft2DslExhstFldDsngRqedQty 4401;
BA_ "SPN" SG_ 2364549118 Aftrtrtmnt2SCRSystemRqedState 4402;
BA_ "SPN" SG_ 2364549118 Aft2DslExhstFldHydrStffnssCkPmSt 7519;
BA_ "SPN" SG_ 2364549118 Aft2DslExhstFldDsngTtInjectPmSt 7520;
BA_ "SPN" SG_ 2364549118 Aft2DslExhstFldRqedQtyOfIntgrtr 4403;
BA_ "SPN" SG_ 2364549118 Aft2DslExhstFldDsngRqedQtyHiRng 6594;
BA_ "SPN" SG_ 2364549118 Aftrtrtmnt2DslExhstFldPumpHtrCmd 7087;
BA_ "SPN" SG_ 2364549374 Aftertreatment2OutletNH3 4443;
BA_ "SPN" SG_ 2364549374 Aftrtrtmnt2OtltNH3SnsrPrelimFMI 4444;
BA_ "SPN" SG_ 2364549374 Aftrtrtmnt2OtltNH3ReadingStable 4445;
BA_ "SPN" SG_ 2364549374 Aft2OtltNH3GasSnsrPwrInRng 4446;
BA_ "SPN" SG_ 2364549374 Aftrtrtmnt2OtltNH3GasSnsrAtTemp 4447;
BA_ "SPN" SG_ 2364549374 Aft2OtltNH3GasSnsrHtrPrelimFMI 4448;
BA_ "SPN" SG_ 2364549374 Aftrtrtmnt2OtltNH3GasSnsrHtrCtrl 4449;
BA_ "SPN" SG_ 2364549630 PitchAngle 4976;
BA_ "SPN" SG_ 2364549630 RollAngle 4977;
BA_ "SPN" SG_ 2364549630 PitchAngleCompensation 4978;
BA_ "SPN" SG_ 2364549630 PitchAngleFigureOfMerit 4979;
BA_ "SPN" SG_ 2364549630 RollAngleCompensation 4980;
BA_ "SPN" SG_ 2364549630 RollAngleFigureOfMerit 4981;
BA_ "SPN" SG_ 2364549630 RollAndPitchMeasurementLatency 4982;
BA_ "SPN" SG_ 2364549886 PitchRate 4983;
BA_ "SPN" SG_ 2364549886 RollRate 4984;
BA_ "SPN" SG_ 2364549886 YawRate 4985;
BA_ "SPN" SG_ 2364549886 PitchRateFigureOfMerit 4986;
BA_ "SPN" SG_ 2364549886 RollRateFigureOfMerit 4987;
BA_ "SPN" SG_ 2364549886 YawRateFigureOfMerit 4988;
BA_ "SPN" SG_ 2364549886 AngularRateMeasurementLatency 4989;
BA_ "SPN" SG_ 2163223550 CrashType 4973;
BA_ "SPN" SG_ 2163223550 CrashCounter 4974;
BA_ "SPN" SG_ 2163223550 CrashChecksum 4975;
BA_ "SPN" SG_ 2297441534 MagnetForwardCurrent 5008;
BA_ "SPN" SG_ 2297441534 MagnetReverseCurrent 5009;
BA_ "SPN" SG_ 2297441534 MaterialLiftSwitch 5010;
BA_ "SPN" SG_ 2297441534 MaterialDropSwitch 5011;
BA_ "SPN" SG_ 2297441534 GeneratorCurrentBoostActvStatus 5012;
BA_ "SPN" SG_ 2297441534 MaterialLiftActiveStatus 5013;
BA_ "SPN" SG_ 2297441534 MaterialDropActiveStatus 5014;
BA_ "SPN" SG_ 2297441534 LiftRelayControl 5402;
BA_ "SPN" SG_ 2297441534 DropRelayControl 5403;
BA_ "SPN" SG_ 2297441534 MagnetGeneratorControl 5551;
BA_ "SPN" SG_ 2297441790 LateralAcceleration 5347;
BA_ "SPN" SG_ 2297441790 LongitudinalAcceleration 5348;
BA_ "SPN" SG_ 2297441790 VerticalAcceleration 5349;
BA_ "SPN" SG_ 2297441790 LateralAccelerationFigureOfMerit 5350;
BA_ "SPN" SG_ 2297441790 LongitudinalAccltnFigureOfMerit 5351;
BA_ "SPN" SG_ 2297441790 VerticalAccltnFigureOfMerit 5352;
BA_ "SPN" SG_ 2297441790 SuppVarTrnsmRepttnRateAccltnSnsr 5353;
BA_ "SPN" SG_ 2565877502 EngTurbochargerWastegateActr1Cmd 5386;
BA_ "SPN" SG_ 2565877502 EngTurbochargerWastegateActr2Cmd 5387;
BA_ "SPN" SG_ 2565877502 EngExhstPressureRegulatorCtrlCmd 649;
BA_ "SPN" SG_ 2565877502 EngTurboCmprssorBlowoffActr1Cmd 6201;
BA_ "SPN" SG_ 2364551166 AdvEmergencyBrakingSystemState 5676;
BA_ "SPN" SG_ 2364551166 CollisionWarningLevel 5677;
BA_ "SPN" SG_ 2364551166 RelvntObjDetctAdvEmrgncyBrkngSys 5678;
BA_ "SPN" SG_ 2364551166 BendOffProbabilityOfRelevantObj 5679;
BA_ "SPN" SG_ 2364551166 TimeToCollsnWithRelevantObject 5680;
BA_ "SPN" SG_ 2364551422 WirelessRollingMessageCounter 5750;
BA_ "SPN" SG_ 2364551422 TransmitterCommandState 5751;
BA_ "SPN" SG_ 2364551422 TransmitterID1 5752;
BA_ "SPN" SG_ 2364551422 WirelessSignalStrength1 5753;
BA_ "SPN" SG_ 2230333950 WandAngle 5821;
BA_ "SPN" SG_ 2230333950 WandSensorFigureOfMerit 5822;
BA_ "SPN" SG_ 2230334206 MeasuredLinearDisplacement 5823;
BA_ "SPN" SG_ 2230334206 LnrDisplacmntSnsrSnsrFigOfMerit 5824;
BA_ "SPN" SG_ 2431661054 Aftrtrtmnt1SCRIntermediateNH3 5848;
BA_ "SPN" SG_ 2431661054 Aft1SCRIntrmedNH3SnsrPrelimFMI 5849;
BA_ "SPN" SG_ 2431661054 Aft1SCRIntrmedNH3RdngStable 5850;
BA_ "SPN" SG_ 2431661054 Aft1SCRIntrmedNH3SnsrPwrInRng 5851;
BA_ "SPN" SG_ 2431661054 Aft1SCRIntrmedNH3SnsrAtTemp 5852;
BA_ "SPN" SG_ 2431661054 Aft1SCRIntrmedNH3SnsrHtrPrlmFMI 5853;
BA_ "SPN" SG_ 2431661054 Aft1SCRIntrmedNH3SnsrHtrCtrl 5854;
BA_ "SPN" SG_ 2431661310 Aftrtrtmnt2SCRIntermediateNH3 5855;
BA_ "SPN" SG_ 2431661310 Aft2SCRIntrmedNH3SnsrPrelimFMI 5856;
BA_ "SPN" SG_ 2431661310 Aft2SCRIntrmedNH3RdngStable 5857;
BA_ "SPN" SG_ 2431661310 Aft2SCRIntrmedNH3SnsrPwrInRng 5858;
BA_ "SPN" SG_ 2431661310 Aft2SCRIntrmedNH3SnsrAtTemp 5859;
BA_ "SPN" SG_ 2431661310 Aft2SCRIntrmedNH3SnsrHtrPrlmFMI 5860;
BA_ "SPN" SG_ 2431661310 Aft2SCRIntrmedNH3SnsrHtrCtrl 5861;
BA_ "SPN" SG_ 2364552958 HVES1DisChrgPowerLmtDTStateChrg 8103;
BA_ "SPN" SG_ 2364552958 HVES1DisChrgPwrLmtDTBattryTemp 8104;
BA_ "SPN" SG_ 2364552958 HVES1DisChrgPwrLmtDTBattDiagCond 8105;
BA_ "SPN" SG_ 2364552958 HVES1DisChrgPwrLmtDTBattCellVltg 8106;
BA_ "SPN" SG_ 2364552958 HVES1DisChrgPowerLmtDTBattryCurr 8107;
BA_ "SPN" SG_ 2364552958 HVES1DisChrgPwrLmtDTUndefndCause 8108;
BA_ "SPN" SG_ 2364552958 HVES1ChrgPowerLimitDTStateChrg 8109;
BA_ "SPN" SG_ 2364552958 HVES1ChrgPwrLmtDTBattryTemp 8110;
BA_ "SPN" SG_ 2364552958 HVES1ChrgPwrLmtDTBattDiagCondtn 8111;
BA_ "SPN" SG_ 2364552958 HVES1ChrgPwrLmtDTBattryCellVltg 8112;
BA_ "SPN" SG_ 2364552958 HVES1ChrgPowerLimitDTBattryCurr 8113;
BA_ "SPN" SG_ 2364552958 HVES1ChrgPwrLmtDTUndefinedCause 8114;
BA_ "SPN" SG_ 2364553214 EngTurboCmprBlowoffActr1PrlmFMI 6311;
BA_ "SPN" SG_ 2364553214 EngTurboCmprBlowoffActr1TempStat 6312;
BA_ "SPN" SG_ 2364553214 EngTurboCmprssorBlowoffActr1Temp 6313;
BA_ "SPN" SG_ 2364553214 EngTurboCmprBlowoffActr1DsrdPos 6314;
BA_ "SPN" SG_ 2364553214 EngTurboCmprssorBlowoffActr1Pos 6315;
BA_ "SPN" SG_ 2364553214 EngTurboCmprBlowoffActr1OpStat 6316;
BA_ "SPN" SG_ 2364553470 EngGsSubstitutionFuelPrcntageCmd 6386;
BA_ "SPN" SG_ 2364553470 EngineCylinderGasMassFlowRateCmd 6387;
BA_ "SPN" SG_ 2364553470 EngineCylDieselMassFlowRateCmd 6388;
BA_ "SPN" SG_ 2364553470 EngineCylinderTorque 6389;
BA_ "SPN" SG_ 2364553470 EngineDualFuelModeCommand 6792;
BA_ "SPN" SG_ 2364553726 EngineDesiredAirFuelRatio 6392;
BA_ "SPN" SG_ 2364553726 EngineTotalIntakeMassAirFlowRate 6393;
BA_ "SPN" SG_ 2364553726 EngFuelSys2TtlIntkMassAirFlwRate 8310;
BA_ "SPN" SG_ 2364553982 EngineCylinder1HeatRelease 6396;
BA_ "SPN" SG_ 2364553982 EngineCylinder1PeakPressure 6397;
BA_ "SPN" SG_ 2364553982 EngineCyl1SynchronousKnockLevel 6398;
BA_ "SPN" SG_ 2364553982 EngCyl1PressureSensorPrelimFMI 6399;
BA_ "SPN" SG_ 2364553982 EngineCyl1LowFrequencyKnockLevel 7609;
BA_ "SPN" SG_ 2364553982 EngCyl1MaxPressureIncreaseRate 7629;
BA_ "SPN" SG_ 2364554238 EngineCylinder2HeatRelease 6400;
BA_ "SPN" SG_ 2364554238 EngineCylinder2PeakPressure 6401;
BA_ "SPN" SG_ 2364554238 EngineCyl2SynchronousKnockLevel 6402;
BA_ "SPN" SG_ 2364554238 EngCyl2PressureSensorPrelimFMI 6403;
BA_ "SPN" SG_ 2364554238 EngineCyl2LowFrequencyKnockLevel 7610;
BA_ "SPN" SG_ 2364554238 EngCyl2MaxPressureIncreaseRate 7630;
BA_ "SPN" SG_ 2364554494 EngineCylinder3HeatRelease 6404;
BA_ "SPN" SG_ 2364554494 EngineCylinder3PeakPressure 6405;
BA_ "SPN" SG_ 2364554494 EngineCyl3SynchronousKnockLevel 6406;
BA_ "SPN" SG_ 2364554494 EngCyl3PressureSensorPrelimFMI 6407;
BA_ "SPN" SG_ 2364554494 EngineCyl3LowFrequencyKnockLevel 7611;
BA_ "SPN" SG_ 2364554494 EngCyl3MaxPressureIncreaseRate 7631;
BA_ "SPN" SG_ 2364554750 EngineCylinder4HeatRelease 6408;
BA_ "SPN" SG_ 2364554750 EngineCylinder4PeakPressure 6409;
BA_ "SPN" SG_ 2364554750 EngineCyl4SynchronousKnockLevel 6410;
BA_ "SPN" SG_ 2364554750 EngCyl4PressureSensorPrelimFMI 6411;
BA_ "SPN" SG_ 2364554750 EngineCyl4LowFrequencyKnockLevel 7612;
BA_ "SPN" SG_ 2364554750 EngCyl4MaxPressureIncreaseRate 7632;
BA_ "SPN" SG_ 2364555006 EngineCylinder5HeatRelease 6412;
BA_ "SPN" SG_ 2364555006 EngineCylinder5PeakPressure 6413;
BA_ "SPN" SG_ 2364555006 EngineCyl5SynchronousKnockLevel 6414;
BA_ "SPN" SG_ 2364555006 EngCyl5PressureSensorPrelimFMI 6415;
BA_ "SPN" SG_ 2364555006 EngineCyl5LowFrequencyKnockLevel 7613;
BA_ "SPN" SG_ 2364555006 EngCyl5MaxPressureIncreaseRate 7633;
BA_ "SPN" SG_ 2364555262 EngineCylinder6HeatRelease 6416;
BA_ "SPN" SG_ 2364555262 EngineCylinder6PeakPressure 6417;
BA_ "SPN" SG_ 2364555262 EngineCyl6SynchronousKnockLevel 6418;
BA_ "SPN" SG_ 2364555262 EngCyl6PressureSensorPrelimFMI 6419;
BA_ "SPN" SG_ 2364555262 EngineCyl6LowFrequencyKnockLevel 7614;
BA_ "SPN" SG_ 2364555262 EngCyl6MaxPressureIncreaseRate 7634;
BA_ "SPN" SG_ 2364555518 EngineCylinder7HeatRelease 6420;
BA_ "SPN" SG_ 2364555518 EngineCylinder7PeakPressure 6421;
BA_ "SPN" SG_ 2364555518 EngineCyl7SynchronousKnockLevel 6422;
BA_ "SPN" SG_ 2364555518 EngCyl7PressureSensorPrelimFMI 6423;
BA_ "SPN" SG_ 2364555518 EngineCyl7LowFrequencyKnockLevel 7615;
BA_ "SPN" SG_ 2364555518 EngCyl7MaxPressureIncreaseRate 7635;
BA_ "SPN" SG_ 2364555774 EngineCylinder8HeatRelease 6424;
BA_ "SPN" SG_ 2364555774 EngineCylinder8PeakPressure 6425;
BA_ "SPN" SG_ 2364555774 EngineCyl8SynchronousKnockLevel 6426;
BA_ "SPN" SG_ 2364555774 EngCyl8PressureSensorPrelimFMI 6427;
BA_ "SPN" SG_ 2364555774 EngineCyl8LowFrequencyKnockLevel 7616;
BA_ "SPN" SG_ 2364555774 EngCyl8MaxPressureIncreaseRate 7636;
BA_ "SPN" SG_ 2364556030 EngineCylinder9HeatRelease 6428;
BA_ "SPN" SG_ 2364556030 EngineCylinder9PeakPressure 6429;
BA_ "SPN" SG_ 2364556030 EngineCyl9SynchronousKnockLevel 6430;
BA_ "SPN" SG_ 2364556030 EngCyl9PressureSensorPrelimFMI 6431;
BA_ "SPN" SG_ 2364556030 EngineCyl9LowFrequencyKnockLevel 7617;
BA_ "SPN" SG_ 2364556030 EngCyl9MaxPressureIncreaseRate 7637;
BA_ "SPN" SG_ 2364556286 EngineCylinder10HeatRelease 6432;
BA_ "SPN" SG_ 2364556286 EngineCylinder10PeakPressure 6433;
BA_ "SPN" SG_ 2364556286 EngineCyl10SynchronousKnockLevel 6434;
BA_ "SPN" SG_ 2364556286 EngCyl10PressureSensorPrelimFMI 6435;
BA_ "SPN" SG_ 2364556286 EngCyl10LowFrequencyKnockLevel 7618;
BA_ "SPN" SG_ 2364556286 EngCyl10MaxPressureIncreaseRate 7638;
BA_ "SPN" SG_ 2364556542 EngineCylinder11HeatRelease 6436;
BA_ "SPN" SG_ 2364556542 EngineCylinder11PeakPressure 6437;
BA_ "SPN" SG_ 2364556542 EngineCyl11SynchronousKnockLevel 6438;
BA_ "SPN" SG_ 2364556542 EngCyl11PressureSensorPrelimFMI 6439;
BA_ "SPN" SG_ 2364556542 EngCyl11LowFrequencyKnockLevel 7619;
BA_ "SPN" SG_ 2364556542 EngCyl11MaxPressureIncreaseRate 7639;
BA_ "SPN" SG_ 2364556798 EngineCylinder12HeatRelease 6440;
BA_ "SPN" SG_ 2364556798 EngineCylinder12PeakPressure 6441;
BA_ "SPN" SG_ 2364556798 EngineCyl12SynchronousKnockLevel 6442;
BA_ "SPN" SG_ 2364556798 EngCyl12PressureSensorPrelimFMI 6443;
BA_ "SPN" SG_ 2364556798 EngCyl12LowFrequencyKnockLevel 7620;
BA_ "SPN" SG_ 2364556798 EngCyl12MaxPressureIncreaseRate 7640;
BA_ "SPN" SG_ 2364557054 EngineCylinder13HeatRelease 6444;
BA_ "SPN" SG_ 2364557054 EngineCylinder13PeakPressure 6445;
BA_ "SPN" SG_ 2364557054 EngineCyl13SynchronousKnockLevel 6446;
BA_ "SPN" SG_ 2364557054 EngCyl13PressureSensorPrelimFMI 6447;
BA_ "SPN" SG_ 2364557054 EngCyl13LowFrequencyKnockLevel 7621;
BA_ "SPN" SG_ 2364557054 EngCyl13MaxPressureIncreaseRate 7641;
BA_ "SPN" SG_ 2364557310 EngineCylinder14HeatRelease 6448;
BA_ "SPN" SG_ 2364557310 EngineCylinder14PeakPressure 6449;
BA_ "SPN" SG_ 2364557310 EngineCyl14SynchronousKnockLevel 6450;
BA_ "SPN" SG_ 2364557310 EngCyl14PressureSensorPrelimFMI 6451;
BA_ "SPN" SG_ 2364557310 EngCyl14LowFrequencyKnockLevel 7622;
BA_ "SPN" SG_ 2364557310 EngCyl14MaxPressureIncreaseRate 7642;
BA_ "SPN" SG_ 2364557566 EngineCylinder15HeatRelease 6452;
BA_ "SPN" SG_ 2364557566 EngineCylinder15PeakPressure 6453;
BA_ "SPN" SG_ 2364557566 EngineCyl15SynchronousKnockLevel 6454;
BA_ "SPN" SG_ 2364557566 EngCyl15PressureSensorPrelimFMI 6455;
BA_ "SPN" SG_ 2364557566 EngCyl15LowFrequencyKnockLevel 7623;
BA_ "SPN" SG_ 2364557566 EngCyl15MaxPressureIncreaseRate 7643;
BA_ "SPN" SG_ 2364557822 EngineCylinder16HeatRelease 6456;
BA_ "SPN" SG_ 2364557822 EngineCylinder16PeakPressure 6457;
BA_ "SPN" SG_ 2364557822 EngineCyl16SynchronousKnockLevel 6458;
BA_ "SPN" SG_ 2364557822 EngCyl16PressureSensorPrelimFMI 6459;
BA_ "SPN" SG_ 2364557822 EngCyl16LowFrequencyKnockLevel 7624;
BA_ "SPN" SG_ 2364557822 EngCyl16MaxPressureIncreaseRate 7644;
BA_ "SPN" SG_ 2364558078 EngineCylinder17HeatRelease 6460;
BA_ "SPN" SG_ 2364558078 EngineCylinder17PeakPressure 6461;
BA_ "SPN" SG_ 2364558078 EngineCyl17SynchronousKnockLevel 6462;
BA_ "SPN" SG_ 2364558078 EngCyl17PressureSensorPrelimFMI 6463;
BA_ "SPN" SG_ 2364558078 EngCyl17LowFrequencyKnockLevel 7625;
BA_ "SPN" SG_ 2364558078 EngCyl17MaxPressureIncreaseRate 7645;
BA_ "SPN" SG_ 2364558334 EngineCylinder18HeatRelease 6464;
BA_ "SPN" SG_ 2364558334 EngineCylinder18PeakPressure 6465;
BA_ "SPN" SG_ 2364558334 EngineCyl18SynchronousKnockLevel 6466;
BA_ "SPN" SG_ 2364558334 EngCyl18PressureSensorPrelimFMI 6467;
BA_ "SPN" SG_ 2364558334 EngCyl18LowFrequencyKnockLevel 7626;
BA_ "SPN" SG_ 2364558334 EngCyl18MaxPressureIncreaseRate 7646;
BA_ "SPN" SG_ 2364558590 EngineCylinder19HeatRelease 6468;
BA_ "SPN" SG_ 2364558590 EngineCylinder19PeakPressure 6469;
BA_ "SPN" SG_ 2364558590 EngineCyl19SynchronousKnockLevel 6470;
BA_ "SPN" SG_ 2364558590 EngCyl19PressureSensorPrelimFMI 6471;
BA_ "SPN" SG_ 2364558590 EngCyl19LowFrequencyKnockLevel 7627;
BA_ "SPN" SG_ 2364558590 EngCyl19MaxPressureIncreaseRate 7647;
BA_ "SPN" SG_ 2364558846 EngineCylinder20HeatRelease 6472;
BA_ "SPN" SG_ 2364558846 EngineCylinder20PeakPressure 6473;
BA_ "SPN" SG_ 2364558846 EngineCyl20SynchronousKnockLevel 6474;
BA_ "SPN" SG_ 2364558846 EngCyl20PressureSensorPrelimFMI 6475;
BA_ "SPN" SG_ 2364558846 EngCyl20LowFrequencyKnockLevel 7628;
BA_ "SPN" SG_ 2364558846 EngCyl20MaxPressureIncreaseRate 7648;
BA_ "SPN" SG_ 2498776830 EngCyl1IndicatedMeanEffectivePrs 6483;
BA_ "SPN" SG_ 2498776830 EngCyl1AvrgStartCombustionTiming 6484;
BA_ "SPN" SG_ 2498776830 EngCyl1AvrgCntrCombustionTiming 6485;
BA_ "SPN" SG_ 2498776830 EngineCyl1AvrgCombustionDuration 6486;
BA_ "SPN" SG_ 2498777086 EngCyl2IndicatedMeanEffectivePrs 6487;
BA_ "SPN" SG_ 2498777086 EngCyl2AvrgStartCombustionTiming 6488;
BA_ "SPN" SG_ 2498777086 EngCyl2AvrgCntrCombustionTiming 6489;
BA_ "SPN" SG_ 2498777086 EngineCyl2AvrgCombustionDuration 6490;
BA_ "SPN" SG_ 2498777342 EngCyl3IndicatedMeanEffectivePrs 6491;
BA_ "SPN" SG_ 2498777342 EngCyl3AvrgStartCombustionTiming 6492;
BA_ "SPN" SG_ 2498777342 EngCyl3AvrgCntrCombustionTiming 6493;
BA_ "SPN" SG_ 2498777342 EngineCyl3AvrgCombustionDuration 6494;
BA_ "SPN" SG_ 2498777598 EngCyl4IndicatedMeanEffectivePrs 6495;
BA_ "SPN" SG_ 2498777598 EngCyl4AvrgStartCombustionTiming 6496;
BA_ "SPN" SG_ 2498777598 EngCyl4AvrgCntrCombustionTiming 6497;
BA_ "SPN" SG_ 2498777598 EngineCyl4AvrgCombustionDuration 6498;
BA_ "SPN" SG_ 2498777854 EngCyl5IndicatedMeanEffectivePrs 6499;
BA_ "SPN" SG_ 2498777854 EngCyl5AvrgStartCombustionTiming 6500;
BA_ "SPN" SG_ 2498777854 EngCyl5AvrgCntrCombustionTiming 6501;
BA_ "SPN" SG_ 2498777854 EngineCyl5AvrgCombustionDuration 6502;
BA_ "SPN" SG_ 2498778110 EngCyl6IndicatedMeanEffectivePrs 6503;
BA_ "SPN" SG_ 2498778110 EngCyl6AvrgStartCombustionTiming 6504;
BA_ "SPN" SG_ 2498778110 EngCyl6AvrgCntrCombustionTiming 6505;
BA_ "SPN" SG_ 2498778110 EngineCyl6AvrgCombustionDuration 6506;
BA_ "SPN" SG_ 2498778366 EngCyl7IndicatedMeanEffectivePrs 6507;
BA_ "SPN" SG_ 2498778366 EngCyl7AvrgStartCombustionTiming 6508;
BA_ "SPN" SG_ 2498778366 EngCyl7AvrgCntrCombustionTiming 6509;
BA_ "SPN" SG_ 2498778366 EngineCyl7AvrgCombustionDuration 6510;
BA_ "SPN" SG_ 2498778622 EngCyl8IndicatedMeanEffectivePrs 6511;
BA_ "SPN" SG_ 2498778622 EngCyl8AvrgStartCombustionTiming 6512;
BA_ "SPN" SG_ 2498778622 EngCyl8AvrgCntrCombustionTiming 6513;
BA_ "SPN" SG_ 2498778622 EngineCyl8AvrgCombustionDuration 6514;
BA_ "SPN" SG_ 2498778878 EngCyl9IndicatedMeanEffectivePrs 6515;
BA_ "SPN" SG_ 2498778878 EngCyl9AvrgStartCombustionTiming 6516;
BA_ "SPN" SG_ 2498778878 EngCyl9AvrgCntrCombustionTiming 6517;
BA_ "SPN" SG_ 2498778878 EngineCyl9AvrgCombustionDuration 6518;
BA_ "SPN" SG_ 2498779134 EngCyl10IndicatedMeanEffectPrs 6519;
BA_ "SPN" SG_ 2498779134 EngCyl10AvrgStrtOfCombustionTmng 6520;
BA_ "SPN" SG_ 2498779134 EngCyl10AvrgCntrOfCombustionTmng 6521;
BA_ "SPN" SG_ 2498779134 EngCyl10AvrgCombustionDuration 6522;
BA_ "SPN" SG_ 2498779390 EngCyl11IndicatedMeanEffectPrs 6523;
BA_ "SPN" SG_ 2498779390 EngCyl11AvrgStrtOfCombustionTmng 6524;
BA_ "SPN" SG_ 2498779390 EngCyl11AvrgCntrOfCombustionTmng 6525;
BA_ "SPN" SG_ 2498779390 EngCyl11AvrgCombustionDuration 6526;
BA_ "SPN" SG_ 2498779646 EngCyl12IndicatedMeanEffectPrs 6527;
BA_ "SPN" SG_ 2498779646 EngCyl12AvrgStrtOfCombustionTmng 6528;
BA_ "SPN" SG_ 2498779646 EngCyl12AvrgCntrOfCombustionTmng 6529;
BA_ "SPN" SG_ 2498779646 EngCyl12AvrgCombustionDuration 6530;
BA_ "SPN" SG_ 2498779902 EngCyl13IndicatedMeanEffectPrs 6531;
BA_ "SPN" SG_ 2498779902 EngCyl13AvrgStrtOfCombustionTmng 6532;
BA_ "SPN" SG_ 2498779902 EngCyl13AvrgCntrOfCombustionTmng 6533;
BA_ "SPN" SG_ 2498779902 EngCyl13AvrgCombustionDuration 6534;
BA_ "SPN" SG_ 2498780158 EngCyl14IndicatedMeanEffectPrs 6535;
BA_ "SPN" SG_ 2498780158 EngCyl14AvrgStrtOfCombustionTmng 6536;
BA_ "SPN" SG_ 2498780158 EngCyl14AvrgCntrOfCombustionTmng 6537;
BA_ "SPN" SG_ 2498780158 EngCyl14AvrgCombustionDuration 6538;
BA_ "SPN" SG_ 2498780414 EngCyl15IndicatedMeanEffectPrs 6539;
BA_ "SPN" SG_ 2498780414 EngCyl15AvrgStrtOfCombustionTmng 6540;
BA_ "SPN" SG_ 2498780414 EngCyl15AvrgCntrOfCombustionTmng 6541;
BA_ "SPN" SG_ 2498780414 EngCyl15AvrgCombustionDuration 6542;
BA_ "SPN" SG_ 2498780670 EngCyl16IndicatedMeanEffectPrs 6543;
BA_ "SPN" SG_ 2498780670 EngCyl16AvrgStrtOfCombustionTmng 6544;
BA_ "SPN" SG_ 2498780670 EngCyl16AvrgCntrOfCombustionTmng 6545;
BA_ "SPN" SG_ 2498780670 EngCyl16AvrgCombustionDuration 6546;
BA_ "SPN" SG_ 2498780926 EngCyl17IndicatedMeanEffectPrs 6547;
BA_ "SPN" SG_ 2498780926 EngCyl17AvrgStrtOfCombustionTmng 6548;
BA_ "SPN" SG_ 2498780926 EngCyl17AvrgCntrOfCombustionTmng 6549;
BA_ "SPN" SG_ 2498780926 EngCyl17AvrgCombustionDuration 6550;
BA_ "SPN" SG_ 2498781182 EngCyl18IndicatedMeanEffectPrs 6551;
BA_ "SPN" SG_ 2498781182 EngCyl18AvrgStrtOfCombustionTmng 6552;
BA_ "SPN" SG_ 2498781182 EngCyl18AvrgCntrOfCombustionTmng 6553;
BA_ "SPN" SG_ 2498781182 EngCyl18AvrgCombustionDuration 6554;
BA_ "SPN" SG_ 2498781438 EngCyl19IndicatedMeanEffectPrs 6555;
BA_ "SPN" SG_ 2498781438 EngCyl19AvrgStrtOfCombustionTmng 6556;
BA_ "SPN" SG_ 2498781438 EngCyl19AvrgCntrOfCombustionTmng 6557;
BA_ "SPN" SG_ 2498781438 EngCyl19AvrgCombustionDuration 6558;
BA_ "SPN" SG_ 2498781694 EngCyl20IndicatedMeanEffectPrs 6559;
BA_ "SPN" SG_ 2498781694 EngCyl20AvrgStrtOfCombustionTmng 6560;
BA_ "SPN" SG_ 2498781694 EngCyl20AvrgCntrOfCombustionTmng 6561;
BA_ "SPN" SG_ 2498781694 EngCyl20AvrgCombustionDuration 6562;
BA_ "SPN" SG_ 2297455358 TransmissionHydrostaticLp1Press 6583;
BA_ "SPN" SG_ 2297455358 TransmissionHydrostaticLp2Press 6584;
BA_ "SPN" SG_ 2297455358 TrnsmDirectionalOutptShftSpd 6585;
BA_ "SPN" SG_ 2297455358 TransmissionIntrmedShaftSpeed 160;
BA_ "SPN" SG_ 2364564478 EngGseousFuelVlvNomDurationCmd 6656;
BA_ "SPN" SG_ 2364564478 EngGseousFuelVlvNomStrtOfActCmd 6657;
BA_ "SPN" SG_ 2364564734 EngGaseousFuelValve1DurationCmd 6658;
BA_ "SPN" SG_ 2364564734 EngGaseousFuelValve2DurationCmd 6659;
BA_ "SPN" SG_ 2364564734 EngGaseousFuelValve3DurationCmd 6660;
BA_ "SPN" SG_ 2364564734 EngGaseousFuelValve4DurationCmd 6661;
BA_ "SPN" SG_ 2364564990 EngGaseousFuelValve5DurationCmd 6662;
BA_ "SPN" SG_ 2364564990 EngGaseousFuelValve6DurationCmd 6663;
BA_ "SPN" SG_ 2364564990 EngGaseousFuelValve7DurationCmd 6664;
BA_ "SPN" SG_ 2364564990 EngGaseousFuelValve8DurationCmd 6665;
BA_ "SPN" SG_ 2364565246 EngGaseousFuelValve9DurationCmd 6666;
BA_ "SPN" SG_ 2364565246 EngGaseousFuelValve10DurationCmd 6667;
BA_ "SPN" SG_ 2364565246 EngGaseousFuelValve11DurationCmd 6668;
BA_ "SPN" SG_ 2364565246 EngGaseousFuelValve12DurationCmd 6669;
BA_ "SPN" SG_ 2364565502 EngGaseousFuelValve13DurationCmd 6670;
BA_ "SPN" SG_ 2364565502 EngGaseousFuelValve14DurationCmd 6671;
BA_ "SPN" SG_ 2364565502 EngGaseousFuelValve15DurationCmd 6672;
BA_ "SPN" SG_ 2364565502 EngGaseousFuelValve16DurationCmd 6673;
BA_ "SPN" SG_ 2364565758 EngGaseousFuelValve17DurationCmd 6674;
BA_ "SPN" SG_ 2364565758 EngGaseousFuelValve18DurationCmd 6675;
BA_ "SPN" SG_ 2364565758 EngGaseousFuelValve19DurationCmd 6676;
BA_ "SPN" SG_ 2364565758 EngGaseousFuelValve20DurationCmd 6677;
BA_ "SPN" SG_ 2364566014 EngGaseousFuelVlv1StartOfActCmd 6678;
BA_ "SPN" SG_ 2364566014 EngGaseousFuelVlv2StartOfActCmd 6679;
BA_ "SPN" SG_ 2364566014 EngGaseousFuelVlv3StartOfActCmd 6680;
BA_ "SPN" SG_ 2364566014 EngGaseousFuelVlv4StartOfActCmd 6681;
BA_ "SPN" SG_ 2364566270 EngGaseousFuelVlv5StartOfActCmd 6682;
BA_ "SPN" SG_ 2364566270 EngGaseousFuelVlv6StartOfActCmd 6683;
BA_ "SPN" SG_ 2364566270 EngGaseousFuelVlv7StartOfActCmd 6684;
BA_ "SPN" SG_ 2364566270 EngGaseousFuelVlv8StartOfActCmd 6685;
BA_ "SPN" SG_ 2364566526 EngGaseousFuelVlv9StartOfActCmd 6686;
BA_ "SPN" SG_ 2364566526 EngGaseousFuelVlv10StartOfActCmd 6687;
BA_ "SPN" SG_ 2364566526 EngGaseousFuelVlv11StartOfActCmd 6688;
BA_ "SPN" SG_ 2364566526 EngGaseousFuelVlv12StartOfActCmd 6689;
BA_ "SPN" SG_ 2364566782 EngGaseousFuelVlv13StartOfActCmd 6690;
BA_ "SPN" SG_ 2364566782 EngGaseousFuelVlv14StartOfActCmd 6691;
BA_ "SPN" SG_ 2364566782 EngGaseousFuelVlv15StartOfActCmd 6692;
BA_ "SPN" SG_ 2364566782 EngGaseousFuelVlv16StartOfActCmd 6693;
BA_ "SPN" SG_ 2364567038 EngGaseousFuelVlv17StartOfActCmd 6694;
BA_ "SPN" SG_ 2364567038 EngGaseousFuelVlv18StartOfActCmd 6695;
BA_ "SPN" SG_ 2364567038 EngGaseousFuelVlv19StartOfActCmd 6696;
BA_ "SPN" SG_ 2364567038 EngGaseousFuelVlv20StartOfActCmd 6697;
BA_ "SPN" SG_ 2364567294 EngFuelInjectPmp1FuelCtrlVlvCmd 6719;
BA_ "SPN" SG_ 2364567294 EngFuelInjectPmp2FuelCtrlVlvCmd 6720;
BA_ "SPN" SG_ 2364575998 HVES1AvailableDischargePower 5917;
BA_ "SPN" SG_ 2364575998 HVES1AvailableChargePower 5918;
BA_ "SPN" SG_ 2364575998 HVES1VoltageLevel 5919;
BA_ "SPN" SG_ 2364575998 HVES1Current 5920;
BA_ "SPN" SG_ 2364576254 HVES1FastUpdateStateOfCharge 5921;
BA_ "SPN" SG_ 2364576254 HVES1HighestCellVoltage 5922;
BA_ "SPN" SG_ 2364576254 HVES1LowestCellVoltage 5923;
BA_ "SPN" SG_ 2364576254 HVES1CellVoltageDiffStatus 5924;
BA_ "SPN" SG_ 2364576510 HVES1HighestCellTemperature 8075;
BA_ "SPN" SG_ 2364576510 HVES1LowestCellTemperature 8076;
BA_ "SPN" SG_ 2364576510 HVES1AverageCellTemperature 8077;
BA_ "SPN" SG_ 2364576510 HVES1CellTemperatureDiffStatus 8078;
BA_ "SPN" SG_ 2364576766 HVES1DischargeCapacity 8079;
BA_ "SPN" SG_ 2364576766 HVES1ChargeCapacity 8080;
BA_ "SPN" SG_ 2364576766 HVES1CellBalancingCount 8081;
BA_ "SPN" SG_ 2364577022 HVES1DischargeCurrentLimit 8082;
BA_ "SPN" SG_ 2364577022 HVES1ChargeCurrentLimit 8083;
BA_ "SPN" SG_ 2364577022 HVES1MinimumCellStateOfCharge 8084;
BA_ "SPN" SG_ 2364577022 HVES1MaximumCellStateOfCharge 8085;
BA_ "SPN" SG_ 2364577278 HVES1BusVoltage 8086;
BA_ "SPN" SG_ 2364577278 HVES1IgnitionVoltage 8087;
BA_ "SPN" SG_ 2364577278 HVES1InletCoolantTemperature 8088;
BA_ "SPN" SG_ 2364577278 HVES1OutletCoolantTemperature 8089;
BA_ "SPN" SG_ 2364577278 HVES1ElectronicsTemperature 8204;
BA_ "SPN" SG_ 2364577534 HVES1HghVoltageBusPosContactStat 8091;
BA_ "SPN" SG_ 2364577534 HVES1HghVoltageBusNegContactStat 8092;
BA_ "SPN" SG_ 2364577534 HVES1HghVoltageBusDiscnnctFrwrng 8093;
BA_ "SPN" SG_ 2364577534 HVES1HghVltgBusPreChrgRelyStat 8094;
BA_ "SPN" SG_ 2364577534 HVES1CenterOfPackContactorState 8095;
BA_ "SPN" SG_ 2364577534 HVES1HiVltgBusActIsolatnTestStat 8096;
BA_ "SPN" SG_ 2364577534 HVES1HiVltgBusPassIsolatnTestSt 8097;
BA_ "SPN" SG_ 2364577534 HVES1HVILStatus 8098;
BA_ "SPN" SG_ 2364577534 HVES1InertiaSwitchStatus 8099;
BA_ "SPN" SG_ 2364577534 HVES1StateOfChargeStatus 8100;
BA_ "SPN" SG_ 2364577534 HVES1CellBalanceStatus 8101;
BA_ "SPN" SG_ 2364577534 HVES1CellBalancingActive 8102;
BA_ "SPN" SG_ 2364577534 HVES1InternalChargerStatus 8207;
BA_ "SPN" SG_ 2364577534 HVES1HghVoltageBusConnectnStatus 8413;
BA_ "SPN" SG_ 2364577534 HVES1OperationalStatus 8414;
BA_ "SPN" SG_ 2364580094 HVES1DischargeEnergyCapacity 8205;
BA_ "SPN" SG_ 2364580094 HVES1ChargeEnergyCapacity 8206;
BA_ "SPN" SG_ 2364580094 HVES1MaximumChargeVoltageLimit 8090;
BA_ "SPN" SG_ 2364592382 NoEngCylsToExcludeFrmCombustion 6991;
BA_ "SPN" SG_ 2364592382 EngCyl1ExcludeFrmCombustionRq 6992;
BA_ "SPN" SG_ 2364592382 EngCyl2ExcludeFrmCombustionRq 6993;
BA_ "SPN" SG_ 2364592382 EngCyl3ExcludeFrmCombustionRq 6994;
BA_ "SPN" SG_ 2364592382 EngCyl4ExcludeFrmCombustionRq 6995;
BA_ "SPN" SG_ 2364592382 EngCyl5ExcludeFrmCombustionRq 6996;
BA_ "SPN" SG_ 2364592382 EngCyl6ExcludeFrmCombustionRq 6997;
BA_ "SPN" SG_ 2364592382 EngCyl7ExcludeFrmCombustionRq 6998;
BA_ "SPN" SG_ 2364592382 EngCyl8ExcludeFrmCombustionRq 6999;
BA_ "SPN" SG_ 2364592382 EngCyl9ExcludeFrmCombustionRq 7000;
BA_ "SPN" SG_ 2364592382 EngCyl10ExcludeFrmCombustionRq 7001;
BA_ "SPN" SG_ 2364592382 EngCyl11ExcludeFrmCombustionRq 7002;
BA_ "SPN" SG_ 2364592382 EngCyl12ExcludeFrmCombustionRq 7003;
BA_ "SPN" SG_ 2364592382 EngCyl13ExcludeFrmCombustionRq 7004;
BA_ "SPN" SG_ 2364592382 EngCyl14ExcludeFrmCombustionRq 7005;
BA_ "SPN" SG_ 2364592382 EngCyl15ExcludeFrmCombustionRq 7006;
BA_ "SPN" SG_ 2364592382 EngCyl16ExcludeFrmCombustionRq 7007;
BA_ "SPN" SG_ 2364592382 EngCyl17ExcludeFrmCombustionRq 7008;
BA_ "SPN" SG_ 2364592382 EngCyl18ExcludeFrmCombustionRq 7009;
BA_ "SPN" SG_ 2364592382 EngCyl19ExcludeFrmCombustionRq 7010;
BA_ "SPN" SG_ 2364592382 EngCyl20ExcludeFrmCombustionRq 7011;
BA_ "SPN" SG_ 2364592382 EngCyl21ExcludeFrmCombustionRq 7012;
BA_ "SPN" SG_ 2364592382 EngCyl22ExcludeFrmCombustionRq 7013;
BA_ "SPN" SG_ 2364592382 EngCyl23ExcludeFrmCombustionRq 7014;
BA_ "SPN" SG_ 2364592382 EngCyl24ExcludeFrmCombustionRq 7015;
BA_ "SPN" SG_ 2364592638 EngCylHeadBypssActr1PrelimFMI 7088;
BA_ "SPN" SG_ 2364592638 EngCylHeadBypssActr1TempStat 7089;
BA_ "SPN" SG_ 2364592638 EngCylHeadBypssActr1Temperature 7090;
BA_ "SPN" SG_ 2364592638 EngCylHeadBypssActr1DsrdPosition 7091;
BA_ "SPN" SG_ 2364592638 EngineCylHeadBypssActr1Position 7092;
BA_ "SPN" SG_ 2364592638 EngCylHeadBypssActr1OpStatus 7093;
BA_ "SPN" SG_ 2364592894 EngineCylinderHeadBypssActr1Cmd 7094;
BA_ "SPN" SG_ 2364592894 EngineIntakeAirSourceValve 6330;
BA_ "SPN" SG_ 2364592894 EngExhstGsRestrictionValvePos 8151;
BA_ "SPN" SG_ 2364593150 PredictiveCrsCtrlSetSpeedOffset 7316;
BA_ "SPN" SG_ 2364593150 PredictiveCruiseControlState 7317;
BA_ "SPN" SG_ 2364593150 VehicleSpeedCtrlOverrideRequest 7429;
BA_ "SPN" SG_ 2364593150 PredictiveCruiseCtrlEventInRange 7431;
BA_ "SPN" SG_ 2364593150 PredictiveCruiseCtrlPresentGrade 7432;
BA_ "SPN" SG_ 2364593150 PredictiveCruiseControlNextGrade 7433;
BA_ "SPN" SG_ 2364593150 PredictCrsCtrlSpeedEvntIndictr 7434;
BA_ "SPN" SG_ 2364593150 VehicleSpdCtrlOverrdEvntIndictr 7435;
BA_ "SPN" SG_ 2364593150 PredictCrsCtrlDrvlineDisengInhRq 7430;
BA_ "SPN" SG_ 2565920510 API1Output1DevMaximumFrequency 8328;
BA_ "SPN" SG_ 2565920510 API1Output1DevMinimumFrequency 8329;
BA_ "SPN" SG_ 2565920510 API1Output1DeviceRatedFrequency 8330;
BA_ "SPN" SG_ 2565920510 API1Output1DeviceRatedVoltage 8331;
BA_ "SPN" SG_ 2565920510 API1Output1DevFreqRateChangeLmt 8332;
BA_ "SPN" SG_ 2565920510 API1Output1FrequencyCommand 8333;
BA_ "SPN" SG_ 2565920510 API1Output1Device1Status 8334;
BA_ "SPN" SG_ 2565920510 API1Output1Device2Status 8335;
BA_ "SPN" SG_ 2565920510 API1Output1EnableCommand 8336;
BA_ "SPN" SG_ 2565920766 API1Output1FrequencyFeedback 8337;
BA_ "SPN" SG_ 2565920766 API1Output1VoltageFeedback 8338;
BA_ "SPN" SG_ 2565920766 API1Output1PowerFeedback 8339;
BA_ "SPN" SG_ 2565920766 API1Output1StatusFeedback 8340;
BA_ "SPN" SG_ 2565920766 API1Output1LoadshedRequest 8341;
BA_ "SPN" SG_ 2565920766 API1Output1HVILStatus 8851;
BA_ "SPN" SG_ 2565921534 API1Output2DevMaximumFrequency 8342;
BA_ "SPN" SG_ 2565921534 API1Output2DevMinimumFrequency 8343;
BA_ "SPN" SG_ 2565921534 API1Output2DeviceRatedFrequency 8344;
BA_ "SPN" SG_ 2565921534 API1Output2DeviceRatedVoltage 8345;
BA_ "SPN" SG_ 2565921534 API1Output2DevFreqRateChangeLmt 8346;
BA_ "SPN" SG_ 2565921534 API1Output2FrequencyCommand 8347;
BA_ "SPN" SG_ 2565921534 API1Output2Device1Status 8348;
BA_ "SPN" SG_ 2565921534 API1Output2Device2Status 8349;
BA_ "SPN" SG_ 2565921534 API1Output2EnableCommand 8350;
BA_ "SPN" SG_ 2565921790 API1Output2FrequencyFeedback 8351;
BA_ "SPN" SG_ 2565921790 API1Output2VoltageFeedback 8352;
BA_ "SPN" SG_ 2565921790 API1Output2PowerFeedback 8353;
BA_ "SPN" SG_ 2565921790 API1Output2StatusFeedback 8354;
BA_ "SPN" SG_ 2565921790 API1Output2LoadshedRequest 8355;
BA_ "SPN" SG_ 2565921790 API1Output2HVILStatus 8852;
BA_ "SPN" SG_ 2565922558 API1Output3DevMaximumFrequency 8356;
BA_ "SPN" SG_ 2565922558 API1Output3DevMinimumFrequency 8357;
BA_ "SPN" SG_ 2565922558 API1Output3DeviceRatedFrequency 8358;
BA_ "SPN" SG_ 2565922558 API1Output3DeviceRatedVoltage 8359;
BA_ "SPN" SG_ 2565922558 API1Output3DevFreqRateChangeLmt 8360;
BA_ "SPN" SG_ 2565922558 API1Output3FrequencyCommand 8361;
BA_ "SPN" SG_ 2565922558 API1Output3Device1Status 8362;
BA_ "SPN" SG_ 2565922558 API1Output3Device2Status 8363;
BA_ "SPN" SG_ 2565922558 API1Output3EnableCommand 8364;
BA_ "SPN" SG_ 2565922814 API1Output3FrequencyFeedback 8365;
BA_ "SPN" SG_ 2565922814 API1Output3VoltageFeedback 8366;
BA_ "SPN" SG_ 2565922814 API1Output3PowerFeedback 8367;
BA_ "SPN" SG_ 2565922814 API1Output3StatusFeedback 8368;
BA_ "SPN" SG_ 2565922814 API1Output3LoadshedRequest 8369;
BA_ "SPN" SG_ 2565922814 API1Output3HVILStatus 8853;
BA_ "SPN" SG_ 2565923582 API1Output4DevMaximumFrequency 8370;
BA_ "SPN" SG_ 2565923582 API1Output4DevMinimumFrequency 8371;
BA_ "SPN" SG_ 2565923582 API1Output4DeviceRatedFrequency 8372;
BA_ "SPN" SG_ 2565923582 API1Output4DeviceRatedVoltage 8373;
BA_ "SPN" SG_ 2565923582 API1Output4DevFreqRateChangeLmt 8374;
BA_ "SPN" SG_ 2565923582 API1Output4FrequencyCommand 8375;
BA_ "SPN" SG_ 2565923582 API1Output4Device1Status 8376;
BA_ "SPN" SG_ 2565923582 API1Output4Device2Status 8377;
BA_ "SPN" SG_ 2565923582 API1Output4EnableCommand 8378;
BA_ "SPN" SG_ 2565923838 API1Output4FrequencyFeedback 8379;
BA_ "SPN" SG_ 2565923838 API1Output4VoltageFeedback 8380;
BA_ "SPN" SG_ 2565923838 API1Output4PowerFeedback 8381;
BA_ "SPN" SG_ 2565923838 API1Output4StatusFeedback 8382;
BA_ "SPN" SG_ 2565923838 API1Output4LoadshedRequest 8383;
BA_ "SPN" SG_ 2565923838 API1Output4HVILStatus 8854;
BA_ "SPN" SG_ 2364597758 EngineCyl1IgnitionTimingOffset 7356;
BA_ "SPN" SG_ 2364597758 EngineCyl2IgnitionTimingOffset 7357;
BA_ "SPN" SG_ 2364597758 EngineCyl3IgnitionTimingOffset 7358;
BA_ "SPN" SG_ 2364597758 EngineCyl4IgnitionTimingOffset 7359;
BA_ "SPN" SG_ 2364597758 EngineCyl5IgnitionTimingOffset 7360;
BA_ "SPN" SG_ 2364597758 EngineCyl6IgnitionTimingOffset 7361;
BA_ "SPN" SG_ 2364597758 EngineCyl7IgnitionTimingOffset 7362;
BA_ "SPN" SG_ 2364597758 EngineCyl8IgnitionTimingOffset 7363;
BA_ "SPN" SG_ 2364598014 EngineCyl9IgnitionTimingOffset 7364;
BA_ "SPN" SG_ 2364598014 EngineCyl10IgnitionTimingOffset 7365;
BA_ "SPN" SG_ 2364598014 EngineCyl11IgnitionTimingOffset 7366;
BA_ "SPN" SG_ 2364598014 EngineCyl12IgnitionTimingOffset 7367;
BA_ "SPN" SG_ 2364598014 EngineCyl13IgnitionTimingOffset 7368;
BA_ "SPN" SG_ 2364598014 EngineCyl14IgnitionTimingOffset 7369;
BA_ "SPN" SG_ 2364598014 EngineCyl15IgnitionTimingOffset 7370;
BA_ "SPN" SG_ 2364598014 EngineCyl16IgnitionTimingOffset 7371;
BA_ "SPN" SG_ 2364598270 EngineCyl17IgnitionTimingOffset 7372;
BA_ "SPN" SG_ 2364598270 EngineCyl18IgnitionTimingOffset 7373;
BA_ "SPN" SG_ 2364598270 EngineCyl19IgnitionTimingOffset 7374;
BA_ "SPN" SG_ 2364598270 EngineCyl20IgnitionTimingOffset 7375;
BA_ "SPN" SG_ 2364598270 EngineCyl21IgnitionTimingOffset 7376;
BA_ "SPN" SG_ 2364598270 EngineCyl22IgnitionTimingOffset 7377;
BA_ "SPN" SG_ 2364598270 EngineCyl23IgnitionTimingOffset 7378;
BA_ "SPN" SG_ 2364598270 EngineCyl24IgnitionTimingOffset 7379;
BA_ "SPN" SG_ 2364598526 EngineFuelActr3ControlCommand 7593;
BA_ "SPN" SG_ 2364598526 EngineFuelActr4ControlCommand 7594;
BA_ "SPN" SG_ 2565925374 Aftertreatment1SCRIntakeNOx2 7649;
BA_ "SPN" SG_ 2565925374 Aftrtrtmnt1IntakePercentOxygen2 7650;
BA_ "SPN" SG_ 2565925374 Aftrtrtmnt1IntkGsSensor2PwrInRng 7651;
BA_ "SPN" SG_ 2565925374 Aftrtrtmnt1IntkGsSnsr2AtTemp 7652;
BA_ "SPN" SG_ 2565925374 Aftrtrtmnt1SCRIntkNOx2RdngStable 7653;
BA_ "SPN" SG_ 2565925374 Aft1IntkWdRngPrcntOxg2RdngStable 7654;
BA_ "SPN" SG_ 2565925374 Aft1IntkGsSnsr2HtrPrelimFMI 7655;
BA_ "SPN" SG_ 2565925374 Aftrtrtmnt1IntkGsSensor2HtrCtrl 7656;
BA_ "SPN" SG_ 2565925374 Aft1SCRIntkNOxSnsr2PrelimFMI 7657;
BA_ "SPN" SG_ 2565925374 Aft1IntkNOxSnsr2SelfDiagnssStat 7658;
BA_ "SPN" SG_ 2565925374 Aft1IntkOxygnSnsr2PrelimFMI 7659;
BA_ "SPN" SG_ 2565925630 Aftertreatment1OutletNOx2 7660;
BA_ "SPN" SG_ 2565925630 Aftrtrtmnt1OutletPercentOxygen2 7661;
BA_ "SPN" SG_ 2565925630 Aftrtrtmnt1OtltGsSensor2PwrInRng 7662;
BA_ "SPN" SG_ 2565925630 Aftrtrtmnt1OtltGsSnsr2AtTemp 7663;
BA_ "SPN" SG_ 2565925630 Aftrtrtmnt1OtltNOx2ReadingStable 7664;
BA_ "SPN" SG_ 2565925630 Aft1OtltWdRngPrcntOxg2RdngStable 7665;
BA_ "SPN" SG_ 2565925630 Aft1OtltGsSnsr2HtrPrelimFMI 7666;
BA_ "SPN" SG_ 2565925630 Aftrtrtmnt1OtltGsSensor2HtrCtrl 7667;
BA_ "SPN" SG_ 2565925630 Aftrtrtmnt1OtltNOxSnsr2PrelimFMI 7668;
BA_ "SPN" SG_ 2565925630 Aft1OtltNOxSnsr2SelfDiagnssStat 7669;
BA_ "SPN" SG_ 2565925630 Aft1OtltOxygnSnsr2PrelimFMI 7670;
BA_ "SPN" SG_ 2565925886 Aftertreatment2SCRIntakeNOx2 7671;
BA_ "SPN" SG_ 2565925886 Aftrtrtmnt2IntakePercentOxygen2 7672;
BA_ "SPN" SG_ 2565925886 Aftrtrtmnt2IntkGsSensor2PwrInRng 7673;
BA_ "SPN" SG_ 2565925886 Aftrtrtmnt2IntkGsSnsr2AtTemp 7674;
BA_ "SPN" SG_ 2565925886 Aftrtrtmnt2SCRIntkNOx2RdngStable 7675;
BA_ "SPN" SG_ 2565925886 Aft2IntkWdRngPrcntOxg2RdngStable 7676;
BA_ "SPN" SG_ 2565925886 Aft2IntkGsSnsr2HtrPrelimFMI 7677;
BA_ "SPN" SG_ 2565925886 Aftrtrtmnt2IntkGsSensor2HtrCtrl 7678;
BA_ "SPN" SG_ 2565925886 Aft2SCRIntkNOxSnsr2PrelimFMI 7679;
BA_ "SPN" SG_ 2565925886 Aft2IntkNOxSnsr2SelfDiagnssStat 7680;
BA_ "SPN" SG_ 2565925886 Aft2IntkOxygnSnsr2PrelimFMI 7681;
BA_ "SPN" SG_ 2565926142 Aftertreatment2OutletNOx2 7682;
BA_ "SPN" SG_ 2565926142 Aftrtrtmnt2OutletPercentOxygen2 7683;
BA_ "SPN" SG_ 2565926142 Aftrtrtmnt2OtltGsSensor2PwrInRng 7684;
BA_ "SPN" SG_ 2565926142 Aftrtrtmnt2OtltGsSnsr2AtTemp 7685;
BA_ "SPN" SG_ 2565926142 Aftrtrtmnt2OtltNOx2ReadingStable 7686;
BA_ "SPN" SG_ 2565926142 Aft2OtltWdRngPrcntOxg2RdngStable 7687;
BA_ "SPN" SG_ 2565926142 Aft2OtltGsSnsr2HtrPrelimFMI 7688;
BA_ "SPN" SG_ 2565926142 Aftrtrtmnt2OtltGsSensor2HtrCtrl 7689;
BA_ "SPN" SG_ 2565926142 Aftrtrtmnt2OtltNOxSnsr2PrelimFMI 7690;
BA_ "SPN" SG_ 2565926142 Aft2OtltNOxSnsr2SelfDiagnssStat 7691;
BA_ "SPN" SG_ 2565926142 Aft2OtltOxygnSnsr2PrelimFMI 7692;
BA_ "SPN" SG_ 2431708670 EngineStartRequest 7745;
BA_ "SPN" SG_ 2431708670 EngineStartConsent 7746;
BA_ "SPN" SG_ 2431708670 TrnsmShftSlctorRqedVhclDirection 7788;
BA_ "SPN" SG_ 2431708670 EngineStartAbortRequest 7747;
BA_ "SPN" SG_ 2431708670 EngineStarter1Feedback 7748;
BA_ "SPN" SG_ 2431708670 EngineStarter2Feedback 7749;
BA_ "SPN" SG_ 2431708670 EngineStartControlMessageCounter 7750;
BA_ "SPN" SG_ 2431708670 EngineStartControlChecksum 7751;
BA_ "SPN" SG_ 2431710718 EngineStartControlMessageRate 7752;
BA_ "SPN" SG_ 2431710718 EngineStarterCommand 7753;
BA_ "SPN" SG_ 2431710718 EngineStartRequestLatchStatus 7754;
BA_ "SPN" SG_ 2431710718 OperatorEngineStartConsntSummary 7755;
BA_ "SPN" SG_ 2431710718 AutoEngineStartConsentSummary 7756;
BA_ "SPN" SG_ 2431710718 EngineStartArbitratorMessageCntr 7757;
BA_ "SPN" SG_ 2431710718 EngineStartArbitratorChecksum 7758;
BA_ "SPN" SG_ 2364602878 EngValveCtrlMdul1PreliminaryFMI 7770;
BA_ "SPN" SG_ 2364602878 EngValveCtrlMdul2PreliminaryFMI 7771;
BA_ "SPN" SG_ 2364602878 EngValveCtrlMdul3PreliminaryFMI 7772;
BA_ "SPN" SG_ 2364602878 EngValveCtrlMdul4PreliminaryFMI 7773;
BA_ "SPN" SG_ 2364602878 EngValveCtrlMdul5PreliminaryFMI 7774;
BA_ "SPN" SG_ 2364602878 EngValveCtrlMdul6PreliminaryFMI 7775;
BA_ "SPN" SG_ 2364602878 EngValveCtrlMdul7PreliminaryFMI 7776;
BA_ "SPN" SG_ 2364602878 EngValveCtrlMdul8PreliminaryFMI 7777;
BA_ "SPN" SG_ 2364603134 MaxFrwdTransmissionOutptShftSpd 7779;
BA_ "SPN" SG_ 2364603134 MaxReverseTrnsmOutptShftSpd 7780;
BA_ "SPN" SG_ 2364603134 SrcAddrActvPendingTrnsmRqedGear 8613;
BA_ "SPN" SG_ 2364603390 Aft1DslExhstFldRqedQtyIntgrtr 7783;
BA_ "SPN" SG_ 2364603390 Aft1DslExhstFldDoserVlv1Cmd 8442;
BA_ "SPN" SG_ 2364603646 Aft2DslExhstFldRqedQtyIntgrtr 7784;
BA_ "SPN" SG_ 2364603902 Aft1DslExhstFldActlQtyIntgrtr 7786;
BA_ "SPN" SG_ 2364604158 Aft2DslExhstFldActlQtyIntgrtr 7787;
BA_ "SPN" SG_ 2364604414 FrontHitchRollAngle 7790;
BA_ "SPN" SG_ 2364604414 FrontHitchRollLimitState 7791;
BA_ "SPN" SG_ 2364604414 FrontHitchRollExitReasonCode 7792;
BA_ "SPN" SG_ 2364604414 FrontHitchPitchAngle 7793;
BA_ "SPN" SG_ 2364604414 FrontHitchPitchLimitState 7794;
BA_ "SPN" SG_ 2364604414 FrontHitchPitchExitReasonCode 7795;
BA_ "SPN" SG_ 2364604670 FrontHitchRollCommand 7796;
BA_ "SPN" SG_ 2364604670 FrontHitchRollSensitivityCommand 7797;
BA_ "SPN" SG_ 2364604670 FrontHitchPitchCommand 7798;
BA_ "SPN" SG_ 2364604670 FrontHitchPitchSensitivityCmd 7799;
BA_ "SPN" SG_ 2364604926 RearHitchRollAngle 7802;
BA_ "SPN" SG_ 2364604926 RearHitchRollLimitState 7803;
BA_ "SPN" SG_ 2364604926 RearHitchRollExitReasonCode 7804;
BA_ "SPN" SG_ 2364604926 RearHitchPitchAngle 7805;
BA_ "SPN" SG_ 2364604926 RearHitchPitchLimitState 7806;
BA_ "SPN" SG_ 2364604926 RearHitchPitchExitReasonCode 7807;
BA_ "SPN" SG_ 2364605182 RearHitchRollCommand 7808;
BA_ "SPN" SG_ 2364605182 RearHitchRollSensitivityCommand 7809;
BA_ "SPN" SG_ 2364605182 RearHitchPitchCommand 7810;
BA_ "SPN" SG_ 2364605182 RearHitchPitchSensitivityCommand 7811;
BA_ "SPN" SG_ 2364605438 GeneratorTripKWHoursExport 7831;
BA_ "SPN" SG_ 2364605438 GeneratorTripKVArHoursExport 7832;
BA_ "SPN" SG_ 2565932286 EngineSpeed4 7846;
BA_ "SPN" SG_ 2364605950 HydraulicLinePressure 7939;
BA_ "SPN" SG_ 2364605950 MechanicalMovementAngle 7940;
BA_ "SPN" SG_ 2565932798 WellStimulationPumpSuctionPress 8154;
BA_ "SPN" SG_ 2565932798 WellStimulationPumpDisChrgPress 8155;
BA_ "SPN" SG_ 2565933054 WellStimulationPmpGearBoxOilPrs 8156;
BA_ "SPN" SG_ 2565933054 WellStimulationPmpGearBoxOilTemp 8157;
BA_ "SPN" SG_ 2565933054 WellStimulationPumpSpeed 8158;
BA_ "SPN" SG_ 2364606718 HVES1Module1OperationalStatus 8214;
BA_ "SPN" SG_ 2364606718 HVES1Module2OperationalStatus 8215;
BA_ "SPN" SG_ 2364606718 HVES1Module3OperationalStatus 8216;
BA_ "SPN" SG_ 2364606718 HVES1Module4OperationalStatus 8217;
BA_ "SPN" SG_ 2364606718 HVES1Module5OperationalStatus 8218;
BA_ "SPN" SG_ 2364606718 HVES1Module6OperationalStatus 8219;
BA_ "SPN" SG_ 2364606718 HVES1Module7OperationalStatus 8220;
BA_ "SPN" SG_ 2364606718 HVES1Module8OperationalStatus 8221;
BA_ "SPN" SG_ 2364606718 HVES1Module9OperationalStatus 8222;
BA_ "SPN" SG_ 2364606718 HVES1Module10OperationalStatus 8223;
BA_ "SPN" SG_ 2364606718 HVES1Module11OperationalStatus 8224;
BA_ "SPN" SG_ 2364606718 HVES1Module12OperationalStatus 8225;
BA_ "SPN" SG_ 2364606718 HVES1Module13OperationalStatus 8226;
BA_ "SPN" SG_ 2364606718 HVES1Module14OperationalStatus 8227;
BA_ "SPN" SG_ 2364606718 HVES1Module15OperationalStatus 8228;
BA_ "SPN" SG_ 2364606718 HVES1Module16OperationalStatus 8229;
BA_ "SPN" SG_ 2364606974 HVES1ThermalMangmntSysSLIInptPwr 8230;
BA_ "SPN" SG_ 2364606974 HVES1ThrmlMngmtSysHiVltgInptPwr 8231;
BA_ "SPN" SG_ 2364606974 HVES1ThrmlMangmntSysCmprssorSpd 8232;
BA_ "SPN" SG_ 2364606974 HVES1ThermalMangmntSysRelHumidty 8233;
BA_ "SPN" SG_ 2364606974 HVES1ThermalMangmntSystemHtrStat 8234;
BA_ "SPN" SG_ 2364606974 HVES1ThermalManagementSystemMode 8235;
BA_ "SPN" SG_ 2364607230 HVES1HghestCellVoltageMdulNumber 8236;
BA_ "SPN" SG_ 2364607230 HVES1HghestCellVoltageCellNumber 8237;
BA_ "SPN" SG_ 2364607230 HVES1LowestCellVoltageMdulNumber 8238;
BA_ "SPN" SG_ 2364607230 HVES1LowestCellVoltageCellNumber 8239;
BA_ "SPN" SG_ 2364607230 HVES1AverageCellVoltage 8240;
BA_ "SPN" SG_ 2364607486 HVES1HghestCellTemperatureMdulNo 8241;
BA_ "SPN" SG_ 2364607486 HVES1HghestCellTemperatureCellNo 8242;
BA_ "SPN" SG_ 2364607486 HVES1LowestCellTemperatureMdulNo 8243;
BA_ "SPN" SG_ 2364607486 HVES1LowestCellTemperatureCellNo 8244;
BA_ "SPN" SG_ 2364607742 HVES1HghestCellStateChrgMdulNo 8245;
BA_ "SPN" SG_ 2364607742 HVES1HghestCellStateChrgCellNo 8246;
BA_ "SPN" SG_ 2364607742 HVES1LowestCellStateChrgMdulNo 8247;
BA_ "SPN" SG_ 2364607742 HVES1LowestCellStateChrgCellNo 8248;
BA_ "SPN" SG_ 2364607742 HVES1HiVltgBusActIsolatnTestRess 8431;
BA_ "SPN" SG_ 2364607742 HVES1HiVltgBusPassIsolatnTtRess 8432;
BA_ "SPN" SG_ 2565934590 EngineFuelValve2DiffPressure 6885;
BA_ "SPN" SG_ 2498825982 DumpBodyRollAngle 8312;
BA_ "SPN" SG_ 2498825982 DumpBodyRaiseAngle 8313;
BA_ "SPN" SG_ 2498825982 DumpBodyRaisePsRelToRecmmndedMax 8314;
BA_ "SPN" SG_ 2498825982 DumpBodyEjectorBladePosition 8315;
BA_ "SPN" SG_ 2364608510 EngineSelfInducedDerateLoad 8435;
BA_ "SPN" SG_ 2364608510 EnginePowerDerateRequest 8436;
BA_ "SPN" SG_ 2297499902 DemandedBrakeApplicationPressure 8484;
BA_ "SPN" SG_ 2297499902 BrakePedalSwitch2 603;
BA_ "SPN" SG_ 2431717886 EngineFuelValve1DiffPressure 8494;
BA_ "SPN" SG_ 2364609278 DCDC1OperationalCommand 8560;
BA_ "SPN" SG_ 2364609278 DCDC1LowSideVoltageBuckSetpoint 8561;
BA_ "SPN" SG_ 2364609278 DCDC1HghSideVoltageBoostSetpoint 8562;
BA_ "SPN" SG_ 2364609534 DCDC1OperationalStatus 8569;
BA_ "SPN" SG_ 2364609534 DCDC1HVILStatus 8570;
BA_ "SPN" SG_ 2364609534 DCDC1LoadshedRequest 8571;
BA_ "SPN" SG_ 2364609534 DCDC1PowerLimitDueToHighSideCurr 8572;
BA_ "SPN" SG_ 2364609534 DCDC1PowerLimitDueToLowSideCurr 8573;
BA_ "SPN" SG_ 2364609534 DCDC1PowerLmtDTHghSideVoltageMin 8574;
BA_ "SPN" SG_ 2364609534 DCDC1PowerLmtDTHghSideVoltageMax 8575;
BA_ "SPN" SG_ 2364609534 DCDC1PowerLmtDTLowSideVoltageMin 8576;
BA_ "SPN" SG_ 2364609534 DCDC1PowerLmtDTLowSideVoltageMax 8577;
BA_ "SPN" SG_ 2364609534 DCDC1PwrLmtDTCtrllerTemperature 8578;
BA_ "SPN" SG_ 2364609534 DCDC1PwrLmtDTElctrncFilterTemp 8579;
BA_ "SPN" SG_ 2364609534 DCDC1PwrLmtDTPwrElctrncsTemp 8580;
BA_ "SPN" SG_ 2364609534 DCDC1PwrLmtDTSLIBattTerminalVltg 8581;
BA_ "SPN" SG_ 2364609534 DCDC1PwrLmtDTSLIBattTerminalCurr 8583;
BA_ "SPN" SG_ 2364609534 DCDC1PwrLmtDTSLIBattTerminalTemp 8582;
BA_ "SPN" SG_ 2364609534 DCDC1PowerLimitDTUndefinedReason 8584;
BA_ "SPN" SG_ 2364609790 DCDC1LowSideVoltage 8585;
BA_ "SPN" SG_ 2364609790 DCDC1LowSideCurrent 8586;
BA_ "SPN" SG_ 2364609790 DCDC1HighSideVoltage 8587;
BA_ "SPN" SG_ 2364609790 DCDC1HighSideCurrent 8588;
BA_ "SPN" SG_ 2364610046 DCDC1SLIBatteryTerminalVoltage 8589;
BA_ "SPN" SG_ 2364610046 DCDC1SLIBatteryTerminalCurrent 8590;
BA_ "SPN" SG_ 2364610046 DCDC1SLIBattryTerminalTemp 8591;
BA_ "SPN" SG_ 2431719166 WellStimulationPumpRodLoad 8648;
BA_ "SPN" SG_ 2431719166 WellStimulationPmpCavitationStat 8649;
BA_ "SPN" SG_ 2431719166 WellStimultnPmpFldEndValveLeak 8651;
BA_ "SPN" SG_ 2431719166 WellStimulationPumpFlowRate 8650;
BA_ "SPN" SG_ 2364610558 DCDC1LowSidePower 8820;
BA_ "SPN" SG_ 2364610558 DCDC1HighSidePower 8821;
BA_ "SPN" SG_ 2566638590 ExhstPrtcltCtrlSystemDiagTime 8887;
BA_ "SPN" SG_ 2566638590 ExhstPrtcltCtrlSystemDiagCnt 8888;
BA_ "SPN" SG_ 2566638846 WellStimultnPmpMaintenIntvalHrs 8882;
BA_ "SPN" SG_ 2566638846 WellStimulationPumpValveOpHrs 8883;
BA_ "SPN" SG_ 2566638846 WellStimulationPumpPackingOpHrs 8884;
BA_ "SPN" SG_ 2566638846 WellStimulationPmpValveSeatOpHrs 8885;
BA_ "SPN" SG_ 2566639102 WellStimPmpGrBxOilPrsLoTrshldStt 8871;
BA_ "SPN" SG_ 2566639102 WellStimPmpGrBxOilPrsHiTrshldStt 8872;
BA_ "SPN" SG_ 2566639102 WellStimPmpGrBxOilTmpLoTrshldStt 8873;
BA_ "SPN" SG_ 2566639102 WellStimPmpGrBxOilTmpHiTrshldStt 8874;
BA_ "SPN" SG_ 2566639102 WellStimPmpSuctionPrsLoTrshldStt 8875;
BA_ "SPN" SG_ 2566639102 WellStimPmpSuctionPrsHiTrshldStt 8876;
BA_ "SPN" SG_ 2566639102 WellStimPmpDisChrgPrsHiTrshldStt 8877;
BA_ "SPN" SG_ 2566639102 WellStimuPmpCrankSpdLoTrshldStt 8878;
BA_ "SPN" SG_ 2566639102 WellStimuPmpCrankSpdHiTrshldStt 8879;
BA_ "SPN" SG_ 2566639102 WellStimuPmpRodLoadHiTrshldStt 8880;
BA_ "SPN" SG_ 2566639102 WellStimPmpPlungerFiringOrderStt 8881;
BA_ "SPN" SG_ 2633748222 ReceiveSPNsPort 8842;
BA_ "SPN" SG_ 2633748222 ReceiveSPNsPortPendingChangesSt 8843;
BA_ "SPN" SG_ 2633748222 ReceiveSPNsPortCommandStatus 8844;
BA_ "SPN" SG_ 2633748222 ConfigurableReceiveSPN 8845;
BA_ "SPN" SG_ 2633748222 ConfigurableReceiveSPNDetailedSt 8848;
BA_ "SPN" SG_ 2633748222 ConfigurableReceiveSPNSourceAddr 8846;
BA_ "SPN" SG_ 2633748222 ConfigurableReceiveSPNModifiedSt 8847;
BA_ "SPN" SG_ 2566639614 DCDC1TotalHighSideEnergy 8833;
BA_ "SPN" SG_ 2566639614 DCDC1TotalLowSideEnergy 8834;
BA_ "SPN" SG_ 2566639614 DCDC1TotalHighSideCharge 8835;
BA_ "SPN" SG_ 2566639614 DCDC1TotalLowSideCharge 8836;
BA_ "SPN" SG_ 2566639870 DCDC1HghSideVoltageMinLmtSetting 8824;
BA_ "SPN" SG_ 2566639870 DCDC1HghSideVoltageMaxLmtSetting 8825;
BA_ "SPN" SG_ 2566639870 DCDC1HghSideCurrMaxLmtSetting 8826;
BA_ "SPN" SG_ 2566639870 DCDC1LowSideVoltageMinLmtSetting 8827;
BA_ "SPN" SG_ 2566639870 DCDC1LowSideVoltageMaxLmtSetting 8828;
BA_ "SPN" SG_ 2566639870 DCDC1LowSideCurrMaxLmtSetting 8829;
BA_ "SPN" SG_ 2566639870 DCDC1SLIBattTermnlVltgMaxLmtStt 8830;
BA_ "SPN" SG_ 2566639870 DCDC1SLIBattTermChrgCurMaxLmtStt 8831;
BA_ "SPN" SG_ 2566639870 DCDC1SLIBattryTempMaxLmtSttng 8832;
BA_ "SPN" SG_ 2365313534 DCDC1SLIBattryTermnlVltgMaxLmtRq 8817;
BA_ "SPN" SG_ 2365313534 DCDC1SLIBattTermChrgCurMaxLmtRq 8818;
BA_ "SPN" SG_ 2365313534 DCDC1SLIBattryTempMaxLmtRq 8819;
BA_ "SPN" SG_ 2566640382 WellStimulationPumpOilViscosity 8660;
BA_ "SPN" SG_ 2566640382 WellStimulationPumpOilDensity 8661;
BA_ "SPN" SG_ 2566640382 WellStimuPmpOilRelDielectricity 8662;
BA_ "SPN" SG_ 2566640382 WellStimulationPmpOilTemperature 8663;
BA_ "SPN" SG_ 2633749502 WellStimultnPmpFldEndWorkingHrs 8656;
BA_ "SPN" SG_ 2633749502 WellStimultnPmpPwrEndWorkingHrs 8657;
BA_ "SPN" SG_ 2633749502 WellStimulationPumpWorkingHours 8658;
BA_ "SPN" SG_ 2633749502 WellStimulationPumpCycleCount 8659;
BA_ "SPN" SG_ 2633749758 WellStimultnPmpPlungerDiameter 8652;
BA_ "SPN" SG_ 2633749758 WellStimulationPumpStrokeLength 8653;
BA_ "SPN" SG_ 2633749758 WellStimulationPumpGearRatio 8654;
BA_ "SPN" SG_ 2633749758 WellStimulationPumpRatedSpeed 8655;
BA_ "SPN" SG_ 2566641150 AltrntrBearingHeaderIntkPressure 8635;
BA_ "SPN" SG_ 2566641150 AltrntrOilCoolDisChrgPumpPress 8636;
BA_ "SPN" SG_ 2566641150 EngineOilCoolDisChrgPumpPressure 8637;
BA_ "SPN" SG_ 2566641150 EngineOilCoolerIntakeTemperature 8638;
BA_ "SPN" SG_ 2566641406 EngExhaustManifoldAbsPressure1 8619;
BA_ "SPN" SG_ 2566641406 EngExhaustManifoldAbsPressure2 8620;
VAL_ 2565869566 Aftrtrtmnt1OtltGasSensorPwrInRng 0 "Not in range" 1 "In range" 2 "Error" 3 "Not available" ;
VAL_ 2565869566 Aftrtrtmnt1OtltGasSnsrAtTemp 0 "Not in range" 1 "In range" 2 "Error" 3 "Not available" ;
VAL_ 2565869566 Aftrtrtmnt1OtltNOxReadingStable 0 "Not stable" 1 "Stable" 2 "Error" 3 "Not available" ;
VAL_ 2565869566 Aftrtrtmnt1OtltWdRngO2RdngStable 0 "Not stable" 1 "Stable" 2 "Error" 3 "Not available" ;
VAL_ 2565869566 Aftrtrtmnt1OtltGasSensorHtrCtrl 0 "Automatic" 1 "Preheat 2" 2 "Preheat 1" 3 "Heater off" ;
VAL_ 2565869566 Aft1OtltNOxSnsrSelfDiagnssStat 0 "Diagnosis not active" 1 "NOx Sensor ATO1 Self Diagnosis active flag" 2 "NOx Sensor ATO1 Self Diagnosis Result Complete" 3 "NOx Sensor ATO1 Self Diagnosis aborted" 4 "NOx Sensor ATO1 Self Diagnosis not possible" 7 "Not Supported" ;
VAL_ 2565869822 Aftrtrtmnt2IntkGasSensorPwrInRng 0 "Not in range" 1 "In range" 2 "Error" 3 "Not available" ;
VAL_ 2565869822 Aftrtrtmnt2IntkGasSnsrAtTemp 0 "Not in range" 1 "In range" 2 "Error" 3 "Not available" ;
VAL_ 2565869822 Aft2SlctiveCtlytcRedIntkNOxRdngS 0 "Not stable" 1 "Stable" 2 "Error" 3 "Not available" ;
VAL_ 2565869822 Aft2IntkWdRngPrcntO2RdngStable 0 "Not stable" 1 "Stable" 2 "Error" 3 "Not available" ;
VAL_ 2565869822 Aftrtrtmnt2IntkGasSensorHtrCtrl 0 "Automatic" 1 "Preheat 2" 2 "Preheat 1" 3 "Heater off" ;
VAL_ 2565869822 Aft2IntkNOxSnsrSelfDiagnssStat 0 "Diagnosis not active" 1 "NOx Sensor ATI2 Self Diagnosis active flag" 2 "NOx Sensor ATI2 Self Diagnosis Result Complete" 3 "NOx Sensor ATI2 Self Diagnosis aborted" 4 "NOx Sensor ATI2 Self Diagnosis not possible" 7 "Not Supported" ;
VAL_ 2565869822 Aftrtrtmnt2Intk2GsSnsrPwrSupply 0 "Off" 1 "On" 2 "Error" 3 "Unavailable" ;
VAL_ 2565870078 Aftrtrtmnt2OtltGasSensorPwrInRng 0 "Not in range" 1 "In range" 2 "Error" 3 "Not available" ;
VAL_ 2565870078 Aftrtrtmnt2OtltGasSnsrAtTemp 0 "Not in range" 1 "In range" 2 "Error" 3 "Not available" ;
VAL_ 2565870078 Aftrtrtmnt2OtltNOxReadingStable 0 "Not stable" 1 "Stable" 2 "Error" 3 "Not available" ;
VAL_ 2565870078 Aftrtrtmnt2OtltWdRngO2RdngStable 0 "Not stable" 1 "Stable" 2 "Error" 3 "Not available" ;
VAL_ 2565870078 Aftrtrtmnt2OtltGasSensorHtrCtrl 0 "Automatic" 1 "Preheat 2" 2 "Preheat 1" 3 "Heater off" ;
VAL_ 2565870078 Aft2OtltNOxSnsrSelfDiagnssStat 0 "Diagnosis not active" 1 "NOx Sensor ATO2 Self Diagnosis active flag" 2 "NOx Sensor ATO2 Self Diagnosis Result Complete" 3 "NOx Sensor ATO2 Self Diagnosis aborted" 4 "NOx Sensor ATO2 Self Diagnosis not possible" 7 "Not Supported" ;
VAL_ 2565870078 Aftrtrtmnt2Otlt2GsSnsrPwrSupply 0 "Off" 1 "On" 2 "Error" 3 "Unavailable" ;
VAL_ 2565870334 FifthWheelRollWarningIndicator 0 "Limit not exceeded" 1 "Limit exceeded" 2 "Error" 3 "Not Available" ;
VAL_ 2364543998 PitchAngleFigureOfMerit 0 "Pitch angle fully functional" 1 "Pitch angle degraded" 2 "Error" 3 "Not available" ;
VAL_ 2364543998 RollAngleFigureOfMerit 0 "Roll angle fully functional" 1 "Roll angle degraded" 2 "Error" 3 "Not available" ;
VAL_ 2364543998 PitchRateFigureOfMerit 0 "Pitch rate fully functional" 1 "Pitch rate degraded" 2 "Error" 3 "Not available" ;
VAL_ 2364543998 PitchAndRollCompensated 0 "Compensation Off" 1 "Compensation On" 2 "Error" 3 "Not Available" ;
VAL_ 2364544254 RelativeBladeHeightFigureOfMerit 0 "Relative Blade Height fully functional" 1 "Relative Blade Height degraded" 2 "Relative Blade Height failed" 3 "Relative Blade Height not available" ;
VAL_ 2364544254 BladeRotationAngleFigureOfMerit 0 "Blade Rotation Angle fully functional" 1 "Blade Rotation Angle  degraded" 2 "Blade Rotation Angle failed" 3 "Blade Rotation Angle not available" ;
VAL_ 2364544510 RqedGenOverallPwrFactorLagging 0 "Leading" 1 "Lagging" 2 "Reserved" 3 "Not available or Not installed" ;
VAL_ 2364544766 EngineCylinder1CombustionStatus 0 "No combustion" 1 "Combustion exists" 2 "Error" 3 "Not available" ;
VAL_ 2364544766 EngineCylinder2CombustionStatus 0 "No combustion" 1 "Combustion exists" 2 "Error" 3 "Not available" ;
VAL_ 2364544766 EngineCylinder3CombustionStatus 0 "No combustion" 1 "Combustion exists" 2 "Error" 3 "Not available" ;
VAL_ 2364544766 EngineCylinder4CombustionStatus 0 "No combustion" 1 "Combustion exists" 2 "Error" 3 "Not available" ;
VAL_ 2364544766 EngineCylinder5CombustionStatus 0 "No combustion" 1 "Combustion exists" 2 "Error" 3 "Not available" ;
VAL_ 2364544766 EngineCylinder6CombustionStatus 0 "No combustion" 1 "Combustion exists" 2 "Error" 3 "Not available" ;
VAL_ 2364544766 EngineCylinder7CombustionStatus 0 "No combustion" 1 "Combustion exists" 2 "Error" 3 "Not available" ;
VAL_ 2364544766 EngineCylinder8CombustionStatus 0 "No combustion" 1 "Combustion exists" 2 "Error" 3 "Not available" ;
VAL_ 2364544766 EngineCylinder9CombustionStatus 0 "No combustion" 1 "Combustion exists" 2 "Error" 3 "Not available" ;
VAL_ 2364544766 EngineCylinder10CombustionStatus 0 "No combustion" 1 "Combustion exists" 2 "Error" 3 "Not available" ;
VAL_ 2364544766 EngineCylinder11CombustionStatus 0 "No combustion" 1 "Combustion exists" 2 "Error" 3 "Not available" ;
VAL_ 2364544766 EngineCylinder12CombustionStatus 0 "No combustion" 1 "Combustion exists" 2 "Error" 3 "Not available" ;
VAL_ 2364544766 EngineCylinder13CombustionStatus 0 "No combustion" 1 "Combustion exists" 2 "Error" 3 "Not available" ;
VAL_ 2364544766 EngineCylinder14CombustionStatus 0 "No combustion" 1 "Combustion exists" 2 "Error" 3 "Not available" ;
VAL_ 2364544766 EngineCylinder15CombustionStatus 0 "No combustion" 1 "Combustion exists" 2 "Error" 3 "Not available" ;
VAL_ 2364544766 EngineCylinder16CombustionStatus 0 "No combustion" 1 "Combustion exists" 2 "Error" 3 "Not available" ;
VAL_ 2364544766 EngineCylinder17CombustionStatus 0 "No combustion" 1 "Combustion exists" 2 "Error" 3 "Not available" ;
VAL_ 2364544766 EngineCylinder18CombustionStatus 0 "No combustion" 1 "Combustion exists" 2 "Error" 3 "Not available" ;
VAL_ 2364544766 EngineCylinder19CombustionStatus 0 "No combustion" 1 "Combustion exists" 2 "Error" 3 "Not available" ;
VAL_ 2364544766 EngineCylinder20CombustionStatus 0 "No combustion" 1 "Combustion exists" 2 "Error" 3 "Not available" ;
VAL_ 2364544766 EngineCylinder21CombustionStatus 0 "No combustion" 1 "Combustion exists" 2 "Error" 3 "Not available" ;
VAL_ 2364544766 EngineCylinder22CombustionStatus 0 "No combustion" 1 "Combustion exists" 2 "Error" 3 "Not available" ;
VAL_ 2364544766 EngineCylinder23CombustionStatus 0 "No combustion" 1 "Combustion exists" 2 "Error" 3 "Not available" ;
VAL_ 2364544766 EngineCylinder24CombustionStatus 0 "No combustion" 1 "Combustion exists" 2 "Error" 3 "Not available" ;
VAL_ 2565873150 SteeringWheelAglRangeCounterType 0 "relative number of counts" 1 "absolute number of counts" 2 "not defined" 3 "signal not available" ;
VAL_ 2565873150 SteeringAngleSensorActiveMode 0 "Programming mode active" 1 "Normal mode active" 2 "Reserved" 3 "Not available" ;
VAL_ 2565873150 SteeringAngleSensorCalibrated 0 "SAS not calibrated" 1 "SAS calibrated" 2 "Reserved" 3 "Not available" ;
VAL_ 2364546814 EngineSelfInducedDerateInhibit 0 "Engine is allowed to impose a self-induced derate" 1 "Engine is inhibited from imposing a self-induced derate" 2 "SAE Reserved" 3 "Don't care / take no action" ;
VAL_ 2565874174 EngSpeedSnsr3TimingPatternStatus 0 "Not OK" 1 "OK" 2 "Error" 3 "Not available" ;
VAL_ 2565874174 EngSpeedSnsr2TimingPatternStatus 0 "Not OK" 1 "OK" 2 "Error" 3 "Not available" ;
VAL_ 2565874174 EngSpeedSnsr1TimingPatternStatus 0 "Not OK" 1 "OK" 2 "Error" 3 "Not available" ;
VAL_ 2364548094 Aftertreatment1SCRSystemState 0 "Dormant" 1 "Preparing dosing readiness" 2 "Normal dosing operation" 3 "System error pending" 4 "Purging" 5 "Protect mode against heat" 6 "Protect mode against cold" 7 "Shutoff" 8 "Diagnosis" 9 "Service test mode, dosing allowed " 10 "Service test mode, dosing not allowed" 11 "Ok to Power Down" 12 "Priming" 13 "Reserved for future assignment by SAE" 14 "Error" 15 "Not available" ;
VAL_ 2364548094 Aftertreatment1SCRSystem2State 0 "Dormant" 1 "Preparing dosing readiness" 2 "Normal dosing operation" 3 "System error pending" 4 "Purging" 5 "Protect mode against heat" 6 "Protect mode against cold" 7 "Shutoff" 8 "Diagnosis" 9 "Service test mode, dosing allowed " 10 "Service test mode, dosing not allowed" 11 "Ok to Power Down" 12 "Priming" 13 "Reserved for future assignment by SAE" 14 "Error" 15 "Not available" ;
VAL_ 2364548350 Aftrtrtmnt1SCRSystemRqedState 0 "Dormant" 1 "Preparing dosing readiness" 2 "Normal dosing operation" 3 "System error pending" 4 "Reserved for future assignment by SAE" 5 "Protect mode against heat" 6 "Protect mode against cold" 7 "Shutoff" 8 "Diagnosis" 9 "Service test mode, dosing allowed " 10 "Service test mode, dosing not allowed" 14 "Error" 15 "Not available" ;
VAL_ 2364548350 Aft1DslExhstFldHydrStffnssCkPmSt 0 "not allowed" 1 "DEF hydraulic stiffness check allowed" 2 "error" 3 "not available" ;
VAL_ 2364548350 Aft1DslExhstFldDsngTtInjectPmSt 0 "not allowed" 1 "DEF dosing test injection allowed" 2 "error" 3 "not available" ;
VAL_ 2364548606 Aftrtrtmnt1OtltNH3ReadingStable 0 "Reading is not stable" 1 "Reading is stable" 2 "Error" 3 "Not available" ;
VAL_ 2364548606 Aft1OtltNH3GasSnsrPwrInRng 0 "Power is not in range" 1 "Power is in range" 2 "Error" 3 "Not available" ;
VAL_ 2364548606 Aftrtrtmnt1OtltNH3GasSnsrAtTemp 0 "Heater element is not in range" 1 "Heater element is in range" 2 "Error" 3 "Not available" ;
VAL_ 2364548606 Aftrtrtmnt1OtltNH3GasSnsrHtrCtrl 0 "Automatic " 1 "Preheat 2 " 2 "Preheat 1 " 3 "Heater off or not available" ;
VAL_ 2364548862 Aftertreatment2SCRSystemState 0 "Dormant" 1 "Preparing dosing readiness" 2 "Normal dosing operation" 3 "System error pending" 4 "Reserved for future assignment by SAE" 5 "Protect mode against heat" 6 "Protect mode against cold" 7 "Shutoff" 8 "Diagnosis" 9 "Service test mode, dosing allowed" 10 "Service test mode, dosing not allowed" 11 "Ok to Power Down" 12 "Priming" 13 "Reserved for future assignment by SAE" 14 "Error" 15 "Not available" ;
VAL_ 2364548862 Aftertreatment2SCRSystem2State 0 "Dormant" 1 "Preparing dosing readiness" 2 "Normal dosing operation" 3 "System error pending" 4 "Purging" 5 "Protect mode against heat" 6 "Protect mode against cold" 7 "Shutoff" 8 "Diagnosis" 9 "Service test mode, dosing allowed" 10 "Service test mode, dosing not allowed" 11 "Ok to Power Down" 12 "Priming" 13 "Reserved for future assignment by SAE" 14 "Error" 15 "Not available" ;
VAL_ 2364549118 Aftrtrtmnt2SCRSystemRqedState 0 "Dormant" 1 "Preparing dosing readiness" 2 "Normal dosing operation" 3 "System error pending" 4 "Reserved for future assignment by SAE" 5 "Protect mode against heat" 6 "Protect mode against cold" 7 "Shutoff" 8 "Diagnosis" 9 "Service test mode, dosing allowed " 10 "Service test mode, dosing not allowed" 14 "Error" 15 "Not available" ;
VAL_ 2364549118 Aft2DslExhstFldHydrStffnssCkPmSt 0 "not allowed" 1 "DEF hydraulic stiffness check allowed" 2 "error" 3 "not available" ;
VAL_ 2364549118 Aft2DslExhstFldDsngTtInjectPmSt 0 "not allowed" 1 "DEF dosing test injection allowed" 2 "error" 3 "not available" ;
VAL_ 2364549374 Aftrtrtmnt2OtltNH3ReadingStable 0 "Reading is not stable" 1 "Reading is stable" 2 "Error" 3 "Not available" ;
VAL_ 2364549374 Aft2OtltNH3GasSnsrPwrInRng 0 "Heater element is not in range" 1 "Heater element is in range" 2 "Error" 3 "Not available" ;
VAL_ 2364549374 Aftrtrtmnt2OtltNH3GasSnsrAtTemp 0 "Heater element is not in range" 1 "Heater element is in range" 2 "Error" 3 "Not available" ;
VAL_ 2364549374 Aftrtrtmnt2OtltNH3GasSnsrHtrCtrl 0 "Automatic " 1 "Preheat 2 " 2 "Preheat 1 " 3 "Heater off or not available" ;
VAL_ 2364549630 PitchAngleCompensation 0 "On" 1 "Off" 2 "Error" 3 "Not Available" ;
VAL_ 2364549630 PitchAngleFigureOfMerit 0 "Pitch angle fully functional" 1 "Pitch angle degraded" 2 "Error" 3 "Not available" ;
VAL_ 2364549630 RollAngleCompensation 0 "On" 1 "Off" 2 "Error" 3 "Not Available" ;
VAL_ 2364549630 RollAngleFigureOfMerit 0 "Roll angle fully functional" 1 "Roll angle degraded" 2 "Error" 3 "Not available" ;
VAL_ 2364549886 PitchRateFigureOfMerit 0 "Pitch rate fully functional" 1 "Pitch rate degraded" 2 "Error" 3 "Not available" ;
VAL_ 2364549886 RollRateFigureOfMerit 0 "Roll rate fully functional" 1 "Roll rate degraded" 2 "Error" 3 "Not available" ;
VAL_ 2364549886 YawRateFigureOfMerit 0 "Yaw rate fully functional" 1 "Yaw rate degraded" 2 "Error" 3 "Not available" ;
VAL_ 2163223550 CrashType 1 "frontal crash" 2 "rear crash" 4 "side crash (left)" 8 "side crash (right)" 16 "rollover" ;
VAL_ 2297441534 MaterialLiftSwitch 0 "Don't Lift" 1 "Lift" 2 "Error" 3 "Not Available" ;
VAL_ 2297441534 MaterialDropSwitch 0 "Don't Drop" 1 "Drop" 2 "Error" 3 "Not Available" ;
VAL_ 2297441534 GeneratorCurrentBoostActvStatus 0 "Off" 1 "On" 2 "Error" 3 "Not available" ;
VAL_ 2297441534 MaterialLiftActiveStatus 0 "Off" 1 "On" 2 "Error" 3 "Not available" ;
VAL_ 2297441534 MaterialDropActiveStatus 0 "Off" 1 "On" 2 "Error" 3 "Not available" ;
VAL_ 2297441534 LiftRelayControl 1 "On, Enable Lift Relay Request" 2 "Reserved" 3 "Take No Action" ;
VAL_ 2297441534 DropRelayControl 1 "On, Enable Drop Relay Request" 2 "Reserved" 3 "Take No Action" ;
VAL_ 2297441534 MagnetGeneratorControl 0 "Off, Disable Generator" 1 "On, Enable Generator" 2 "Reserved" 3 "Take No Action" ;
VAL_ 2297441790 LateralAccelerationFigureOfMerit 0 "lateral acceleration is fully functional" 1 "lateral acceleration is degraded" 2 "error" 3 "not available" ;
VAL_ 2297441790 LongitudinalAccltnFigureOfMerit 0 "longitudinal acceleration is fully functional" 1 "longitudinal acceleration is degraded" 2 "error" 3 "not available" ;
VAL_ 2297441790 VerticalAccltnFigureOfMerit 0 "vertical acceleration is fully functional" 1 "verticalacceleration is degraded" 2 "error" 3 "not available" ;
VAL_ 2297441790 SuppVarTrnsmRepttnRateAccltnSnsr 0 "Reserve for SAE assignment" 1 "Reserved for SAE assignment" 2 "20 ms rate supported" 3 "10 ms rate supported" ;
VAL_ 2364551166 AdvEmergencyBrakingSystemState 0 "system is not ready" 1 "system is temporarily not available" 2 "system is deactivated by driver" 3 "system is ready and activated" 4 "driver overrides system" 5 "collision warning active" 6 "collision warning with braking" 7 "emergency braking active" 8 "system performance and/or sensitivity limited" 14 "error indication" 15 "not available / not installed" ;
VAL_ 2364551166 CollisionWarningLevel 0 "no warning" 1 "warning level 1" 2 "warning level 2" 3 "warning level 3" 4 "warning level 4" 5 "warning level 5" 6 "warning level 6" 7 "warning level 7" 15 "don't care / take no action" ;
VAL_ 2364551166 RelvntObjDetctAdvEmrgncyBrkngSys 0 "no relevant object monitored" 1 "relevant object monitored" 2 "relevant object detected" 6 "error indication" 7 "signal not available / not installed" ;
VAL_ 2364551166 BendOffProbabilityOfRelevantObj 0 "no indication" 1 "low probability" 2 "medium probability" 3 "high probability" 4 "highest probability" 5 "object already turning" 6 "error indication" 7 "signal not available / not installed" ;
VAL_ 2364551422 TransmitterCommandState 0 "Stop" 1 "Clear" 2 "Field Test" 3 "Transmitter Test" 4 "Standby" 14 "Error" 15 "Don't Care" ;
VAL_ 2230333950 WandSensorFigureOfMerit 0 "Sensor fully functional" 1 "Sensor degraded" 2 "Sensor failed" 3 "Sensor not available" ;
VAL_ 2230334206 LnrDisplacmntSnsrSnsrFigOfMerit 0 "Sensor fully functional" 1 "Sensor degraded" 2 "Sensor failed" 3 "Sensor not available" ;
VAL_ 2431661054 Aft1SCRIntrmedNH3RdngStable 0 "Reading is not stable" 1 "Reading is stable" 2 "Error" 3 "Not available" ;
VAL_ 2431661054 Aft1SCRIntrmedNH3SnsrPwrInRng 0 "Power is not in range" 1 "Power is in range" 2 "Error" 3 "Not available" ;
VAL_ 2431661054 Aft1SCRIntrmedNH3SnsrAtTemp 0 "Heater element is not in range" 1 "Heater element is in range" 2 "Error" 3 "Not available" ;
VAL_ 2431661054 Aft1SCRIntrmedNH3SnsrHtrCtrl 0 "Automatic " 1 "Preheat 2 " 2 "Preheat 1 " 3 "Heater off or not available" ;
VAL_ 2431661310 Aft2SCRIntrmedNH3RdngStable 0 "Reading is not stable" 1 "Reading is stable" 2 "Error" 3 "Not available" ;
VAL_ 2431661310 Aft2SCRIntrmedNH3SnsrPwrInRng 0 "Heater element is not in range" 1 "Heater element is in range" 2 "Error" 3 "Not available" ;
VAL_ 2431661310 Aft2SCRIntrmedNH3SnsrAtTemp 0 "Heater element is not in range" 1 "Heater element is in range" 2 "Error" 3 "Not available" ;
VAL_ 2431661310 Aft2SCRIntrmedNH3SnsrHtrCtrl 0 "Automatic " 1 "Preheat 2 " 2 "Preheat 1 " 3 "Heater off or not available" ;
VAL_ 2364552958 HVES1DisChrgPowerLmtDTStateChrg 0 "No power limit for this reason" 1 "Power limited for this reason" 2 "Error" 3 "Not Available" ;
VAL_ 2364552958 HVES1DisChrgPwrLmtDTBattryTemp 0 "No power limit for this reason" 1 "Power limited for this reason" 2 "Error" 3 "Not Available" ;
VAL_ 2364552958 HVES1DisChrgPwrLmtDTBattDiagCond 0 "No power limit for this reason" 1 "Power limited for this reason" 2 "Error" 3 "Not Available" ;
VAL_ 2364552958 HVES1DisChrgPwrLmtDTBattCellVltg 0 "No power limit for this reason" 1 "Power limited for this reason" 2 "Error" 3 "Not Available" ;
VAL_ 2364552958 HVES1DisChrgPowerLmtDTBattryCurr 0 "No power limit for this reason" 1 "Power limited for this reason" 2 "Error" 3 "Not Available" ;
VAL_ 2364552958 HVES1DisChrgPwrLmtDTUndefndCause 0 "No power limit for this reason" 1 "Power limited for this reason" 2 "Error" 3 "Not Available" ;
VAL_ 2364552958 HVES1ChrgPowerLimitDTStateChrg 0 "No power limit for this reason" 1 "Power limited for this reason" 2 "Error" 3 "Not Available" ;
VAL_ 2364552958 HVES1ChrgPwrLmtDTBattryTemp 0 "No power limit for this reason" 1 "Power limited for this reason" 2 "Error" 3 "Not Available" ;
VAL_ 2364552958 HVES1ChrgPwrLmtDTBattDiagCondtn 0 "No power limit for this reason" 1 "Power limited for this reason" 2 "Error" 3 "Not Available" ;
VAL_ 2364552958 HVES1ChrgPwrLmtDTBattryCellVltg 0 "No power limit for this reason" 1 "Power limited for this reason" 2 "Error" 3 "Not Available" ;
VAL_ 2364552958 HVES1ChrgPowerLimitDTBattryCurr 0 "No power limit for this reason" 1 "Power limited for this reason" 2 "Error" 3 "Not Available" ;
VAL_ 2364552958 HVES1ChrgPwrLmtDTUndefinedCause 0 "No power limit for this reason" 1 "Power limited for this reason" 2 "Error" 3 "Not Available" ;
VAL_ 2364553214 EngTurboCmprBlowoffActr1TempStat 0 "High Most severe" 1 "High Least severe" 2 "In Range" 3 "Low Least severe" 4 "Low Most severe" 5 "Not Defined" 6 "Error" 7 "Not available" ;
VAL_ 2364553214 EngTurboCmprBlowoffActr1OpStat 0 "Normal" 1 "Alarm" 2 "Alarm High Severity" 3 "Derate Active" 4 "Controlled Shutdown Active" 5 "Uncontrolled Shutdown Active" 6 "Calibration in Progress" 14 "Error" 15 "Not available" ;
VAL_ 2364553470 EngineDualFuelModeCommand 0 "De-activate dual fuel mode" 1 "Activate dual fuel mode" 2 "Reserved" 3 "Not available" ;
VAL_ 2364576254 HVES1CellVoltageDiffStatus 0 "Cell-to-cell voltage differential is within acceptable limits" 1 "Cell-to-cell voltage differential exceeds acceptable limits but can be corrected via auto-balancing" 2 "Cell-to-cell voltage differential exceeds acceptable limits to a point where external maintenance balancing is required to restore battery performance" 3 "Cell-to-cell voltage differential exceeds acceptable limits to a point where external maintenance balancing cannot restore battery performance" 4 "Cell-to-cell voltage differential exceeds acceptable limits" 14 "Error" 15 "Not Available" ;
VAL_ 2364576510 HVES1CellTemperatureDiffStatus 0 "Cell-to-cell temperature differential is within acceptable limits" 1 "Cell-to-cell temperature differential exceeds acceptable limits" 2 "Error" 3 "Not Available" ;
VAL_ 2364577534 HVES1HghVoltageBusPosContactStat 0 "Contactor Open" 1 "Contactor Closed" 2 "Error" 3 "Not Available" ;
VAL_ 2364577534 HVES1HghVoltageBusNegContactStat 0 "Contactor Open" 1 "Contactor Closed" 2 "Error" 3 "Not Available" ;
VAL_ 2364577534 HVES1HghVoltageBusDiscnnctFrwrng 0 "Disconnect not pending" 1 "Disconnect imminent due to battery pack voltage approaching minimum acceptable level" 2 "Disconnect imminent due to battery pack voltage approaching maximum acceptable level" 3 "Disconnect imminent due to module voltage approaching minimum acceptable level" 4 "Disconnect imminent due to module voltage approaching maximum acceptable level" 5 "Disconnect imminent due to cell voltage approaching minimum acceptable level" 6 "Disconnect imminent due to cell voltage approaching maximum acceptable level" 7 "Disconnect imminent due to battery pack current approaching maximum acceptable level" 13 "Disconnect imminent" 14 "Error" 15 "Not Available" ;
VAL_ 2364577534 HVES1HghVltgBusPreChrgRelyStat 0 "Relay Open" 1 "Relay Closed" 2 "Error" 3 "Not Available" ;
VAL_ 2364577534 HVES1CenterOfPackContactorState 0 "Contactor Open" 1 "Contactor Closed" 2 "Error" 3 "Not Available" ;
VAL_ 2364577534 HVES1HiVltgBusActIsolatnTestStat 0 "No test requested / No test in process" 1 "Test requested but not yet in process" 2 "Test in process" 3 "Test complete - isolation acceptable" 4 "Test complete - isolation marginal" 5 "Test complete - isolation fault" 14 "Error" 15 "Not available" ;
VAL_ 2364577534 HVES1HiVltgBusPassIsolatnTestSt 0 "No test requested / No test in process" 1 "Test requested but not yet in process" 2 "Test in process" 3 "Test complete - isolation acceptable" 4 "Test complete - isolation marginal" 5 "Test complete - isolation fault" 14 "Error" 15 "Not available" ;
VAL_ 2364577534 HVES1HVILStatus 0 "HVIL Closed" 1 "HVIL Open" 2 "Error" 3 "Not Available" ;
VAL_ 2364577534 HVES1InertiaSwitchStatus 0 "No impact sensed" 1 "Impact sensed" 2 "Error" 3 "Not Available" ;
VAL_ 2364577534 HVES1StateOfChargeStatus 0 "SOC level is acceptable." 1 "SOC is approaching its recommended lower limit" 2 "SOC is at its recommended lower limit" 3 "SOC is below its recommended lower limit" 4 "SOC is approaching its recommended upper limit" 5 "SOC is at its recommended upper limit" 6 "SOC is above its recommended upper limit" 14 "Error" 15 "Not  Available" ;
VAL_ 2364577534 HVES1CellBalanceStatus 0 "Cells are balanced" 1 "Cells are unbalanced" 2 "Error" 3 "Not Available" ;
VAL_ 2364577534 HVES1CellBalancingActive 0 "Cell balancing is not active" 1 "Cell balancing is active" 2 "Error" 3 "Not Available" ;
VAL_ 2364577534 HVES1InternalChargerStatus 0 "Charging off" 1 "Charging on" 2 "Error" 3 "Not Available" ;
VAL_ 2364592382 EngCyl1ExcludeFrmCombustionRq 0 "Exclude from Combustion" 1 "Include for Combustion" 2 "Reserved" 3 "Not available/Do not care" ;
VAL_ 2364592382 EngCyl2ExcludeFrmCombustionRq 0 "Exclude from Combustion" 1 "Include for Combustion" 2 "Reserved" 3 "Not available/Do not care" ;
VAL_ 2364592382 EngCyl3ExcludeFrmCombustionRq 0 "Exclude from Combustion" 1 "Include for Combustion" 2 "Reserved" 3 "Not available/Do not care" ;
VAL_ 2364592382 EngCyl4ExcludeFrmCombustionRq 0 "Exclude from Combustion" 1 "Include for Combustion" 2 "Reserved" 3 "Not available/Do not care" ;
VAL_ 2364592382 EngCyl5ExcludeFrmCombustionRq 0 "Exclude from Combustion" 1 "Include for Combustion" 2 "Reserved" 3 "Not available/Do not care" ;
VAL_ 2364592382 EngCyl6ExcludeFrmCombustionRq 0 "Exclude from Combustion" 1 "Include for Combustion" 2 "Reserved" 3 "Not available/Do not care" ;
VAL_ 2364592382 EngCyl7ExcludeFrmCombustionRq 0 "Exclude from Combustion" 1 "Include for Combustion" 2 "Reserved" 3 "Not available/Do not care" ;
VAL_ 2364592382 EngCyl8ExcludeFrmCombustionRq 0 "Exclude from Combustion" 1 "Include for Combustion" 2 "Reserved" 3 "Not available/Do not care" ;
VAL_ 2364592382 EngCyl9ExcludeFrmCombustionRq 0 "Exclude from Combustion" 1 "Include for Combustion" 2 "Reserved" 3 "Not available/Do not care" ;
VAL_ 2364592382 EngCyl10ExcludeFrmCombustionRq 0 "Exclude from Combustion" 1 "Include for Combustion" 2 "Reserved" 3 "Not available/Do not care" ;
VAL_ 2364592382 EngCyl11ExcludeFrmCombustionRq 0 "Exclude from Combustion" 1 "Include for Combustion" 2 "Reserved" 3 "Not available/Do not care" ;
VAL_ 2364592382 EngCyl12ExcludeFrmCombustionRq 0 "Exclude from Combustion" 1 "Include for Combustion" 2 "Reserved" 3 "Not available/Do not care" ;
VAL_ 2364592382 EngCyl13ExcludeFrmCombustionRq 0 "Exclude from Combustion" 1 "Include for Combustion" 2 "Reserved" 3 "Not available/Do not care" ;
VAL_ 2364592382 EngCyl14ExcludeFrmCombustionRq 0 "Exclude from Combustion" 1 "Include for Combustion" 2 "Reserved" 3 "Not available/Do not care" ;
VAL_ 2364592382 EngCyl15ExcludeFrmCombustionRq 0 "Exclude from Combustion" 1 "Include for Combustion" 2 "Reserved" 3 "Not available/Do not care" ;
VAL_ 2364592382 EngCyl16ExcludeFrmCombustionRq 0 "Exclude from Combustion" 1 "Include for Combustion" 2 "Reserved" 3 "Not available/Do not care" ;
VAL_ 2364592382 EngCyl17ExcludeFrmCombustionRq 0 "Exclude from Combustion" 1 "Include for Combustion" 2 "Reserved" 3 "Not available/Do not care" ;
VAL_ 2364592382 EngCyl18ExcludeFrmCombustionRq 0 "Exclude from Combustion" 1 "Include for Combustion" 2 "Reserved" 3 "Not available/Do not care" ;
VAL_ 2364592382 EngCyl19ExcludeFrmCombustionRq 0 "Exclude from Combustion" 1 "Include for Combustion" 2 "Reserved" 3 "Not available/Do not care" ;
VAL_ 2364592382 EngCyl20ExcludeFrmCombustionRq 0 "Exclude from Combustion" 1 "Include for Combustion" 2 "Reserved" 3 "Not available/Do not care" ;
VAL_ 2364592382 EngCyl21ExcludeFrmCombustionRq 0 "Exclude from Combustion" 1 "Include for Combustion" 2 "Reserved" 3 "Not available/Do not care" ;
VAL_ 2364592382 EngCyl22ExcludeFrmCombustionRq 0 "Exclude from Combustion" 1 "Include for Combustion" 2 "Reserved" 3 "Not available/Do not care" ;
VAL_ 2364592382 EngCyl23ExcludeFrmCombustionRq 0 "Exclude from Combustion" 1 "Include for Combustion" 2 "Reserved" 3 "Not available/Do not care" ;
VAL_ 2364592382 EngCyl24ExcludeFrmCombustionRq 0 "Exclude from Combustion" 1 "Include for Combustion" 2 "Reserved" 3 "Not available/Do not care" ;
VAL_ 2364592638 EngCylHeadBypssActr1TempStat 0 "High Most severe" 1 "High Least severe" 2 "In Range" 3 "Low Least severe" 4 "Low Most severe" 5 "Not Defined" 6 "Error" 7 "Not available" ;
VAL_ 2364592638 EngCylHeadBypssActr1OpStatus 0 "Normal" 1 "Alarm" 2 "Alarm High Severity" 3 "Derate Active" 4 "Controlled Shutdown Active" 5 "Uncontrolled Shutdown Active" 6 "Calibration in Progress" 14 "Error" 15 "Not available" ;
VAL_ 2364592894 EngineIntakeAirSourceValve 0 "Off" 1 "On" 2 "Error" 3 "Not available" ;
VAL_ 2364593150 PredictiveCruiseControlState 0 "Disabled" 1 "Enabled" 2 "Enabled, but not functional due to vehicle position not available" 3 "Enabled, but not functional due to map position not available" 4 "Enabled, but not functional due to road grade info not available" 5 "Enabled, but not functional due to predicted path not available" 6 "Enabled, but not functional due to vehicle speed below speed threshold" 7 "Enabled, but not functional due to inhibited by driver" 8 "Enabled, but not functional due to self test" 14 "Error" 15 "Not Available" ;
VAL_ 2364593150 VehicleSpeedCtrlOverrideRequest 0 "No speed control override requested" 1 "Speed control override requested" 2 "Reserved" 3 "Don't care/take no action" ;
VAL_ 2364593150 PredictiveCruiseCtrlEventInRange 0 "No PCC event in range" 1 "PCC event in range" 2 "Error" 3 "Not available" ;
VAL_ 2364593150 PredictCrsCtrlSpeedEvntIndictr 0 "No speed event is active" 1 "Increased speed event is active" 2 "Decreased speed event is active" 3 "Not available" ;
VAL_ 2364593150 VehicleSpdCtrlOverrdEvntIndictr 0 "Speed Control event is not active" 1 "Speed Control event is active" 2 "Reserved" 3 "Not available" ;
VAL_ 2364593150 PredictCrsCtrlDrvlineDisengInhRq 0 "No Inhibit Request" 1 "Driveline Disengage Inhibit Request" 2 "Reserved" 3 "Don't care/take no action" ;
VAL_ 2565920510 API1Output1Device1Status 0 "On" 1 "Off" 2 "Faulted On" 3 "Faulted Off" 4 "Reserved for SAE Assignment" 5 "Reserved for SAE Assignment" 6 "Error" 7 "Not Available" ;
VAL_ 2565920510 API1Output1Device2Status 0 "On" 1 "Off" 2 "Faulted On" 3 "Faulted Off" 4 "Reserved for SAE Assignment" 5 "Reserved for SAE Assignment" 6 "Error" 7 "Not Available" ;
VAL_ 2565920510 API1Output1EnableCommand 0 "Turn API Output Off" 1 "Turn API Output On" 2 "Reserved" 3 "Not Available" ;
VAL_ 2565920766 API1Output1StatusFeedback 0 "Output Off" 1 "Output On" 2 "Output Faulted On" 3 "Output Faulted Off" 4 "Reserved for SAE Assignment" 5 "Reserved for SAE Assignment" 6 "Error" 7 "Not Available" ;
VAL_ 2565920766 API1Output1LoadshedRequest 0 "No Loadshed Requested" 1 "Loadshed Requested" 2 "Loadshed Requested, Shutdown Imminent" 3 "Don't Care/Take No Action" ;
VAL_ 2565920766 API1Output1HVILStatus 0 "HVIL Closed" 1 "HVIL Open" 2 "Error" 3 "Not Available" ;
VAL_ 2565921534 API1Output2Device1Status 0 "On" 1 "Off" 2 "Faulted On" 3 "Faulted Off" 4 "Reserved for SAE Assignment" 5 "Reserved for SAE Assignment" 6 "Error" 7 "Not Available" ;
VAL_ 2565921534 API1Output2Device2Status 0 "On" 1 "Off" 2 "Faulted On" 3 "Faulted Off" 4 "Reserved for SAE Assignment" 5 "Reserved for SAE Assignment" 6 "Error" 7 "Not Available" ;
VAL_ 2565921534 API1Output2EnableCommand 0 "Turn API Output Off" 1 "Turn API Output On" 2 "Reserved" 3 "Not Available" ;
VAL_ 2565921790 API1Output2StatusFeedback 0 "Output Off" 1 "Output On" 2 "Output Faulted On" 3 "Output Faulted Off" 4 "Reserved for SAE Assignment" 5 "Reserved for SAE Assignment" 6 "Error" 7 "Not Available" ;
VAL_ 2565921790 API1Output2LoadshedRequest 0 "No Loadshed Requested" 1 "Loadshed Requested" 2 "Loadshed Requested, Shutdown Imminent" 3 "Don't Care/Take No Action" ;
VAL_ 2565921790 API1Output2HVILStatus 0 "HVIL Closed" 1 "HVIL Open" 2 "Error" 3 "Not Available" ;
VAL_ 2565922558 API1Output3Device1Status 0 "On" 1 "Off" 2 "Faulted On" 3 "Faulted Off" 4 "Reserved for SAE Assignment" 5 "Reserved for SAE Assignment" 6 "Error" 7 "Not Available" ;
VAL_ 2565922558 API1Output3Device2Status 0 "On" 1 "Off" 2 "Faulted On" 3 "Faulted Off" 4 "Reserved for SAE Assignment" 5 "Reserved for SAE Assignment" 6 "Error" 7 "Not Available" ;
VAL_ 2565922558 API1Output3EnableCommand 0 "Turn API Output Off" 1 "Turn API Output On" 2 "Reserved" 3 "Not Available" ;
VAL_ 2565922814 API1Output3StatusFeedback 0 "Output Off" 1 "Output On" 2 "Output Faulted On" 3 "Output Faulted Off" 4 "Reserved for SAE Assignment" 5 "Reserved for SAE Assignment" 6 "Error" 7 "Not Available" ;
VAL_ 2565922814 API1Output3LoadshedRequest 0 "No Loadshed Requested" 1 "Loadshed Requested" 2 "Loadshed Requested, Shutdown Imminent" 3 "Don't Care/Take No Action" ;
VAL_ 2565922814 API1Output3HVILStatus 0 "HVIL Closed" 1 "HVIL Open" 2 "Error" 3 "Not Available" ;
VAL_ 2565923582 API1Output4Device1Status 0 "On" 1 "Off" 2 "Faulted On" 3 "Faulted Off" 4 "Reserved for SAE Assignment" 5 "Reserved for SAE Assignment" 6 "Error" 7 "Not Available" ;
VAL_ 2565923582 API1Output4Device2Status 0 "On" 1 "Off" 2 "Faulted On" 3 "Faulted Off" 4 "Reserved for SAE Assignment" 5 "Reserved for SAE Assignment" 6 "Error" 7 "Not Available" ;
VAL_ 2565923582 API1Output4EnableCommand 0 "Turn API Output Off" 1 "Turn API Output On" 2 "Reserved" 3 "Not Available" ;
VAL_ 2565923838 API1Output4StatusFeedback 0 "Output Off" 1 "Output On" 2 "Output Faulted On" 3 "Output Faulted Off" 4 "Reserved for SAE Assignment" 5 "Reserved for SAE Assignment" 6 "Error" 7 "Not Available" ;
VAL_ 2565923838 API1Output4LoadshedRequest 0 "No Loadshed Requested" 1 "Loadshed Requested" 2 "Loadshed Requested, Shutdown Imminent" 3 "Don't Care/Take No Action" ;
VAL_ 2565923838 API1Output4HVILStatus 0 "HVIL Closed" 1 "HVIL Open" 2 "Error" 3 "Not Available" ;
VAL_ 2565925374 Aftrtrtmnt1IntkGsSensor2PwrInRng 0 "Not in range" 1 "In range" 2 "Error" 3 "Not available" ;
VAL_ 2565925374 Aftrtrtmnt1IntkGsSnsr2AtTemp 0 "Not in range" 1 "In range" 2 "Error" 3 "Not available" ;
VAL_ 2565925374 Aftrtrtmnt1SCRIntkNOx2RdngStable 0 "Not stable" 1 "Stable" 2 "Error" 3 "Not available" ;
VAL_ 2565925374 Aft1IntkWdRngPrcntOxg2RdngStable 0 "Not stable" 1 "Stable" 2 "Error" 3 "Not available" ;
VAL_ 2565925374 Aftrtrtmnt1IntkGsSensor2HtrCtrl 0 "Automatic" 1 "Preheat 2" 2 "Preheat 1" 3 "Heater off" ;
VAL_ 2565925374 Aft1IntkNOxSnsr2SelfDiagnssStat 0 "Diagnosis not active" 1 "NOx Sensor ATI1 Self Diagnosis active flag" 2 "NOx Sensor ATI1 Self Diagnosis Result Complete" 3 "NOx Sensor ATI1 Self Diagnosis aborted" 4 "NOx Sensor ATI1 Self Diagnosis not possible" 7 "Not Supported" ;
VAL_ 2565925630 Aftrtrtmnt1OtltGsSensor2PwrInRng 0 "Not in range" 1 "In range" 2 "Error" 3 "Not available" ;
VAL_ 2565925630 Aftrtrtmnt1OtltGsSnsr2AtTemp 0 "Not in range" 1 "In range" 2 "Error" 3 "Not available" ;
VAL_ 2565925630 Aftrtrtmnt1OtltNOx2ReadingStable 0 "Not stable" 1 "Stable" 2 "Error" 3 "Not available" ;
VAL_ 2565925630 Aft1OtltWdRngPrcntOxg2RdngStable 0 "Not stable" 1 "Stable" 2 "Error" 3 "Not available" ;
VAL_ 2565925630 Aftrtrtmnt1OtltGsSensor2HtrCtrl 0 "Automatic" 1 "Preheat 2" 2 "Preheat 1" 3 "Heater off" ;
VAL_ 2565925630 Aft1OtltNOxSnsr2SelfDiagnssStat 0 "Diagnosis not active" 1 "NOx Sensor ATO1 Self Diagnosis active flag" 2 "NOx Sensor ATO1 Self Diagnosis Result Complete" 3 "NOx Sensor ATO1 Self Diagnosis aborted" 4 "NOx Sensor ATO1 Self Diagnosis not possible" 7 "Not Supported" ;
VAL_ 2565925886 Aftrtrtmnt2IntkGsSensor2PwrInRng 0 "Not in range" 1 "In range" 2 "Error" 3 "Not available" ;
VAL_ 2565925886 Aftrtrtmnt2IntkGsSnsr2AtTemp 0 "Not in range" 1 "In range" 2 "Error" 3 "Not available" ;
VAL_ 2565925886 Aftrtrtmnt2SCRIntkNOx2RdngStable 0 "Not stable" 1 "Stable" 2 "Error" 3 "Not available" ;
VAL_ 2565925886 Aft2IntkWdRngPrcntOxg2RdngStable 0 "Not stable" 1 "Stable" 2 "Error" 3 "Not available" ;
VAL_ 2565925886 Aftrtrtmnt2IntkGsSensor2HtrCtrl 0 "Automatic" 1 "Preheat 2" 2 "Preheat 1" 3 "Heater off" ;
VAL_ 2565925886 Aft2IntkNOxSnsr2SelfDiagnssStat 0 "Diagnosis not active" 1 "NOx Sensor ATI2 Self Diagnosis active flag" 2 "NOx Sensor ATI2 Self Diagnosis Result Complete" 3 "NOx Sensor ATI2 Self Diagnosis aborted" 4 "NOx Sensor ATI2 Self Diagnosis not possible" 7 "Not Supported" ;
VAL_ 2565926142 Aftrtrtmnt2OtltGsSensor2PwrInRng 0 "Not in range" 1 "In range" 2 "Error" 3 "Not available" ;
VAL_ 2565926142 Aftrtrtmnt2OtltGsSnsr2AtTemp 0 "Not in range" 1 "In range" 2 "Error" 3 "Not available" ;
VAL_ 2565926142 Aftrtrtmnt2OtltNOx2ReadingStable 0 "Not stable" 1 "Stable" 2 "Error" 3 "Not available" ;
VAL_ 2565926142 Aft2OtltWdRngPrcntOxg2RdngStable 0 "Not stable" 1 "Stable" 2 "Error" 3 "Not available" ;
VAL_ 2565926142 Aftrtrtmnt2OtltGsSensor2HtrCtrl 0 "Automatic" 1 "Preheat 2" 2 "Preheat 1" 3 "Heater off" ;
VAL_ 2565926142 Aft2OtltNOxSnsr2SelfDiagnssStat 0 "Diagnosis not active" 1 "NOx Sensor ATO2 Self Diagnosis active flag" 2 "NOx Sensor ATO2 Self Diagnosis Result Complete" 3 "NOx Sensor ATO2 Self Diagnosis aborted" 4 "NOx Sensor ATO2 Self Diagnosis not possible" 7 "Not Supported" ;
VAL_ 2431708670 EngineStartRequest 0 "Start not requested" 1 "Start requested, operator type" 2 "Start requested, automatic type" 3 "Not available" ;
VAL_ 2431708670 EngineStartConsent 0 "No consent" 1 "Consent to operator-requested start only" 2 "Consent to automatic start only" 3 "Consent to both, operator-requested and automatic start" 7 "Not available" ;
VAL_ 2431708670 TrnsmShftSlctorRqedVhclDirection 0 "No direction selected - Park" 1 "No direction selected - Neutral" 2 "Forward direction selected" 3 "Reverse direction selected" 6 "Error" 7 "Not supported" ;
VAL_ 2431708670 EngineStartAbortRequest 0 "Abort not requested" 1 "Abort requested" 2 "Reserved" 3 "Don't care / Take no action" ;
VAL_ 2431708670 EngineStarter1Feedback 0 "Starter not commanded" 1 "Starter command latched, starter active" 2 "Starter command unlatched, start completed" 3 "Starter command unlatched, start abort command received from arbitrator" 4 "Starter command unlatched, start aborted by starter controller" 7 "Not available" ;
VAL_ 2431708670 EngineStarter2Feedback 0 "Starter not commanded" 1 "Starter command latched, starter active" 2 "Starter command unlatched, start completed" 3 "Starter command unlatched, start abort command received from arbitrator" 4 "Starter command unlatched, start aborted by starter controller" 7 "Not available" ;
VAL_ 2431710718 EngineStartControlMessageRate 0 "Once every 20 ms" 1 "Once every 250 ms or on change but no faster than 20 ms" 2 "Reserved" 3 "Not available" ;
VAL_ 2431710718 EngineStarterCommand 0 "Command not active" 1 "Command active for starter 1" 2 "Command active for starter 2" 3 "Command withdrawn - abort engine start" 7 "Don't care / Take no action" ;
VAL_ 2431710718 EngineStartRequestLatchStatus 0 "Start request not received" 1 "Start request latched - waiting for consent" 2 "Start request latched - consent confirmed, starter commanded" 3 "Start request unlatched - start completed" 4 "Start request unlatched - consent not established within allowed time" 5 "Start request unlatched - start aborted due to abort request" 6 "Start request unlatched - start could not be completed because the starter command was not successful" 15 "Not available" ;
VAL_ 2431710718 OperatorEngineStartConsntSummary 0 "No consent" 1 "Consent" 2 "Error" 3 "Not available" ;
VAL_ 2431710718 AutoEngineStartConsentSummary 0 "No consent" 1 "Consent" 2 "Error" 3 "Not available" ;
VAL_ 2364604414 FrontHitchRollLimitState 0 "Not limited" 1 "Operator limited/controlled" 2 "Limited High" 3 "Limited Low" 4 "Reserved" 5 "Reserved" 6 "Non recoverable fault" 7 "Not available" ;
VAL_ 2364604414 FrontHitchRollExitReasonCode 0 "No reason/all clear" 1 "Required level of operator presence/awareness not detected" 2 "Implement released control of function" 3 "Operator override of function" 4 "Operator control not in valid position" 5 "Remote command timeout" 6 "Remote command out of range/invalid" 7 "Function not calibrated" 8 "Operator control fault" 9 "Function fault" 20 "Hydraulic oil level too low" 21 "Hitch locked out" 62 "Error" 63 "Not available" ;
VAL_ 2364604414 FrontHitchPitchLimitState 0 "Not limited" 1 "Operator limited/controlled" 2 "Limited High" 3 "Limited Low" 4 "Reserved" 5 "Reserved" 6 "Non recoverable fault" 7 "Not available" ;
VAL_ 2364604414 FrontHitchPitchExitReasonCode 0 "No reason/all clear" 1 "Required level of operator presence/awareness not detected" 2 "Implement released control of function" 3 "Operator override of function" 4 "Operator control not in valid position" 5 "Remote command timeout" 6 "Remote command out of range/invalid" 7 "Function not calibrated" 8 "Operator control fault" 9 "Function fault" 20 "Hydraulic oil level too low" 21 "Hitch locked out" 62 "Error" 63 "Not available" ;
VAL_ 2364604926 RearHitchRollLimitState 0 "Not limited" 1 "Operator limited/controlled" 2 "Limited High" 3 "Limited Low" 4 "Reserved" 5 "Reserved" 6 "Non recoverable fault" 7 "Not available" ;
VAL_ 2364604926 RearHitchRollExitReasonCode 0 "No reason/all clear" 1 "Required level of operator presence/awareness not detected" 2 "Implement released control of function" 3 "Operator override of function" 4 "Operator control not in valid position" 5 "Remote command timeout" 6 "Remote command out of range/invalid" 7 "Function not calibrated" 8 "Operator control fault" 9 "Function fault" 20 "Hydraulic oil level too low" 21 "Hitch locked out" 62 "Error" 63 "Not available" ;
VAL_ 2364604926 RearHitchPitchLimitState 0 "Not limited" 1 "Operator limited/controlled" 2 "Limited High" 3 "Limited Low" 4 "Reserved" 5 "Reserved" 6 "Non recoverable fault" 7 "Not available" ;
VAL_ 2364604926 RearHitchPitchExitReasonCode 0 "No reason/all clear" 1 "Required level of operator presence/awareness not detected" 2 "Implement released control of function" 3 "Operator override of function" 4 "Operator control not in valid position" 5 "Remote command timeout" 6 "Remote command out of range/invalid" 7 "Function not calibrated" 8 "Operator control fault" 9 "Function fault" 20 "Hydraulic oil level too low" 21 "Hitch locked out" 62 "Error" 63 "Not available" ;
VAL_ 2364606718 HVES1Module1OperationalStatus 0 "Not Operational" 1 "Operational" 2 "Error" 3 "Not Available" ;
VAL_ 2364606718 HVES1Module2OperationalStatus 0 "Not Operational" 1 "Operational" 2 "Error" 3 "Not Available" ;
VAL_ 2364606718 HVES1Module3OperationalStatus 0 "Not Operational" 1 "Operational" 2 "Error" 3 "Not Available" ;
VAL_ 2364606718 HVES1Module4OperationalStatus 0 "Not Operational" 1 "Operational" 2 "Error" 3 "Not Available" ;
VAL_ 2364606718 HVES1Module5OperationalStatus 0 "Not Operational" 1 "Operational" 2 "Error" 3 "Not Available" ;
VAL_ 2364606718 HVES1Module6OperationalStatus 0 "Not Operational" 1 "Operational" 2 "Error" 3 "Not Available" ;
VAL_ 2364606718 HVES1Module7OperationalStatus 0 "Not Operational" 1 "Operational" 2 "Error" 3 "Not Available" ;
VAL_ 2364606718 HVES1Module8OperationalStatus 0 "Not Operational" 1 "Operational" 2 "Error" 3 "Not Available" ;
VAL_ 2364606718 HVES1Module9OperationalStatus 0 "Not Operational" 1 "Operational" 2 "Error" 3 "Not Available" ;
VAL_ 2364606718 HVES1Module10OperationalStatus 0 "Not Operational" 1 "Operational" 2 "Error" 3 "Not Available" ;
VAL_ 2364606718 HVES1Module11OperationalStatus 0 "Not Operational" 1 "Operational" 2 "Error" 3 "Not Available" ;
VAL_ 2364606718 HVES1Module12OperationalStatus 0 "Not Operational" 1 "Operational" 2 "Error" 3 "Not Available" ;
VAL_ 2364606718 HVES1Module13OperationalStatus 0 "Not Operational" 1 "Operational" 2 "Error" 3 "Not Available" ;
VAL_ 2364606718 HVES1Module14OperationalStatus 0 "Not Operational" 1 "Operational" 2 "Error" 3 "Not Available" ;
VAL_ 2364606718 HVES1Module15OperationalStatus 0 "Not Operational" 1 "Operational" 2 "Error" 3 "Not Available" ;
VAL_ 2364606718 HVES1Module16OperationalStatus 0 "Not Operational" 1 "Operational" 2 "Error" 3 "Not Available" ;
VAL_ 2364606974 HVES1ThermalMangmntSystemHtrStat 0 "Heater Off" 1 "Heater On" 2 "Error " 3 "Not Available" ;
VAL_ 2364606974 HVES1ThermalManagementSystemMode 0 "Off" 1 "Circulating" 2 "Cooling" 3 "Heating" 4 "Drying" 14 "Faulted" 15 "Not Available" ;
VAL_ 2297499902 BrakePedalSwitch2 0 "Brake pedal released" 1 "Brake pedal depressed" 2 "Error" 3 "Not Available" ;
VAL_ 2364609278 DCDC1OperationalCommand 0 "Disable" 1 "Operate in standby mode" 2 "Operate in buck mode" 3 "Operate in boost mode" 15 "Don't care/ Take No Action" ;
VAL_ 2364609534 DCDC1OperationalStatus 0 "Disabled " 1 "Initialization in process" 2 "Operational - Standby" 3 "Operational - Buck mode" 4 "Operational - Boost mode" 5 "Normal power down in process  " 6 "Disabled due to malfunction or protection" 13 "Manufacturer assignable state" 14 "Error" 15 "Not Available" ;
VAL_ 2364609534 DCDC1HVILStatus 0 "HVIL Closed" 1 "HVIL Open" 2 "Error" 3 "Not Available" ;
VAL_ 2364609534 DCDC1LoadshedRequest 0 "No Loadshed Requested" 1 "Loadshed Requested" 2 "Loadshed Requested, Shutdown Imminent" 3 "Don't Care/Take No Action" ;
VAL_ 2364609534 DCDC1PowerLimitDueToHighSideCurr 0 "No power limit for this reason" 1 "Power limited for this reason" 2 "Error" 3 "Not Available" ;
VAL_ 2364609534 DCDC1PowerLimitDueToLowSideCurr 0 "No power limit for this reason" 1 "Power limited for this reason" 2 "Error" 3 "Not Available" ;
VAL_ 2364609534 DCDC1PowerLmtDTHghSideVoltageMin 0 "No power limit for this reason" 1 "Power limited for this reason" 2 "Error" 3 "Not Available" ;
VAL_ 2364609534 DCDC1PowerLmtDTHghSideVoltageMax 0 "No power limit for this reason" 1 "Power limited for this reason" 2 "Error" 3 "Not Available" ;
VAL_ 2364609534 DCDC1PowerLmtDTLowSideVoltageMin 0 "No power limit for this reason" 1 "Power limited for this reason" 2 "Error" 3 "Not Available" ;
VAL_ 2364609534 DCDC1PowerLmtDTLowSideVoltageMax 0 "No power limit for this reason" 1 "Power limited for this reason" 2 "Error" 3 "Not Available" ;
VAL_ 2364609534 DCDC1PwrLmtDTCtrllerTemperature 0 "No power limit for this reason" 1 "Power limited for this reason" 2 "Error" 3 "Not Available" ;
VAL_ 2364609534 DCDC1PwrLmtDTElctrncFilterTemp 0 "No power limit for this reason" 1 "Power limited for this reason" 2 "Error" 3 "Not Available" ;
VAL_ 2364609534 DCDC1PwrLmtDTPwrElctrncsTemp 0 "No power limit for this reason" 1 "Power limited for this reason" 2 "Error" 3 "Not Available" ;
VAL_ 2364609534 DCDC1PwrLmtDTSLIBattTerminalVltg 0 "No power limit for this reason" 1 "Power limited for this reason" 2 "Error" 3 "Not Available" ;
VAL_ 2364609534 DCDC1PwrLmtDTSLIBattTerminalCurr 0 "No power limit for this reason" 1 "Power limited for this reason" 2 "Error" 3 "Not Available" ;
VAL_ 2364609534 DCDC1PwrLmtDTSLIBattTerminalTemp 0 "No power limit for this reason" 1 "Power limited for this reason" 2 "Error" 3 "Not Available" ;
VAL_ 2364609534 DCDC1PowerLimitDTUndefinedReason 0 "No power limit for this reason" 1 "Power limited for this reason" 2 "Error" 3 "Not Available" ;
VAL_ 2431719166 WellStimulationPmpCavitationStat 0 "No Cavitation" 1 "Low" 2 "Medium" 3 "High" 4 "Reserved" 5 "Reserved" 6 "Error" 7 "Not Available" ;
VAL_ 2431719166 WellStimultnPmpFldEndValveLeak 0 "No Leak Detected" 1 "Leak Detected" 2 "Error" 3 "Not Available" ;
VAL_ 2566639102 WellStimPmpPlungerFiringOrderStt 0 "Firing order 1-2-3" 1 "Firing order 1-5-2-3-4" 14 "Error" 15 "Not available" ;
VAL_ 2633748222 ReceiveSPNsPort 0 "Current port" 1 "Port 1" 2 "Port 2" 3 "Port 3" 4 "Port 4" 5 "Port 5" 6 "Port 6" 7 "Port 7" 8 "Port 8" 9 "Port 9" 10 "Port 10" ;
VAL_ 2633748222 ReceiveSPNsPortCommandStatus 0 "Positive Acknowledgment" 1 "Negative Acknowledgment" 2 "No Configurable SPNs exist" 7 "Not available" ;
VAL_ 2633748222 ConfigurableReceiveSPNModifiedSt 0 "SPN's receive status could not be modified." 1 "SPN's receive status was not requested to be modified." 2 "SPN's receive status could be modified as requested." 3 "Not available" ;
